VERSION "2021.24.4"

NS_ :

BS_:

BU_: VEH CH Receiver X

BA_DEF_ BO_ "GenMsgSendType" ENUM "Cyclic";
BA_DEF_ BO_ "GenMsgCycleTime" INT 0 10000;

BO_ 1083 VCSEC_peripheralOTAStatus: 8 Vector__XXX
 SG_ VCSEC_TPMSUpdateRetryLimitReached0 m0 : 59|1@1+ (1,0) [0|0] "" Vector__XXX
 SG_ VCSEC_TPMSUpdateRetryLimitReached1 m1 : 59|1@1+ (1,0) [0|0] "" Vector__XXX
 SG_ VCSEC_TPMSUpdateRetryLimitReached2 m2 : 59|1@1+ (1,0) [0|0] "" Vector__XXX
 SG_ VCSEC_TPMSUpdateRetryLimitReached3 m3 : 59|1@1+ (1,0) [0|0] "" Vector__XXX
 SG_ VCSEC_TPMSUpdateHasStarted0 m0 : 58|1@1+ (1,0) [0|0] "" Vector__XXX
 SG_ VCSEC_TPMSUpdateHasStarted1 m1 : 58|1@1+ (1,0) [0|0] "" Vector__XXX
 SG_ VCSEC_TPMSUpdateHasStarted2 m2 : 58|1@1+ (1,0) [0|0] "" Vector__XXX
 SG_ VCSEC_TPMSUpdateHasStarted3 m3 : 58|1@1+ (1,0) [0|0] "" Vector__XXX
 SG_ VCSEC_TPMSUpdateHasUpdated0 m0 : 57|1@1+ (1,0) [0|0] "" Vector__XXX
 SG_ VCSEC_TPMSUpdateHasUpdated1 m1 : 57|1@1+ (1,0) [0|0] "" Vector__XXX
 SG_ VCSEC_TPMSUpdateHasUpdated2 m2 : 57|1@1+ (1,0) [0|0] "" Vector__XXX
 SG_ VCSEC_TPMSUpdateHasUpdated3 m3 : 57|1@1+ (1,0) [0|0] "" Vector__XXX
 SG_ VCSEC_keyWhitelistIndexBeingUpdated m4 : 57|5@1+ (1,0) [0|0] "" Vector__XXX
 SG_ VCSEC_KeyfobUpdateExpectReconnect m4 : 56|1@1+ (1,0) [0|0] "" Vector__XXX
 SG_ VCSEC_TPMSUpdateExpectReconnect0 m0 : 56|1@1+ (1,0) [0|0] "" Vector__XXX
 SG_ VCSEC_TPMSUpdateExpectReconnect1 m1 : 56|1@1+ (1,0) [0|0] "" Vector__XXX
 SG_ VCSEC_TPMSUpdateExpectReconnect2 m2 : 56|1@1+ (1,0) [0|0] "" Vector__XXX
 SG_ VCSEC_TPMSUpdateExpectReconnect3 m3 : 56|1@1+ (1,0) [0|0] "" Vector__XXX
 SG_ VCSEC_KeyfobUpdateWaitForFlashCount m4 : 52|4@1+ (1,0) [0|0] "" Vector__XXX
 SG_ VCSEC_TPMSUpdateWaitForFlashCount0 m0 : 52|4@1+ (1,0) [0|0] "" Vector__XXX
 SG_ VCSEC_TPMSUpdateWaitForFlashCount1 m1 : 52|4@1+ (1,0) [0|0] "" Vector__XXX
 SG_ VCSEC_TPMSUpdateWaitForFlashCount2 m2 : 52|4@1+ (1,0) [0|0] "" Vector__XXX
 SG_ VCSEC_TPMSUpdateWaitForFlashCount3 m3 : 52|4@1+ (1,0) [0|0] "" Vector__XXX
 SG_ VCSEC_KeyfobUpdateStalledBlockCount m4 : 48|4@1+ (1,0) [0|0] "" Vector__XXX
 SG_ VCSEC_TPMSUpdateStalledBlockCount0 m0 : 48|4@1+ (1,0) [0|0] "" Vector__XXX
 SG_ VCSEC_TPMSUpdateStalledBlockCount1 m1 : 48|4@1+ (1,0) [0|0] "" Vector__XXX
 SG_ VCSEC_TPMSUpdateStalledBlockCount2 m2 : 48|4@1+ (1,0) [0|0] "" Vector__XXX
 SG_ VCSEC_TPMSUpdateStalledBlockCount3 m3 : 48|4@1+ (1,0) [0|0] "" Vector__XXX
 SG_ VCSEC_KeyfobUpdateLocationSetCount m4 : 44|4@1+ (1,0) [0|0] "" Vector__XXX
 SG_ VCSEC_TPMSUpdateLocationSetCount0 m0 : 44|4@1+ (1,0) [0|0] "" Vector__XXX
 SG_ VCSEC_TPMSUpdateLocationSetCount1 m1 : 44|4@1+ (1,0) [0|0] "" Vector__XXX
 SG_ VCSEC_TPMSUpdateLocationSetCount2 m2 : 44|4@1+ (1,0) [0|0] "" Vector__XXX
 SG_ VCSEC_TPMSUpdateLocationSetCount3 m3 : 44|4@1+ (1,0) [0|0] "" Vector__XXX
 SG_ VCSEC_KeyfobUpdateCRCRequestTimeoutCount m4 : 40|4@1+ (1,0) [0|0] "" Vector__XXX
 SG_ VCSEC_TPMSUpdateCRCRequestTimeoutCount0 m0 : 40|4@1+ (1,0) [0|0] "" Vector__XXX
 SG_ VCSEC_TPMSUpdateCRCRequestTimeoutCount1 m1 : 40|4@1+ (1,0) [0|0] "" Vector__XXX
 SG_ VCSEC_TPMSUpdateCRCRequestTimeoutCount2 m2 : 40|4@1+ (1,0) [0|0] "" Vector__XXX
 SG_ VCSEC_TPMSUpdateCRCRequestTimeoutCount3 m3 : 40|4@1+ (1,0) [0|0] "" Vector__XXX
 SG_ VCSEC_KeyfobUpdateBlockErrorCount m4 : 36|4@1+ (1,0) [0|0] "" Vector__XXX
 SG_ VCSEC_TPMSUpdateBlockErrorCount0 m0 : 36|4@1+ (1,0) [0|0] "" Vector__XXX
 SG_ VCSEC_TPMSUpdateBlockErrorCount1 m1 : 36|4@1+ (1,0) [0|0] "" Vector__XXX
 SG_ VCSEC_TPMSUpdateBlockErrorCount2 m2 : 36|4@1+ (1,0) [0|0] "" Vector__XXX
 SG_ VCSEC_TPMSUpdateBlockErrorCount3 m3 : 36|4@1+ (1,0) [0|0] "" Vector__XXX
 SG_ VCSEC_KeyfobUpdateBlockTimeoutCount m4 : 32|4@1+ (1,0) [0|0] "" Vector__XXX
 SG_ VCSEC_TPMSUpdateBlockTimeoutCount0 m0 : 32|4@1+ (1,0) [0|0] "" Vector__XXX
 SG_ VCSEC_TPMSUpdateBlockTimeoutCount1 m1 : 32|4@1+ (1,0) [0|0] "" Vector__XXX
 SG_ VCSEC_TPMSUpdateBlockTimeoutCount2 m2 : 32|4@1+ (1,0) [0|0] "" Vector__XXX
 SG_ VCSEC_TPMSUpdateBlockTimeoutCount3 m3 : 32|4@1+ (1,0) [0|0] "" Vector__XXX
 SG_ VCSEC_KeyfobUpdateLastRespStatus m4 : 24|8@1+ (1,0) [0|0] "" Vector__XXX
 SG_ VCSEC_TPMSUpdateLastStatus0 m0 : 24|8@1+ (1,0) [0|0] "" Vector__XXX
 SG_ VCSEC_TPMSUpdateLastStatus1 m1 : 24|8@1+ (1,0) [0|0] "" Vector__XXX
 SG_ VCSEC_TPMSUpdateLastStatus2 m2 : 24|8@1+ (1,0) [0|0] "" Vector__XXX
 SG_ VCSEC_TPMSUpdateLastStatus3 m3 : 24|8@1+ (1,0) [0|0] "" Vector__XXX
 SG_ VCSEC_KeyfobUpdateLastTxStatus m4 : 16|8@1+ (1,0) [0|0] "" Vector__XXX
 SG_ VCSEC_TPMSUpdateState0 m0 : 16|8@1+ (1,0) [0|0] "" Vector__XXX
 SG_ VCSEC_TPMSUpdateState1 m1 : 16|8@1+ (1,0) [0|0] "" Vector__XXX
 SG_ VCSEC_TPMSUpdateState2 m2 : 16|8@1+ (1,0) [0|0] "" Vector__XXX
 SG_ VCSEC_TPMSUpdateState3 m3 : 16|8@1+ (1,0) [0|0] "" Vector__XXX
 SG_ VCSEC_KeyfobStagingProgress m4 : 8|7@1+ (1,0) [0|0] "" Vector__XXX
 SG_ VCSEC_TPMSStagingProgress0 m0 : 8|7@1+ (1,0) [0|0] "" Vector__XXX
 SG_ VCSEC_TPMSStagingProgress1 m1 : 8|7@1+ (1,0) [0|0] "" Vector__XXX
 SG_ VCSEC_TPMSStagingProgress2 m2 : 8|7@1+ (1,0) [0|0] "" Vector__XXX
 SG_ VCSEC_TPMSStagingProgress3 m3 : 8|7@1+ (1,0) [0|0] "" Vector__XXX
 SG_ VCSEC_peripheralOTAStatusIndex M : 0|3@1+ (1,0) [0|0] "" Vector__XXX

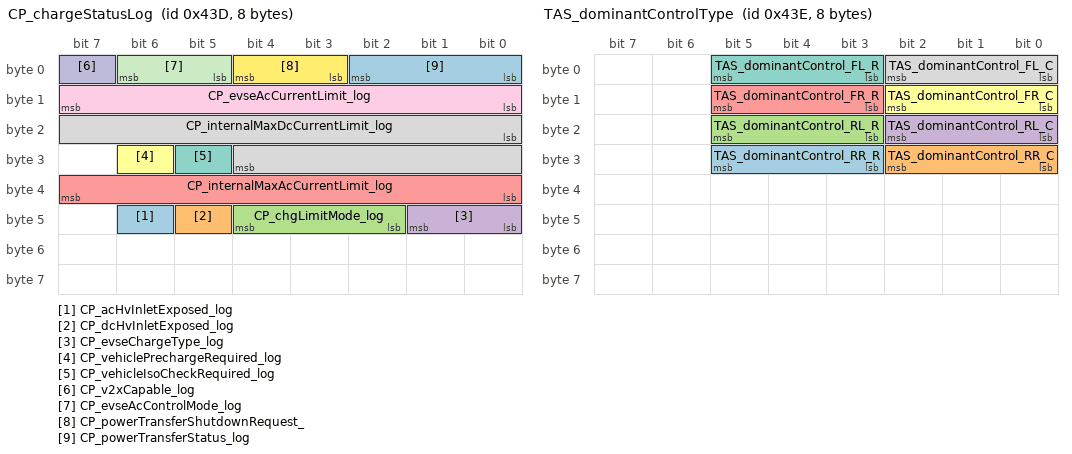
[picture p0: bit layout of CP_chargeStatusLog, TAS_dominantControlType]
BO_ 1085 CP_chargeStatusLog: 8 Vector__XXX
 SG_ CP_acHvInletExposed_log : 46|1@1+ (1,0) [0|0] "" Vector__XXX
 SG_ CP_dcHvInletExposed_log : 45|1@1+ (1,0) [0|0] "" Vector__XXX
 SG_ CP_chgLimitMode_log : 42|3@1+ (1,0) [0|0] "" Vector__XXX
 SG_ CP_evseChargeType_log : 40|2@1+ (1,0) [0|0] "" Vector__XXX
 SG_ CP_internalMaxAcCurrentLimit_log : 32|8@1+ (0.5,0) [0|0] "" Vector__XXX
 SG_ CP_vehiclePrechargeRequired_log : 30|1@1+ (1,0) [0|0] "" Vector__XXX
 SG_ CP_vehicleIsoCheckRequired_log : 29|1@1+ (1,0) [0|0] "" Vector__XXX
 SG_ CP_internalMaxDcCurrentLimit_log : 16|13@1+ (0.25,0) [0|0] "" Vector__XXX
 SG_ CP_evseAcCurrentLimit_log : 8|8@1+ (0.5,0) [0|0] "" Vector__XXX
 SG_ CP_v2xCapable_log : 7|1@1+ (1,0) [0|0] "" Vector__XXX
 SG_ CP_evseAcControlMode_log : 5|2@1+ (1,0) [0|0] "" Vector__XXX
 SG_ CP_powerTransferShutdownRequest_ : 3|2@1+ (1,0) [0|0] "" Vector__XXX
 SG_ CP_powerTransferStatus_log : 0|3@1+ (1,0) [0|0] "" Vector__XXX

BO_ 1086 TAS_dominantControlType: 8 Vector__XXX
 SG_ TAS_dominantControl_RR_R : 27|3@1+ (1,0) [0|0] "" Vector__XXX
 SG_ TAS_dominantControl_RR_C : 24|3@1+ (1,0) [0|0] "" Vector__XXX
 SG_ TAS_dominantControl_RL_R : 19|3@1+ (1,0) [0|0] "" Vector__XXX
 SG_ TAS_dominantControl_RL_C : 16|3@1+ (1,0) [0|0] "" Vector__XXX
 SG_ TAS_dominantControl_FR_R : 11|3@1+ (1,0) [0|0] "" Vector__XXX
 SG_ TAS_dominantControl_FR_C : 8|3@1+ (1,0) [0|0] "" Vector__XXX
 SG_ TAS_dominantControl_FL_R : 3|3@1+ (1,0) [0|0] "" Vector__XXX
 SG_ TAS_dominantControl_FL_C : 0|3@1+ (1,0) [0|0] "" Vector__XXX

BO_ 1089 VC_pcsInterface: 8 Vector__XXX
 SG_ VC_pcsInterfaceChecksum : 56|8@1+ (1,0) [0|0] "" Vector__XXX
 SG_ VC_pcsInterfaceCounter : 50|4@1+ (1,0) [0|0] "" Vector__XXX
 SG_ VC_pcsInterfaceMuxIndex M : 48|1@1+ (1,0) [0|0] "" Vector__XXX
 SG_ VC_LVBatteryCannotSupportVehicle m0 : 47|1@1+ (1,0) [0|0] "" Vector__XXX
 SG_ VC_goodForPCSPowerCycle m0 : 46|1@1+ (1,0) [0|0] "" Vector__XXX
 SG_ VC_lvBatteryDischargeRequest m1 : 42|1@1+ (1,0) [0|0] "" Vector__XXX
 SG_ VC_lvHwProtSelfTestActive m1 : 41|1@1+ (1,0) [0|0] "" Vector__XXX
 SG_ VC_defaultPcsLVVoltageTarget m1 : 28|13@1+ (0.01,0) [0|0] "" Vector__XXX
 SG_ VC_pcsLVMaxVoltageLimit m0 : 27|13@1+ (0.01,0) [0|0] "" Vector__XXX
 SG_ VC_pcsLVMaxDchrgCurrentLimit m1 : 16|12@1+ (0.1,0) [0|0] "" Vector__XXX
 SG_ VC_pcsLVMinVoltageLimit m0 : 13|13@1+ (0.01,0) [0|0] "" Vector__XXX
 SG_ VC_pcsLVVoltageTarget m0 : 0|13@1+ (0.01,0) [0|0] "" Vector__XXX
 SG_ VC_pcsResistanceFiltered m1 : 0|16@1+ (0.01,0) [0|0] "" Vector__XXX

BO_ 1090 VCBATT_pcsInterface: 8 Vector__XXX
 SG_ VCBATT_pcsInterfaceChecksum : 56|8@1+ (1,0) [0|0] "" Vector__XXX
 SG_ VCBATT_pcsInterfaceCounter : 50|4@1+ (1,0) [0|0] "" Vector__XXX
 SG_ VCBATT_pcsInterfaceMuxIndex M : 48|1@1+ (1,0) [0|0] "" Vector__XXX
 SG_ VCBATT_LVBatteryCannotSupportVeh m0 : 47|1@1+ (1,0) [0|0] "" Vector__XXX
 SG_ VCBATT_goodForPCSPowerCycle m0 : 46|1@1+ (1,0) [0|0] "" Vector__XXX
 SG_ VCBATT_lvBatteryDischargeRequest m1 : 42|1@1+ (1,0) [0|0] "" Vector__XXX
 SG_ VCBATT_lvHwProtSelfTestActive m1 : 41|1@1+ (1,0) [0|0] "" Vector__XXX
 SG_ VCBATT_defaultPcsLVVoltageTarget m1 : 28|13@1+ (0.01,0) [0|0] "" Vector__XXX
 SG_ VCBATT_pcsLVMaxVoltageLimit m0 : 27|13@1+ (0.01,0) [0|0] "" Vector__XXX
 SG_ VCBATT_pcsLVMaxDchrgCurrentLimit m1 : 16|12@1+ (0.1,0) [0|0] "" Vector__XXX
 SG_ VCBATT_pcsLVMinVoltageLimit m0 : 13|13@1+ (0.01,0) [0|0] "" Vector__XXX
 SG_ VCBATT_pcsLVVoltageTarget m0 : 0|13@1+ (0.01,0) [0|0] "" Vector__XXX
 SG_ VCBATT_pcsResistanceFiltered m1 : 0|16@1+ (0.01,0) [0|0] "" Vector__XXX

BO_ 1091 VC_pcsManagement: 6 Vector__XXX
 SG_ VC_dcdcLVInputPowerLimit m0 : 36|8@1+ (50,0) [0|0] "" Vector__XXX
 SG_ VC_dcdcLVVoltageTargetMin m0 : 26|10@1+ (0.1,0) [0|0] "" Vector__XXX
 SG_ VC_dcdcLVVoltageTargetMax m0 : 16|10@1+ (0.1,0) [0|0] "" Vector__XXX
 SG_ VC_pcsManagementMuxIndex M : 12|1@1+ (1,0) [0|0] "" Vector__XXX
 SG_ VC_pcsManagementCounter : 8|4@1+ (1,0) [0|0] "" Vector__XXX
 SG_ VC_pcsManagementChecksum : 0|8@1+ (1,0) [0|0] "" Vector__XXX

BO_ 1092 PCS2_alertLog: 8 Vector__XXX
 SG_ PCS2_alertSource : 60|4@1+ (1,0) [0|0] "" Vector__XXX
 SG_ PCS2_a107_packEOLGridFormEnableR m107 : 59|1@1+ (1,0) [0|0] "" Vector__XXX
 SG_ PCS2_a114_useLogarithmResult m114 : 59|1@1+ (1,0) [0|0] "" Vector__XXX
 SG_ PCS2_a153_L3_negative_flag m153 : 59|1@1+ (1,0) [0|0] "" Vector__XXX
 SG_ PCS2_a066_capacitanceOutOfSpec m66 : 58|1@1+ (1,0) [0|0] "" Vector__XXX
 SG_ PCS2_a067_capacitanceOutOfSpec m67 : 58|1@1+ (1,0) [0|0] "" Vector__XXX
 SG_ PCS2_a107_cpGridFormEnableReques m107 : 58|1@1+ (1,0) [0|0] "" Vector__XXX
 SG_ PCS2_a114_useLinearResult m114 : 58|1@1+ (1,0) [0|0] "" Vector__XXX
 SG_ PCS2_a153_charging_flag m153 : 58|1@1+ (1,0) [0|0] "" Vector__XXX
 SG_ PCS2_a168_reason m168 : 58|1@1+ (1,0) [0|0] "" Vector__XXX
 SG_ PCS2_a064_capacitanceOutOfSpec m64 : 57|1@1+ (1,0) [0|0] "" Vector__XXX
 SG_ PCS2_a065_capacitanceOutOfSpec m65 : 57|1@1+ (1,0) [0|0] "" Vector__XXX
 SG_ PCS2_a101_iticCurveSection m101 : 57|3@1+ (1,0) [0|0] "" Vector__XXX
 SG_ PCS2_a107_outletGridFormEnableRe m107 : 57|1@1+ (1,0) [0|0] "" Vector__XXX
 SG_ PCS2_a121_lvSensorReadingTooHigh m121 : 57|1@1+ (1,0) [0|0] "" Vector__XXX
 SG_ PCS2_a146_ac_harness_l2_l3_short m146 : 57|1@1+ (1,0) [0|0] "" Vector__XXX
 SG_ PCS2_a088_gridConfig m88 : 56|2@1+ (1,0) [0|0] "" Vector__XXX
 SG_ PCS2_a107_bmsEnableRequest m107 : 56|1@1+ (1,0) [0|0] "" Vector__XXX
 SG_ PCS2_a121_lvSensorToModeledTempD m121 : 56|1@1+ (1,0) [0|0] "" Vector__XXX
 SG_ PCS2_a136_resultExempted m136 : 56|1@1+ (1,0) [0|0] "" Vector__XXX
 SG_ PCS2_a137_resultExempted m137 : 56|1@1+ (1,0) [0|0] "" Vector__XXX
 SG_ PCS2_a146_legs_paralleled_by_rel m146 : 56|1@1+ (1,0) [0|0] "" Vector__XXX
 SG_ PCS2_a148_acRelayState m148 : 56|3@1+ (1,0) [0|0] "" Vector__XXX
 SG_ PCS2_a121_lvSensorToLocalCoolant m121 : 55|1@1+ (1,0) [0|0] "" Vector__XXX
 SG_ PCS2_a124_tankMargin m124 : 55|4@1+ (0.1,1) [0|0] "" Vector__XXX
 SG_ PCS2_a136_lvBusVoltageTripHasOcc m136 : 55|1@1+ (1,0) [0|0] "" Vector__XXX
 SG_ PCS2_a137_lvBusVoltageTripHasOcc m137 : 55|1@1+ (1,0) [0|0] "" Vector__XXX
 SG_ PCS2_a121_localRemoteCoolantDelt m121 : 54|1@1+ (1,0) [0|0] "" Vector__XXX
 SG_ PCS2_a136_hvBusVoltageTripHasOcc m136 : 54|1@1+ (1,0) [0|0] "" Vector__XXX
 SG_ PCS2_a137_hvBusVoltageTripHasOcc m137 : 54|1@1+ (1,0) [0|0] "" Vector__XXX
 SG_ PCS2_a033_alertThreshold m33 : 53|7@1+ (1,0) [0|0] "" Vector__XXX
 SG_ PCS2_a062_acL2L3Vrms m62 : 53|7@1+ (3,0) [0|0] "" Vector__XXX
 SG_ PCS2_a063_L2L3AvailableForChargi m63 : 53|1@1+ (1,0) [0|0] "" Vector__XXX
 SG_ PCS2_a110_junctionTempDeratingFa m110 : 53|7@1+ (0.01,0) [0|0] "" Vector__XXX
 SG_ PCS2_a118_failedToReachFixedTarg m118 : 53|1@1+ (1,0) [0|0] "" Vector__XXX
 SG_ PCS2_a121_cycloBActive m121 : 53|1@1+ (1,0) [0|0] "" Vector__XXX
 SG_ PCS2_a132_currentLimit m132 : 53|7@1+ (1,0) [0|0] "" Vector__XXX
 SG_ PCS2_a136_powerRailTripHasOccurr m136 : 53|1@1+ (1,0) [0|0] "" Vector__XXX
 SG_ PCS2_a137_powerRailTripHasOccurr m137 : 53|1@1+ (1,0) [0|0] "" Vector__XXX
 SG_ PCS2_a175_DcdcModelHvMosfetTemp m175 : 53|7@1+ (1,50) [0|0] "" Vector__XXX
 SG_ PCS2_a063_L1L3AvailableForChargi m63 : 52|1@1+ (1,0) [0|0] "" Vector__XXX
 SG_ PCS2_a109_acL2L3PeakVoltage m109 : 52|8@1+ (5,0) [0|0] "" Vector__XXX
 SG_ PCS2_a121_cycloAActive m121 : 52|1@1+ (1,0) [0|0] "" Vector__XXX
 SG_ PCS2_a136_lineOverVoltageTripHas m136 : 52|1@1+ (1,0) [0|0] "" Vector__XXX
 SG_ PCS2_a137_lineOverVoltageTripHas m137 : 52|1@1+ (1,0) [0|0] "" Vector__XXX
 SG_ PCS2_a163_hvBusVoltage m163 : 52|7@1+ (10,100) [0|0] "" Vector__XXX
 SG_ PCS2_a063_L1L2AvailableForChargi m63 : 51|1@1+ (1,0) [0|0] "" Vector__XXX
 SG_ PCS2_a092_hvBusVoltage m92 : 51|7@1+ (10,100) [0|0] "" Vector__XXX
 SG_ PCS2_a121_dcdcAHasHigherLvModele m121 : 51|1@1+ (1,0) [0|0] "" Vector__XXX
 SG_ PCS2_a136_lineOverCurrentTripHas m136 : 51|1@1+ (1,0) [0|0] "" Vector__XXX
 SG_ PCS2_a137_lineOverCurrentTripHas m137 : 51|1@1+ (1,0) [0|0] "" Vector__XXX
 SG_ PCS2_a063_L3NAvailableForChargin m63 : 50|1@1+ (1,0) [0|0] "" Vector__XXX
 SG_ PCS2_a102_iticCurveSection m102 : 50|3@1+ (1,0) [0|0] "" Vector__XXX
 SG_ PCS2_a107_line_3_error m107 : 50|6@1+ (10,0) [0|0] "" Vector__XXX
 SG_ PCS2_a121_dcdcAHasHigherLvTemp m121 : 50|1@1+ (1,0) [0|0] "" Vector__XXX
 SG_ PCS2_a124_L3InstantaneousCurrent m124 : 50|5@1- (10,0) [0|0] "" Vector__XXX
 SG_ PCS2_a129_commandedSwitchFreq m129 : 50|10@1+ (1,150) [0|0] "" Vector__XXX
 SG_ PCS2_a136_hvdcOverCurrentTripHas m136 : 50|1@1+ (1,0) [0|0] "" Vector__XXX
 SG_ PCS2_a137_hvdcOverCurrentTripHas m137 : 50|1@1+ (1,0) [0|0] "" Vector__XXX
 SG_ PCS2_a036_voltageFaultThreshold m36 : 49|11@1+ (1,0) [0|0] "" Vector__XXX
 SG_ PCS2_a037_voltageFaultThreshold m37 : 49|11@1+ (1,0) [0|0] "" Vector__XXX
 SG_ PCS2_a038_voltageFaultThreshold m38 : 49|11@1+ (1,0) [0|0] "" Vector__XXX
 SG_ PCS2_a039_voltageFaultThreshold m39 : 49|11@1+ (1,0) [0|0] "" Vector__XXX
 SG_ PCS2_a040_voltageFaultThreshold m40 : 49|11@1+ (1,0) [0|0] "" Vector__XXX
 SG_ PCS2_a041_voltageFaultThreshold m41 : 49|11@1+ (1,0) [0|0] "" Vector__XXX
 SG_ PCS2_a042_voltageFaultThreshold m42 : 49|11@1+ (1,0) [0|0] "" Vector__XXX
 SG_ PCS2_a043_voltageFaultThreshold m43 : 49|11@1+ (1,0) [0|0] "" Vector__XXX
 SG_ PCS2_a044_voltageFaultThreshold m44 : 49|11@1+ (1,0) [0|0] "" Vector__XXX
 SG_ PCS2_a045_voltageFaultThreshold m45 : 49|11@1+ (1,0) [0|0] "" Vector__XXX
 SG_ PCS2_a046_voltageFaultThreshold m46 : 49|11@1+ (1,0) [0|0] "" Vector__XXX
 SG_ PCS2_a047_voltageFaultThreshold m47 : 49|11@1+ (1,0) [0|0] "" Vector__XXX
 SG_ PCS2_a048_voltageFaultThreshold m48 : 49|11@1+ (1,0) [0|0] "" Vector__XXX
 SG_ PCS2_a049_voltageFaultThreshold m49 : 49|11@1+ (1,0) [0|0] "" Vector__XXX
 SG_ PCS2_a063_L2NAvailableForChargin m63 : 49|1@1+ (1,0) [0|0] "" Vector__XXX
 SG_ PCS2_a121_dcdcBActive m121 : 49|1@1+ (1,0) [0|0] "" Vector__XXX
 SG_ PCS2_a136_dcacEnableLineDeassert m136 : 49|1@1+ (1,0) [0|0] "" Vector__XXX
 SG_ PCS2_a137_dcacEnableLineDeassert m137 : 49|1@1+ (1,0) [0|0] "" Vector__XXX
 SG_ PCS2_a162_storedTankCapacitance m162 : 49|10@1+ (0.1,50) [0|0] "" Vector__XXX
 SG_ PCS2_a063_L1NAvailableForChargin m63 : 48|1@1+ (1,0) [0|0] "" Vector__XXX
 SG_ PCS2_a064_capacitance m64 : 48|9@1+ (0.05,15) [0|0] "" Vector__XXX
 SG_ PCS2_a065_capacitance m65 : 48|9@1+ (0.05,15) [0|0] "" Vector__XXX
 SG_ PCS2_a066_capacitance m66 : 48|10@1+ (0.1,50) [0|0] "" Vector__XXX
 SG_ PCS2_a067_capacitance m67 : 48|10@1+ (0.1,50) [0|0] "" Vector__XXX
 SG_ PCS2_a090_DcDcModelLVMosfetCurre m90 : 48|7@1+ (1,0) [0|0] "" Vector__XXX
 SG_ PCS2_a091_DcDcModelTxWindingCurr m91 : 48|7@1+ (1,0) [0|0] "" Vector__XXX
 SG_ PCS2_a099_iticCurveSection m99 : 48|3@1+ (1,0) [0|0] "" Vector__XXX
 SG_ PCS2_a103_ClosedLoopTime m103 : 48|11@1+ (50,0) [0|0] "" Vector__XXX
 SG_ PCS2_a113_remoteNoFlowDetectionS m113 : 48|1@1+ (1,0) [0|0] "" Vector__XXX
 SG_ PCS2_a121_dcdcAActive m121 : 48|1@1+ (1,0) [0|0] "" Vector__XXX
 SG_ PCS2_a136_pwmTrippedDuringHealth m136 : 48|1@1+ (1,0) [0|0] "" Vector__XXX
 SG_ PCS2_a137_pwmTrippedDuringHealth m137 : 48|1@1+ (1,0) [0|0] "" Vector__XXX
 SG_ PCS2_a147_BuckBoostLVInputOVThre m147 : 48|5@1+ (1,0) [0|0] "" Vector__XXX
 SG_ PCS2_a148_l3nPreRelayVoltage m148 : 48|7@1- (10,0) [0|0] "" Vector__XXX
 SG_ PCS2_a153_switching_freq_kHz m153 : 48|10@1+ (1,150) [0|0] "" Vector__XXX
 SG_ PCS2_a158_DcDcModelHvMosfetCurre m158 : 48|7@1+ (1,0) [0|0] "" Vector__XXX
 SG_ PCS2_a164_commandedSwitchFreq m164 : 48|10@1+ (1,150) [0|0] "" Vector__XXX
 SG_ PCS2_a165_tankCurrentCommand m165 : 48|11@1+ (0.1,0) [0|0] "" Vector__XXX
 SG_ PCS2_a064_magnetizingInductanceO m64 : 47|1@1+ (1,0) [0|0] "" Vector__XXX
 SG_ PCS2_a065_magnetizingInductanceO m65 : 47|1@1+ (1,0) [0|0] "" Vector__XXX
 SG_ PCS2_a066_magnetizingInductanceO m66 : 47|1@1+ (1,0) [0|0] "" Vector__XXX
 SG_ PCS2_a067_magnetizingInductanceO m67 : 47|1@1+ (1,0) [0|0] "" Vector__XXX
 SG_ PCS2_a088_presentCurrentRms m88 : 47|9@1+ (2,0) [0|0] "" Vector__XXX
 SG_ PCS2_a101_overVoltageThreshold m101 : 47|10@1- (1,0) [0|0] "" Vector__XXX
 SG_ PCS2_a113_localNoFlowDetectionSt m113 : 47|1@1+ (1,0) [0|0] "" Vector__XXX
 SG_ PCS2_a136_acVoltagePresent m136 : 47|1@1+ (1,0) [0|0] "" Vector__XXX
 SG_ PCS2_a137_acVoltagePresent m137 : 47|1@1+ (1,0) [0|0] "" Vector__XXX
 SG_ PCS2_a062_acL1L3Vrms m62 : 46|7@1+ (3,0) [0|0] "" Vector__XXX
 SG_ PCS2_a110_inductorLossDeratingFa m110 : 46|7@1+ (0.01,0) [0|0] "" Vector__XXX
 SG_ PCS2_a146_legN_Irms m146 : 46|10@1+ (0.1,0) [0|0] "" Vector__XXX
 SG_ PCS2_a175_DcdcModelLvMosfetTemp m175 : 46|7@1+ (1,50) [0|0] "" Vector__XXX
 SG_ PCS2_a005_acL1MinThreshold m5 : 45|13@1- (0.1,0) [0|0] "" Vector__XXX
 SG_ PCS2_a007_acL2MinThreshold m7 : 45|13@1- (0.1,0) [0|0] "" Vector__XXX
 SG_ PCS2_a009_acL3MinThreshold m9 : 45|13@1- (0.1,0) [0|0] "" Vector__XXX
 SG_ PCS2_a033_cycleSkewPercentage m33 : 45|8@1+ (1,0) [0|0] "" Vector__XXX
 SG_ PCS2_a092_lvBusVoltage m92 : 45|6@1+ (1,1) [0|0] "" Vector__XXX
 SG_ PCS2_a124_L2InstantaneousCurrent m124 : 45|5@1- (10,0) [0|0] "" Vector__XXX
 SG_ PCS2_a132_L3NGridVoltage m132 : 45|8@1+ (2,0) [0|0] "" Vector__XXX
 SG_ PCS2_a107_line_2_error m107 : 44|6@1+ (10,0) [0|0] "" Vector__XXX
 SG_ PCS2_a109_acL1L3PeakVoltage m109 : 44|8@1+ (5,0) [0|0] "" Vector__XXX
 SG_ PCS2_a168_timeBelow30pct m168 : 44|14@1+ (0.002,0) [0|0] "" Vector__XXX
 SG_ PCS2_a129_instantMeasuredZCDHalf m129 : 43|7@1+ (0.01,0) [0|0] "" Vector__XXX
 SG_ PCS2_a136_retryCount m136 : 43|4@1+ (1,0) [0|0] "" Vector__XXX
 SG_ PCS2_a137_retryCount m137 : 43|4@1+ (1,0) [0|0] "" Vector__XXX
 SG_ PCS2_a033_taskID m33 : 42|3@1+ (1,0) [0|0] "" Vector__XXX
 SG_ PCS2_a114_estimatedResistanceLog m114 : 42|16@1+ (10,0) [0|0] "" Vector__XXX
 SG_ PCS2_a162_hvBusVoltage m162 : 42|7@1+ (10,100) [0|0] "" Vector__XXX
 SG_ PCS2_a163_storedTankCapacitance m163 : 42|10@1+ (0.1,50) [0|0] "" Vector__XXX
 SG_ PCS2_a063_phase_diff_L1L3_L2L3 m63 : 40|8@1+ (1,0) [0|0] "" Vector__XXX
 SG_ PCS2_a075_hvBattTopBottomVoltage m75 : 40|11@1+ (1,0) [0|0] "" Vector__XXX
 SG_ PCS2_a076_hvBusTopBottomVoltageD m76 : 40|11@1+ (1,0) [0|0] "" Vector__XXX
 SG_ PCS2_a088_presentVoltageRms m88 : 40|7@1+ (3,0) [0|0] "" Vector__XXX
 SG_ PCS2_a090_DcDcModelLvMosfetCoola m90 : 40|8@1+ (0.2,0) [0|0] "" Vector__XXX
 SG_ PCS2_a091_DcDcModelTxWindingCool m91 : 40|8@1+ (0.2,0) [0|0] "" Vector__XXX
 SG_ PCS2_a099_overVoltageRmsThreshol m99 : 40|7@1+ (3,0) [0|0] "" Vector__XXX
 SG_ PCS2_a100_iticCurveSection m100 : 40|3@1+ (1,0) [0|0] "" Vector__XXX
 SG_ PCS2_a101_lineToChassisVoltageRm m101 : 40|7@1+ (3,0) [0|0] "" Vector__XXX
 SG_ PCS2_a102_overVoltageThreshold m102 : 40|10@1- (1,0) [0|0] "" Vector__XXX
 SG_ PCS2_a104_iticCurveSection m104 : 40|2@1+ (1,0) [0|0] "" Vector__XXX
 SG_ PCS2_a105_iticCurveSection m105 : 40|2@1+ (1,0) [0|0] "" Vector__XXX
 SG_ PCS2_a112_presentVoltageRms m112 : 40|7@1+ (3,0) [0|0] "" Vector__XXX
 SG_ PCS2_a118_presentLvBusVoltage m118 : 40|13@1+ (0.01,0) [0|0] "" Vector__XXX
 SG_ PCS2_a119_presentLvBusVoltage m119 : 40|13@1+ (0.01,0) [0|0] "" Vector__XXX
 SG_ PCS2_a121_localCoolantTemp m121 : 40|8@1- (1,46) [0|0] "" Vector__XXX
 SG_ PCS2_a124_L1InstantaneousCurrent m124 : 40|5@1- (10,0) [0|0] "" Vector__XXX
 SG_ PCS2_a127_dcac1_HealthCheckMaxRe m127 : 40|5@1+ (1,0) [0|0] "" Vector__XXX
 SG_ PCS2_a128_dcac2_HealthCheckMaxRe m128 : 40|5@1+ (1,0) [0|0] "" Vector__XXX
 SG_ PCS2_a147_18V0RailOverVoltageThr m147 : 40|5@1+ (1,0) [0|0] "" Vector__XXX
 SG_ PCS2_a148_l2nPreRelayVoltage m148 : 40|7@1- (10,0) [0|0] "" Vector__XXX
 SG_ PCS2_a153_zcd_half_period_pu m153 : 40|7@1+ (0.01,0) [0|0] "" Vector__XXX
 SG_ PCS2_a158_DcDcModelHvMosfetCoola m158 : 40|8@1+ (0.2,0) [0|0] "" Vector__XXX
 SG_ PCS2_a164_thetaS m164 : 40|7@1- (0.05,0) [0|0] "" Vector__XXX
 SG_ PCS2_a165_risingEdgeWindowPu m165 : 40|7@1+ (0.01,0) [0|0] "" Vector__XXX
 SG_ PCS2_a169_measuredResonantFreque m169 : 40|15@1+ (0.1,0) [0|0] "" Vector__XXX
 SG_ PCS2_a062_acL1L2Vrms m62 : 39|7@1+ (3,0) [0|0] "" Vector__XXX
 SG_ PCS2_a110_dcTempDeratingFactor m110 : 39|7@1+ (0.01,0) [0|0] "" Vector__XXX
 SG_ PCS2_a175_DcdcModelTxWindingTemp m175 : 39|7@1+ (1,50) [0|0] "" Vector__XXX
 SG_ PCS2_a028_CoolantSensorSource m28 : 38|1@1+ (1,0) [0|0] "" Vector__XXX
 SG_ PCS2_a036_hvBusBotVoltage m36 : 38|11@1+ (1,0) [0|0] "" Vector__XXX
 SG_ PCS2_a037_hvBusBotVoltage m37 : 38|11@1+ (1,0) [0|0] "" Vector__XXX
 SG_ PCS2_a038_hvBusBotVoltage m38 : 38|11@1+ (1,0) [0|0] "" Vector__XXX
 SG_ PCS2_a039_hvBusBotVoltage m39 : 38|11@1+ (1,0) [0|0] "" Vector__XXX
 SG_ PCS2_a040_hvBusBotVoltage m40 : 38|11@1+ (1,0) [0|0] "" Vector__XXX
 SG_ PCS2_a041_hvBusBotVoltage m41 : 38|11@1+ (1,0) [0|0] "" Vector__XXX
 SG_ PCS2_a042_hvBattBotVoltage m42 : 38|11@1+ (1,0) [0|0] "" Vector__XXX
 SG_ PCS2_a043_hvBattBotVoltage m43 : 38|11@1+ (1,0) [0|0] "" Vector__XXX
 SG_ PCS2_a044_hvBattBotVoltage m44 : 38|11@1+ (1,0) [0|0] "" Vector__XXX
 SG_ PCS2_a045_hvBattBotVoltage m45 : 38|11@1+ (1,0) [0|0] "" Vector__XXX
 SG_ PCS2_a046_hvBattBotVoltage m46 : 38|11@1+ (1,0) [0|0] "" Vector__XXX
 SG_ PCS2_a047_hvBattBotVoltage m47 : 38|11@1+ (1,0) [0|0] "" Vector__XXX
 SG_ PCS2_a048_hvBusBotVoltage m48 : 38|11@1+ (1,0) [0|0] "" Vector__XXX
 SG_ PCS2_a049_hvBusBotVoltage m49 : 38|11@1+ (1,0) [0|0] "" Vector__XXX
 SG_ PCS2_a107_line_1_error m107 : 38|6@1+ (10,0) [0|0] "" Vector__XXX
 SG_ PCS2_a092_hvBusCurrent m92 : 37|8@1- (0.2,0) [0|0] "" Vector__XXX
 SG_ PCS2_a103_FallTimeOpenLoop m103 : 37|11@1+ (50,0) [0|0] "" Vector__XXX
 SG_ PCS2_a132_L2NGridVoltage m132 : 37|8@1+ (2,0) [0|0] "" Vector__XXX
 SG_ PCS2_a109_acL1L2PeakVoltage m109 : 36|8@1+ (5,0) [0|0] "" Vector__XXX
 SG_ PCS2_a113_sensedCoolantTemp m113 : 36|11@1- (0.15,70.05) [0|0] "" Vector__XXX
 SG_ PCS2_a146_leg3_Irms m146 : 36|10@1+ (0.1,0) [0|0] "" Vector__XXX
 SG_ PCS2_a149_buckBoostRampTarget m149 : 36|12@1+ (0.01,0) [0|0] "" Vector__XXX
 SG_ PCS2_a140_halfBusHvBotVoltage m140 : 35|11@1+ (1,0) [0|0] "" Vector__XXX
 SG_ PCS2_a149_buckBoostRetryPrevente m149 : 35|1@1+ (1,0) [0|0] "" Vector__XXX
 SG_ PCS2_a169_mosfetIndexUnderTest m169 : 35|4@1+ (1,0) [0|0] "" Vector__XXX
 SG_ PCS2_a033_longestModuleUtilizati m33 : 34|8@1+ (1,0) [0|0] "" Vector__XXX
 SG_ PCS2_a129_instantMeasuredZCDEven m129 : 34|9@1+ (5,-1000) [0|0] "" Vector__XXX
 SG_ PCS2_a149_buckBoostLVUVCmpssFaul m149 : 34|1@1+ (1,0) [0|0] "" Vector__XXX
 SG_ PCS2_a170_detectedPhaseConfig m170 : 34|3@1+ (1,0) [0|0] "" Vector__XXX
 SG_ PCS2_a109_acRelayState m109 : 33|3@1+ (1,0) [0|0] "" Vector__XXX
 SG_ PCS2_a124_L3NInstantaneousVoltag m124 : 33|7@1- (10,0) [0|0] "" Vector__XXX
 SG_ PCS2_a149_buckBoostLVOVCmpssFaul m149 : 33|1@1+ (1,0) [0|0] "" Vector__XXX
 SG_ PCS2_a005_acL1MaxThreshold m5 : 32|13@1- (0.1,0) [0|0] "" Vector__XXX
 SG_ PCS2_a007_acL2MaxThreshold m7 : 32|13@1- (0.1,0) [0|0] "" Vector__XXX
 SG_ PCS2_a009_acL3MaxThreshold m9 : 32|13@1- (0.1,0) [0|0] "" Vector__XXX
 SG_ PCS2_a011_hvdcMinThreshold m11 : 32|13@1- (0.1,0) [0|0] "" Vector__XXX
 SG_ PCS2_a021_18V0RailUnderVoltageTh m21 : 32|5@1+ (1,0) [0|0] "" Vector__XXX
 SG_ PCS2_a034_voltageFaultThreshold m34 : 32|13@1+ (0.01,0) [0|0] "" Vector__XXX
 SG_ PCS2_a035_voltageFaultThreshold m35 : 32|13@1+ (0.01,0) [0|0] "" Vector__XXX
 SG_ PCS2_a062_acL3NVrms m62 : 32|7@1+ (3,0) [0|0] "" Vector__XXX
 SG_ PCS2_a063_phase_diff_L2N_L3N m63 : 32|8@1+ (1,0) [0|0] "" Vector__XXX
 SG_ PCS2_a064_magnetizingInductance m64 : 32|15@1+ (0.1,0) [0|0] "" Vector__XXX
 SG_ PCS2_a065_magnetizingInductance m65 : 32|15@1+ (0.1,0) [0|0] "" Vector__XXX
 SG_ PCS2_a066_magnetizingInductance m66 : 32|15@1+ (0.1,0) [0|0] "" Vector__XXX
 SG_ PCS2_a067_magnetizingInductance m67 : 32|15@1+ (0.1,0) [0|0] "" Vector__XXX
 SG_ PCS2_a077_lvBusExternalRefValue m77 : 32|13@1+ (0.01,0) [0|0] "" Vector__XXX
 SG_ PCS2_a078_acL1NVoltageRMS m78 : 32|7@1+ (3,0) [0|0] "" Vector__XXX
 SG_ PCS2_a079_acL2NVoltageRMS m79 : 32|7@1+ (3,0) [0|0] "" Vector__XXX
 SG_ PCS2_a080_acL3NVoltageRMS m80 : 32|7@1+ (3,0) [0|0] "" Vector__XXX
 SG_ PCS2_a086_voltageFaultThreshold m86 : 32|13@1+ (0.01,0) [0|0] "" Vector__XXX
 SG_ PCS2_a087_voltageFaultThreshold m87 : 32|13@1+ (0.01,0) [0|0] "" Vector__XXX
 SG_ PCS2_a088_underVoltageRmsThresho m88 : 32|7@1+ (3,0) [0|0] "" Vector__XXX
 SG_ PCS2_a092_zcd_fault_counter_limi m92 : 32|5@1+ (1,0) [0|0] "" Vector__XXX
 SG_ PCS2_a099_neutralToChassisVoltag m99 : 32|7@1+ (3,0) [0|0] "" Vector__XXX
 SG_ PCS2_a100_overVoltageRmsThreshol m100 : 32|7@1+ (3,0) [0|0] "" Vector__XXX
 SG_ PCS2_a101_neutralToChassisVoltag m101 : 32|8@1- (5,0) [0|0] "" Vector__XXX
 SG_ PCS2_a102_lineToLineVoltageRms m102 : 32|7@1+ (3,0) [0|0] "" Vector__XXX
 SG_ PCS2_a104_underVoltageRmsThresho m104 : 32|7@1+ (3,0) [0|0] "" Vector__XXX
 SG_ PCS2_a105_underVoltageRmsThresho m105 : 32|7@1+ (3,0) [0|0] "" Vector__XXX
 SG_ PCS2_a106_overVoltageThreshold m106 : 32|7@1+ (3,0) [0|0] "" Vector__XXX
 SG_ PCS2_a107_line_3_damper_current m107 : 32|6@1- (1,0) [0|0] "" Vector__XXX
 SG_ PCS2_a110_txTempDeratingFactor m110 : 32|7@1+ (0.01,0) [0|0] "" Vector__XXX
 SG_ PCS2_a112_underVoltageRmsThresho m112 : 32|7@1+ (3,0) [0|0] "" Vector__XXX
 SG_ PCS2_a121_remoteCoolantTemp m121 : 32|8@1- (1,46) [0|0] "" Vector__XXX
 SG_ PCS2_a127_dcac1_HealthCheckRetry m127 : 32|5@1+ (1,0) [0|0] "" Vector__XXX
 SG_ PCS2_a128_dcac2_HealthCheckRetry m128 : 32|5@1+ (1,0) [0|0] "" Vector__XXX
 SG_ PCS2_a147_10V0RailOverVoltageThr m147 : 32|5@1+ (1,0) [0|0] "" Vector__XXX
 SG_ PCS2_a148_l3nPostRelayVoltage m148 : 32|7@1- (10,0) [0|0] "" Vector__XXX
 SG_ PCS2_a149_buckBoost18VUVCmpssFau m149 : 32|1@1+ (1,0) [0|0] "" Vector__XXX
 SG_ PCS2_a150_burstOnCycles m150 : 32|3@1+ (1,0) [0|0] "" Vector__XXX
 SG_ PCS2_a153_zcd_falling_pu m153 : 32|7@1+ (0.01,0) [0|0] "" Vector__XXX
 SG_ PCS2_a164_thetaP m164 : 32|7@1- (0.05,0) [0|0] "" Vector__XXX
 SG_ PCS2_a165_fallingEdgeWindowPu m165 : 32|7@1+ (0.01,0) [0|0] "" Vector__XXX
 SG_ PCS2_a169_mosfetLegUnderTest m169 : 32|3@1+ (1,0) [0|0] "" Vector__XXX
 SG_ PCS2_a170_numberOfCycloStagesAva m170 : 32|2@1+ (1,0) [0|0] "" Vector__XXX
 SG_ PCS2_a149_buckBoost18VLeakyBucke m149 : 31|1@1+ (1,0) [0|0] "" Vector__XXX
 SG_ PCS2_a033_qualifyCounts m33 : 30|4@1+ (1,0) [0|0] "" Vector__XXX
 SG_ PCS2_a127_dcac1_hvEnableHealthSt m127 : 30|2@1+ (1,0) [0|0] "" Vector__XXX
 SG_ PCS2_a128_dcac2_hvEnableHealthSt m128 : 30|2@1+ (1,0) [0|0] "" Vector__XXX
 SG_ PCS2_a149_buckBoostInputOVFault m149 : 30|1@1+ (1,0) [0|0] "" Vector__XXX
 SG_ PCS2_a168_timeBelow50pct m168 : 30|14@1+ (0.002,0) [0|0] "" Vector__XXX
 SG_ PCS2_a109_acManagerOperatingMode m109 : 29|4@1+ (1,0) [0|0] "" Vector__XXX
 SG_ PCS2_a132_L1NGridVoltage m132 : 29|8@1+ (2,0) [0|0] "" Vector__XXX
 SG_ PCS2_a149_buckBoost18VOVFault m149 : 29|1@1+ (1,0) [0|0] "" Vector__XXX
 SG_ PCS2_a071_hvBattExternalRefValue m71 : 28|11@1+ (1,0) [0|0] "" Vector__XXX
 SG_ PCS2_a072_hvBattExternalRefValue m72 : 28|11@1+ (1,0) [0|0] "" Vector__XXX
 SG_ PCS2_a073_hvBusExternalRefValue m73 : 28|11@1+ (1,0) [0|0] "" Vector__XXX
 SG_ PCS2_a074_hvBusExternalRefValue m74 : 28|11@1+ (1,0) [0|0] "" Vector__XXX
 SG_ PCS2_a075_hvBattExternalRefValue m75 : 28|11@1+ (1,0) [0|0] "" Vector__XXX
 SG_ PCS2_a076_hvBusExternalRefValue m76 : 28|11@1+ (1,0) [0|0] "" Vector__XXX
 SG_ PCS2_a081_acL1CurrentRMS m81 : 28|11@1- (0.1,0) [0|0] "" Vector__XXX
 SG_ PCS2_a082_acL2CurrentRMS m82 : 28|11@1- (0.1,0) [0|0] "" Vector__XXX
 SG_ PCS2_a083_acL3CurrentRMS m83 : 28|11@1- (0.1,0) [0|0] "" Vector__XXX
 SG_ PCS2_a084_acNCurrentRMS m84 : 28|11@1- (0.1,0) [0|0] "" Vector__XXX
 SG_ PCS2_a092_zcd_threshold_at_fault m92 : 28|4@1+ (0.01,0) [0|0] "" Vector__XXX
 SG_ PCS2_a127_dcac1_dcTankClkHealthS m127 : 28|2@1+ (1,0) [0|0] "" Vector__XXX
 SG_ PCS2_a128_dcac2_dcTankClkHealthS m128 : 28|2@1+ (1,0) [0|0] "" Vector__XXX
 SG_ PCS2_a136_measuredResonantFreque m136 : 28|15@1+ (0.1,0) [0|0] "" Vector__XXX
 SG_ PCS2_a137_measuredResonantFreque m137 : 28|15@1+ (0.1,0) [0|0] "" Vector__XXX
 SG_ PCS2_a175_hvBusVoltage m175 : 28|11@1+ (1,0) [0|0] "" Vector__XXX
 SG_ PCS2_a013_DcdcALv2TempUpperThres m13 : 27|11@1- (0.15,70.05) [0|0] "" Vector__XXX
 SG_ PCS2_a015_DcdcAHvTempUpperThresh m15 : 27|11@1- (0.15,70.05) [0|0] "" Vector__XXX
 SG_ PCS2_a017_DcdcBLv2TempUpperThres m17 : 27|11@1- (0.15,70.05) [0|0] "" Vector__XXX
 SG_ PCS2_a019_DcacADcTempUpperThresh m19 : 27|11@1- (0.15,70.05) [0|0] "" Vector__XXX
 SG_ PCS2_a020_DcacBDcTempUpperThresh m20 : 27|11@1- (0.15,70.05) [0|0] "" Vector__XXX
 SG_ PCS2_a024_DcacATxTempUpperThresh m24 : 27|11@1- (0.15,70.05) [0|0] "" Vector__XXX
 SG_ PCS2_a025_DcacBTxTempUpperThresh m25 : 27|11@1- (0.15,70.05) [0|0] "" Vector__XXX
 SG_ PCS2_a026_AcConnectorTempUpperTh m26 : 27|11@1- (0.15,70.05) [0|0] "" Vector__XXX
 SG_ PCS2_a027_AmbientTempUpperThresh m27 : 27|11@1- (0.15,70.05) [0|0] "" Vector__XXX
 SG_ PCS2_a028_CoolantTempUpperThresh m28 : 27|11@1- (0.15,70.05) [0|0] "" Vector__XXX
 SG_ PCS2_a029_DcacAAc1TempUpperThres m29 : 27|11@1- (0.15,70.05) [0|0] "" Vector__XXX
 SG_ PCS2_a030_DcacAAc2TempUpperThres m30 : 27|11@1- (0.15,70.05) [0|0] "" Vector__XXX
 SG_ PCS2_a031_DcacBAc1TempUpperThres m31 : 27|11@1- (0.15,70.05) [0|0] "" Vector__XXX
 SG_ PCS2_a032_DcacBAc2TempUpperThres m32 : 27|11@1- (0.15,70.05) [0|0] "" Vector__XXX
 SG_ PCS2_a036_hvBusTopVoltage m36 : 27|11@1+ (1,0) [0|0] "" Vector__XXX
 SG_ PCS2_a037_hvBusTopVoltage m37 : 27|11@1+ (1,0) [0|0] "" Vector__XXX
 SG_ PCS2_a038_hvBusTopVoltage m38 : 27|11@1+ (1,0) [0|0] "" Vector__XXX
 SG_ PCS2_a039_hvBusTopVoltage m39 : 27|11@1+ (1,0) [0|0] "" Vector__XXX
 SG_ PCS2_a040_hvBusTopVoltage m40 : 27|11@1+ (1,0) [0|0] "" Vector__XXX
 SG_ PCS2_a041_hvBusTopVoltage m41 : 27|11@1+ (1,0) [0|0] "" Vector__XXX
 SG_ PCS2_a042_hvBattTopVoltage m42 : 27|11@1+ (1,0) [0|0] "" Vector__XXX
 SG_ PCS2_a043_hvBattTopVoltage m43 : 27|11@1+ (1,0) [0|0] "" Vector__XXX
 SG_ PCS2_a044_hvBattTopVoltage m44 : 27|11@1+ (1,0) [0|0] "" Vector__XXX
 SG_ PCS2_a045_hvBattTopVoltage m45 : 27|11@1+ (1,0) [0|0] "" Vector__XXX
 SG_ PCS2_a046_hvBattTopVoltage m46 : 27|11@1+ (1,0) [0|0] "" Vector__XXX
 SG_ PCS2_a047_hvBattTopVoltage m47 : 27|11@1+ (1,0) [0|0] "" Vector__XXX
 SG_ PCS2_a048_hvBusTopVoltage m48 : 27|11@1+ (1,0) [0|0] "" Vector__XXX
 SG_ PCS2_a049_hvBusTopVoltage m49 : 27|11@1+ (1,0) [0|0] "" Vector__XXX
 SG_ PCS2_a064_leakageInductanceOutOf m64 : 27|1@1+ (1,0) [0|0] "" Vector__XXX
 SG_ PCS2_a065_leakageInductanceOutOf m65 : 27|1@1+ (1,0) [0|0] "" Vector__XXX
 SG_ PCS2_a066_leakageInductanceOutOf m66 : 27|1@1+ (1,0) [0|0] "" Vector__XXX
 SG_ PCS2_a067_leakageInductanceOutOf m67 : 27|1@1+ (1,0) [0|0] "" Vector__XXX
 SG_ PCS2_a118_hvVoltageTarget m118 : 27|11@1+ (1,0) [0|0] "" Vector__XXX
 SG_ PCS2_a119_startUpHvVoltage m119 : 27|11@1+ (1,0) [0|0] "" Vector__XXX
 SG_ PCS2_a123_DcdcBHvTempUpperThresh m123 : 27|11@1- (0.15,70.05) [0|0] "" Vector__XXX
 SG_ PCS2_a126_ipcCpu3LockSuccessiveG m126 : 27|3@1+ (1,0) [0|0] "" Vector__XXX
 SG_ PCS2_a151_DcdcBLv1TempUpperThres m151 : 27|11@1- (0.15,70.05) [0|0] "" Vector__XXX
 SG_ PCS2_a152_DcdcBLv3TempUpperThres m152 : 27|11@1- (0.15,70.05) [0|0] "" Vector__XXX
 SG_ PCS2_a162_cycloTankMagInductance m162 : 27|15@1+ (0.1,0) [0|0] "" Vector__XXX
 SG_ PCS2_a163_cycloTankMagInductance m163 : 27|15@1+ (0.1,0) [0|0] "" Vector__XXX
 SG_ PCS2_a173_DcdcALv1TempUpperThres m173 : 27|11@1- (0.15,70.05) [0|0] "" Vector__XXX
 SG_ PCS2_a059_dcdcRequest m59 : 26|2@1+ (1,0) [0|0] "" Vector__XXX
 SG_ PCS2_a103_RiseTimeOpenLoop m103 : 26|11@1+ (50,0) [0|0] "" Vector__XXX
 SG_ PCS2_a114_estimatedResistanceLin m114 : 26|16@1+ (10,0) [0|0] "" Vector__XXX
 SG_ PCS2_a124_L2NInstantaneousVoltag m124 : 26|7@1- (10,0) [0|0] "" Vector__XXX
 SG_ PCS2_a127_dcac1_acTankClkHealthS m127 : 26|2@1+ (1,0) [0|0] "" Vector__XXX
 SG_ PCS2_a128_dcac2_acTankClkHealthS m128 : 26|2@1+ (1,0) [0|0] "" Vector__XXX
 SG_ PCS2_a146_leg2_Irms m146 : 26|10@1+ (0.1,0) [0|0] "" Vector__XXX
 SG_ PCS2_a169_sequence m169 : 26|4@1+ (1,0) [0|0] "" Vector__XXX
 SG_ PCS2_a001_cpuID m1 : 25|3@1+ (1,0) [0|0] "" Vector__XXX
 SG_ PCS2_a090_DcdcModelLvMosfetCoola m90 : 25|9@1- (1,106) [0|0] "" Vector__XXX
 SG_ PCS2_a091_DcdcModelTxWindingCool m91 : 25|9@1- (1,106) [0|0] "" Vector__XXX
 SG_ PCS2_a103_IsoTempSensorRiseFallM m103 : 25|1@1+ (1,0) [0|0] "" Vector__XXX
 SG_ PCS2_a109_chgMainStateMachineSta m109 : 25|4@1+ (1,0) [0|0] "" Vector__XXX
 SG_ PCS2_a113_receivedCoolantTemp m113 : 25|11@1- (0.15,70.05) [0|0] "" Vector__XXX
 SG_ PCS2_a116_maxChgRetriesAllowed m116 : 25|9@1+ (0.1,0) [0|0] "" Vector__XXX
 SG_ PCS2_a158_DcdcModelHvMosfetCoola m158 : 25|9@1- (1,106) [0|0] "" Vector__XXX
 SG_ PCS2_a001_debugger_warm_reset m1 : 24|1@1+ (1,0) [0|0] "" Vector__XXX
 SG_ PCS2_a002_canID m2 : 24|32@1+ (1,0) [0|0] "" Vector__XXX
 SG_ PCS2_a004_acManagerOperatingMode m4 : 24|4@1+ (1,0) [0|0] "" Vector__XXX
 SG_ PCS2_a005_acManagerOperatingMode m5 : 24|4@1+ (1,0) [0|0] "" Vector__XXX
 SG_ PCS2_a006_acManagerOperatingMode m6 : 24|4@1+ (1,0) [0|0] "" Vector__XXX
 SG_ PCS2_a007_acManagerOperatingMode m7 : 24|4@1+ (1,0) [0|0] "" Vector__XXX
 SG_ PCS2_a008_acManagerOperatingMode m8 : 24|4@1+ (1,0) [0|0] "" Vector__XXX
 SG_ PCS2_a009_acManagerOperatingMode m9 : 24|4@1+ (1,0) [0|0] "" Vector__XXX
 SG_ PCS2_a010_acManagerOperatingMode m10 : 24|4@1+ (1,0) [0|0] "" Vector__XXX
 SG_ PCS2_a021_10V0RailUnderVoltageTh m21 : 24|5@1+ (1,0) [0|0] "" Vector__XXX
 SG_ PCS2_a033_longestModuleIndex m33 : 24|6@1+ (1,0) [0|0] "" Vector__XXX
 SG_ PCS2_a059_dcdcStageRequestProces m59 : 24|2@1+ (1,0) [0|0] "" Vector__XXX
 SG_ PCS2_a060_pauseRequestedByDcdc m60 : 24|1@1+ (1,0) [0|0] "" Vector__XXX
 SG_ PCS2_a061_pauseRequestedByDcdc m61 : 24|1@1+ (1,0) [0|0] "" Vector__XXX
 SG_ PCS2_a062_acL2NVrms m62 : 24|7@1+ (3,0) [0|0] "" Vector__XXX
 SG_ PCS2_a063_phase_diff_L1N_L3N m63 : 24|8@1+ (1,0) [0|0] "" Vector__XXX
 SG_ PCS2_a068_diagnosticWord m68 : 24|32@1+ (1,0) [0|0] "" Vector__XXX
 SG_ PCS2_a088_startVoltageRms m88 : 24|7@1+ (3,0) [0|0] "" Vector__XXX
 SG_ PCS2_a099_lineToChassisVoltageRm m99 : 24|7@1+ (3,0) [0|0] "" Vector__XXX
 SG_ PCS2_a100_lineToLineVoltageRms m100 : 24|7@1+ (3,0) [0|0] "" Vector__XXX
 SG_ PCS2_a103_IsoTempSensorMIA m103 : 24|1@1+ (1,0) [0|0] "" Vector__XXX
 SG_ PCS2_a104_lineToChassisVoltageRm m104 : 24|7@1+ (3,0) [0|0] "" Vector__XXX
 SG_ PCS2_a105_lineToLineVoltageRms m105 : 24|7@1+ (3,0) [0|0] "" Vector__XXX
 SG_ PCS2_a106_systemNeutralToChassis m106 : 24|7@1+ (3,0) [0|0] "" Vector__XXX
 SG_ PCS2_a107_line_2_damper_current m107 : 24|6@1- (1,0) [0|0] "" Vector__XXX
 SG_ PCS2_a110_combinedDeratingFactor m110 : 24|7@1+ (0.01,0) [0|0] "" Vector__XXX
 SG_ PCS2_a112_startVoltageRms m112 : 24|7@1+ (3,0) [0|0] "" Vector__XXX
 SG_ PCS2_a121_maxDcdcLvModelTemp m121 : 24|8@1- (1,46) [0|0] "" Vector__XXX
 SG_ PCS2_a126_ipcCpu2LockSuccessiveG m126 : 24|3@1+ (1,0) [0|0] "" Vector__XXX
 SG_ PCS2_a127_dcac1_LNEnableHealthSt m127 : 24|2@1+ (1,0) [0|0] "" Vector__XXX
 SG_ PCS2_a128_dcac2_LNEnableHealthSt m128 : 24|2@1+ (1,0) [0|0] "" Vector__XXX
 SG_ PCS2_a129_lvBusVoltage m129 : 24|10@1+ (0.1,0) [0|0] "" Vector__XXX
 SG_ PCS2_a130_retriesAttempted m130 : 24|8@1+ (1,0) [0|0] "" Vector__XXX
 SG_ PCS2_a131_microgridHeartbeat2hzR m131 : 24|8@1+ (0.001,0) [0|0] "" Vector__XXX
 SG_ PCS2_a136_mosfetIndexUnderTest m136 : 24|4@1+ (1,0) [0|0] "" Vector__XXX
 SG_ PCS2_a137_mosfetIndexUnderTest m137 : 24|4@1+ (1,0) [0|0] "" Vector__XXX
 SG_ PCS2_a140_halfBusHvTopVoltage m140 : 24|11@1+ (1,0) [0|0] "" Vector__XXX
 SG_ PCS2_a147_4V5RailOverVoltageThre m147 : 24|5@1+ (1,0) [0|0] "" Vector__XXX
 SG_ PCS2_a148_l2nPostRelayVoltage m148 : 24|7@1- (10,0) [0|0] "" Vector__XXX
 SG_ PCS2_a149_buckBoostCmpssFaultCou m149 : 24|5@1+ (1,0) [0|0] "" Vector__XXX
 SG_ PCS2_a150_levelNotFinishedCounts m150 : 24|6@1+ (1,0) [0|0] "" Vector__XXX
 SG_ PCS2_a153_zcd_rising_pu m153 : 24|7@1+ (0.01,0) [0|0] "" Vector__XXX
 SG_ PCS2_a164_zcdRisingPu m164 : 24|7@1+ (0.01,0) [0|0] "" Vector__XXX
 SG_ PCS2_a165_dutyS m165 : 24|7@1+ (0.01,0) [0|0] "" Vector__XXX
 SG_ PCS2_a170_pcsMaxAcPowerCapabilit m170 : 24|8@1+ (0.1,0) [0|0] "" Vector__XXX
 SG_ PCS2_a172_vcrEfuseCommandedState m172 : 24|1@1+ (1,0) [0|0] "" Vector__XXX
 SG_ PCS2_a001_hardware_security_watc m1 : 23|1@1+ (1,0) [0|0] "" Vector__XXX
 SG_ PCS2_a103_IsoTempSensorRiseTimeO m103 : 23|1@1+ (1,0) [0|0] "" Vector__XXX
 SG_ PCS2_a172_vcrEfuseState m172 : 23|1@1+ (1,0) [0|0] "" Vector__XXX
 SG_ PCS2_a001_reset_pin_asserted m1 : 22|1@1+ (1,0) [0|0] "" Vector__XXX
 SG_ PCS2_a051_BMS_coolantStatus m51 : 22|1@1+ (1,0) [0|0] "" Vector__XXX
 SG_ PCS2_a103_IsoTempSensorFallTimeO m103 : 22|1@1+ (1,0) [0|0] "" Vector__XXX
 SG_ PCS2_a127_dcac1_L3EnableHealthSt m127 : 22|2@1+ (1,0) [0|0] "" Vector__XXX
 SG_ PCS2_a128_dcac2_L3EnableHealthSt m128 : 22|2@1+ (1,0) [0|0] "" Vector__XXX
 SG_ PCS2_a175_lvBusVoltageTarget m175 : 22|6@1+ (1,1) [0|0] "" Vector__XXX
 SG_ PCS2_a001_software_reset_request m1 : 21|1@1+ (1,0) [0|0] "" Vector__XXX
 SG_ PCS2_a004_gridFormStateMachineSt m4 : 21|3@1+ (1,0) [0|0] "" Vector__XXX
 SG_ PCS2_a005_gridFormStateMachineSt m5 : 21|3@1+ (1,0) [0|0] "" Vector__XXX
 SG_ PCS2_a006_gridFormStateMachineSt m6 : 21|3@1+ (1,0) [0|0] "" Vector__XXX
 SG_ PCS2_a007_gridFormStateMachineSt m7 : 21|3@1+ (1,0) [0|0] "" Vector__XXX
 SG_ PCS2_a008_gridFormStateMachineSt m8 : 21|3@1+ (1,0) [0|0] "" Vector__XXX
 SG_ PCS2_a009_gridFormStateMachineSt m9 : 21|3@1+ (1,0) [0|0] "" Vector__XXX
 SG_ PCS2_a010_gridFormStateMachineSt m10 : 21|3@1+ (1,0) [0|0] "" Vector__XXX
 SG_ PCS2_a051_HVBATT_pcsAuxRequest m51 : 21|1@1+ (1,0) [0|0] "" Vector__XXX
 SG_ PCS2_a085_packEOLGridFormEnableR m85 : 21|1@1+ (1,0) [0|0] "" Vector__XXX
 SG_ PCS2_a092_zcd_error_pu m92 : 21|7@1+ (0.01,0) [0|0] "" Vector__XXX
 SG_ PCS2_a103_IsoTempSenseOutOfBound m103 : 21|1@1+ (1,0) [0|0] "" Vector__XXX
 SG_ PCS2_a001_power_on_reset_trigger m1 : 20|1@1+ (1,0) [0|0] "" Vector__XXX
 SG_ PCS2_a051_BMS_packConfig m51 : 20|1@1+ (1,0) [0|0] "" Vector__XXX
 SG_ PCS2_a059_dcdcStageState m59 : 20|3@1+ (1,0) [0|0] "" Vector__XXX
 SG_ PCS2_a060_retryCount m60 : 20|4@1+ (1,0) [0|0] "" Vector__XXX
 SG_ PCS2_a061_retryCount m61 : 20|4@1+ (1,0) [0|0] "" Vector__XXX
 SG_ PCS2_a069_recordCRCMismatch m69 : 20|1@1+ (1,0) [0|0] "" Vector__XXX
 SG_ PCS2_a070_recordCRCMismatch m70 : 20|1@1+ (1,0) [0|0] "" Vector__XXX
 SG_ PCS2_a085_cpGridFormEnableReques m85 : 20|1@1+ (1,0) [0|0] "" Vector__XXX
 SG_ PCS2_a103_IsoTempSenseIrrational m103 : 20|1@1+ (1,0) [0|0] "" Vector__XXX
 SG_ PCS2_a122_recordCRCMismatch m122 : 20|1@1+ (1,0) [0|0] "" Vector__XXX
 SG_ PCS2_a127_dcac1_L2EnableHealthSt m127 : 20|2@1+ (1,0) [0|0] "" Vector__XXX
 SG_ PCS2_a128_dcac2_L2EnableHealthSt m128 : 20|2@1+ (1,0) [0|0] "" Vector__XXX
 SG_ PCS2_a136_mosfetLegUnderTest m136 : 20|3@1+ (1,0) [0|0] "" Vector__XXX
 SG_ PCS2_a137_mosfetLegUnderTest m137 : 20|3@1+ (1,0) [0|0] "" Vector__XXX
 SG_ PCS2_a172_dcdcStageState m172 : 20|3@1+ (1,0) [0|0] "" Vector__XXX
 SG_ PCS2_a001_CPU3_watchdog_alarmed m1 : 19|1@1+ (1,0) [0|0] "" Vector__XXX
 SG_ PCS2_a021_4V5RailUnderVoltageThr m21 : 19|5@1+ (1,0) [0|0] "" Vector__XXX
 SG_ PCS2_a051_BMS_pcsLimits m51 : 19|1@1+ (1,0) [0|0] "" Vector__XXX
 SG_ PCS2_a059_dcdcVcrEnableLineStatu m59 : 19|1@1+ (1,0) [0|0] "" Vector__XXX
 SG_ PCS2_a069_recordVersionMismatch m69 : 19|1@1+ (1,0) [0|0] "" Vector__XXX
 SG_ PCS2_a070_recordVersionMismatch m70 : 19|1@1+ (1,0) [0|0] "" Vector__XXX
 SG_ PCS2_a085_outletGridFormEnableRe m85 : 19|1@1+ (1,0) [0|0] "" Vector__XXX
 SG_ PCS2_a094_cycloBBlockedReason m94 : 19|3@1+ (1,0) [0|0] "" Vector__XXX
 SG_ PCS2_a095_cycloBBlockedReason m95 : 19|3@1+ (1,0) [0|0] "" Vector__XXX
 SG_ PCS2_a102_lineToLineVoltage m102 : 19|10@1- (1,0) [0|0] "" Vector__XXX
 SG_ PCS2_a122_recordVersionMismatch m122 : 19|1@1+ (1,0) [0|0] "" Vector__XXX
 SG_ PCS2_a124_L1NInstantaneousVoltag m124 : 19|7@1- (10,0) [0|0] "" Vector__XXX
 SG_ PCS2_a125_lnbn_state m125 : 19|1@1+ (1,0) [0|0] "" Vector__XXX
 SG_ PCS2_a126_ipcCpu1LockSuccessiveG m126 : 19|3@1+ (1,0) [0|0] "" Vector__XXX
 SG_ PCS2_a147_BuckBoostLVInputOVTrip m147 : 19|1@1+ (1,0) [0|0] "" Vector__XXX
 SG_ PCS2_a166_hvcEnableLineStatus m166 : 19|1@1+ (1,0) [0|0] "" Vector__XXX
 SG_ PCS2_a001_CPU2_watchdog_alarmed m1 : 18|1@1+ (1,0) [0|0] "" Vector__XXX
 SG_ PCS2_a021_18V0RailUnderVoltageTr m21 : 18|1@1+ (1,0) [0|0] "" Vector__XXX
 SG_ PCS2_a051_BMS_gridFormControl m51 : 18|1@1+ (1,0) [0|0] "" Vector__XXX
 SG_ PCS2_a052_CP_gridFormControl m52 : 18|1@1+ (1,0) [0|0] "" Vector__XXX
 SG_ PCS2_a055_magnetizingInductanceD m55 : 18|1@1+ (1,0) [0|0] "" Vector__XXX
 SG_ PCS2_a056_magnetizingInductanceD m56 : 18|1@1+ (1,0) [0|0] "" Vector__XXX
 SG_ PCS2_a057_magnetizingInductanceD m57 : 18|1@1+ (1,0) [0|0] "" Vector__XXX
 SG_ PCS2_a058_magnetizingInductanceD m58 : 18|1@1+ (1,0) [0|0] "" Vector__XXX
 SG_ PCS2_a059_dcdcVcrEnableLineTZLat m59 : 18|1@1+ (1,0) [0|0] "" Vector__XXX
 SG_ PCS2_a069_recordUndersized m69 : 18|1@1+ (1,0) [0|0] "" Vector__XXX
 SG_ PCS2_a070_recordUndersized m70 : 18|1@1+ (1,0) [0|0] "" Vector__XXX
 SG_ PCS2_a085_bmsEnableRequest m85 : 18|1@1+ (1,0) [0|0] "" Vector__XXX
 SG_ PCS2_a101_lineToChassisVoltage m101 : 18|10@1- (1,0) [0|0] "" Vector__XXX
 SG_ PCS2_a122_recordUndersized m122 : 18|1@1+ (1,0) [0|0] "" Vector__XXX
 SG_ PCS2_a125_lntn_state m125 : 18|1@1+ (1,0) [0|0] "" Vector__XXX
 SG_ PCS2_a127_dcac1_L1EnableHealthSt m127 : 18|2@1+ (1,0) [0|0] "" Vector__XXX
 SG_ PCS2_a128_dcac2_L1EnableHealthSt m128 : 18|2@1+ (1,0) [0|0] "" Vector__XXX
 SG_ PCS2_a142_AcLineGdpsDataStale m142 : 18|1@1+ (1,0) [0|0] "" Vector__XXX
 SG_ PCS2_a143_AcTankGdpsDataStale m143 : 18|1@1+ (1,0) [0|0] "" Vector__XXX
 SG_ PCS2_a144_DcTankGdpsDataStale m144 : 18|1@1+ (1,0) [0|0] "" Vector__XXX
 SG_ PCS2_a145_DcdcHvdcGdpsDataStale m145 : 18|1@1+ (1,0) [0|0] "" Vector__XXX
 SG_ PCS2_a147_18V0RailOverVoltageTri m147 : 18|1@1+ (1,0) [0|0] "" Vector__XXX
 SG_ PCS2_a150_previousBurstMode m150 : 18|2@1+ (1,0) [0|0] "" Vector__XXX
 SG_ PCS2_a166_vcrEnableLineStatus m166 : 18|1@1+ (1,0) [0|0] "" Vector__XXX
 SG_ PCS2_a172_dcdcInternalRequest m172 : 18|2@1+ (1,0) [0|0] "" Vector__XXX
 SG_ PCS2_a001_CPU1_watchdog_alarmed m1 : 17|1@1+ (1,0) [0|0] "" Vector__XXX
 SG_ PCS2_a004_chgMainStateMachineSta m4 : 17|4@1+ (1,0) [0|0] "" Vector__XXX
 SG_ PCS2_a005_chgMainStateMachineSta m5 : 17|4@1+ (1,0) [0|0] "" Vector__XXX
 SG_ PCS2_a006_chgMainStateMachineSta m6 : 17|4@1+ (1,0) [0|0] "" Vector__XXX
 SG_ PCS2_a007_chgMainStateMachineSta m7 : 17|4@1+ (1,0) [0|0] "" Vector__XXX
 SG_ PCS2_a008_chgMainStateMachineSta m8 : 17|4@1+ (1,0) [0|0] "" Vector__XXX
 SG_ PCS2_a009_chgMainStateMachineSta m9 : 17|4@1+ (1,0) [0|0] "" Vector__XXX
 SG_ PCS2_a010_chgMainStateMachineSta m10 : 17|4@1+ (1,0) [0|0] "" Vector__XXX
 SG_ PCS2_a011_hvdcMaxThreshold m11 : 17|13@1- (0.1,0) [0|0] "" Vector__XXX
 SG_ PCS2_a021_10V0RailUnderVoltageTr m21 : 17|1@1+ (1,0) [0|0] "" Vector__XXX
 SG_ PCS2_a051_BMS_chargeStatus m51 : 17|1@1+ (1,0) [0|0] "" Vector__XXX
 SG_ PCS2_a052_CP_status m52 : 17|1@1+ (1,0) [0|0] "" Vector__XXX
 SG_ PCS2_a053_HVP_hvsControl m53 : 17|1@1+ (1,0) [0|0] "" Vector__XXX
 SG_ PCS2_a055_leakageInductanceDefin m55 : 17|1@1+ (1,0) [0|0] "" Vector__XXX
 SG_ PCS2_a056_leakageInductanceDefin m56 : 17|1@1+ (1,0) [0|0] "" Vector__XXX
 SG_ PCS2_a057_leakageInductanceDefin m57 : 17|1@1+ (1,0) [0|0] "" Vector__XXX
 SG_ PCS2_a058_leakageInductanceDefin m58 : 17|1@1+ (1,0) [0|0] "" Vector__XXX
 SG_ PCS2_a059_dcdcHvcEnableLineStatu m59 : 17|1@1+ (1,0) [0|0] "" Vector__XXX
 SG_ PCS2_a069_recordOversized m69 : 17|1@1+ (1,0) [0|0] "" Vector__XXX
 SG_ PCS2_a070_recordOversized m70 : 17|1@1+ (1,0) [0|0] "" Vector__XXX
 SG_ PCS2_a085_dcacTZFlagStatus m85 : 17|1@1+ (1,0) [0|0] "" Vector__XXX
 SG_ PCS2_a122_recordOversized m122 : 17|1@1+ (1,0) [0|0] "" Vector__XXX
 SG_ PCS2_a125_lnbp_state m125 : 17|1@1+ (1,0) [0|0] "" Vector__XXX
 SG_ PCS2_a142_AcLineGdpsDataOutOfSpe m142 : 17|1@1+ (1,0) [0|0] "" Vector__XXX
 SG_ PCS2_a143_AcTankGdpsDataOutOfSpe m143 : 17|1@1+ (1,0) [0|0] "" Vector__XXX
 SG_ PCS2_a144_DcTankGdpsDataOutOfSpe m144 : 17|1@1+ (1,0) [0|0] "" Vector__XXX
 SG_ PCS2_a145_DcdcHvdcGdpsDataOutOfS m145 : 17|1@1+ (1,0) [0|0] "" Vector__XXX
 SG_ PCS2_a147_10V0RailOverVoltageTri m147 : 17|1@1+ (1,0) [0|0] "" Vector__XXX
 SG_ PCS2_a149_buckBoostRampFaultCoun m149 : 17|5@1+ (1,0) [0|0] "" Vector__XXX
 SG_ PCS2_a154_adcReferenceOutOfSpec m154 : 17|1@1+ (1,0) [0|0] "" Vector__XXX
 SG_ PCS2_a156_VCFRONT_sensors m156 : 17|1@1+ (1,0) [0|0] "" Vector__XXX
 SG_ PCS2_a166_hvcTZLatchStatus m166 : 17|1@1+ (1,0) [0|0] "" Vector__XXX
 SG_ PCS2_a001_CPU0_watchdog_alarmed m1 : 16|1@1+ (1,0) [0|0] "" Vector__XXX
 SG_ PCS2_a002_canRxErrorType m2 : 16|3@1+ (1,0) [0|0] "" Vector__XXX
 SG_ PCS2_a003_assertionCode m3 : 16|2@1+ (1,0) [0|0] "" Vector__XXX
 SG_ PCS2_a004_acL1NOverVoltageTrip m4 : 16|1@1+ (1,0) [0|0] "" Vector__XXX
 SG_ PCS2_a005_acL1OverCurrentTrip m5 : 16|1@1+ (1,0) [0|0] "" Vector__XXX
 SG_ PCS2_a006_acL2NOverVoltageTrip m6 : 16|1@1+ (1,0) [0|0] "" Vector__XXX
 SG_ PCS2_a007_acL2OverCurrentTrip m7 : 16|1@1+ (1,0) [0|0] "" Vector__XXX
 SG_ PCS2_a008_acL3NOverVoltageTrip m8 : 16|1@1+ (1,0) [0|0] "" Vector__XXX
 SG_ PCS2_a009_acL3OverCurrentTrip m9 : 16|1@1+ (1,0) [0|0] "" Vector__XXX
 SG_ PCS2_a010_acLNOverCurrentTrip m10 : 16|1@1+ (1,0) [0|0] "" Vector__XXX
 SG_ PCS2_a011_hvdcOverCurrentTrip m11 : 16|1@1+ (1,0) [0|0] "" Vector__XXX
 SG_ PCS2_a012_cycloATankOverCurrentT m12 : 16|1@1+ (1,0) [0|0] "" Vector__XXX
 SG_ PCS2_a013_DcdcALv2Temp m13 : 16|11@1- (0.15,70.05) [0|0] "" Vector__XXX
 SG_ PCS2_a014_cycloBTankOverCurrentT m14 : 16|1@1+ (1,0) [0|0] "" Vector__XXX
 SG_ PCS2_a015_DcdcAHvTemp m15 : 16|11@1- (0.15,70.05) [0|0] "" Vector__XXX
 SG_ PCS2_a016_dcdcATankOverCurrentTr m16 : 16|1@1+ (1,0) [0|0] "" Vector__XXX
 SG_ PCS2_a017_DcdcBLv2Temp m17 : 16|11@1- (0.15,70.05) [0|0] "" Vector__XXX
 SG_ PCS2_a018_dcdcBTankOverCurrentTr m18 : 16|1@1+ (1,0) [0|0] "" Vector__XXX
 SG_ PCS2_a019_DcacADcTemp m19 : 16|11@1- (0.15,70.05) [0|0] "" Vector__XXX
 SG_ PCS2_a020_DcacBDcTemp m20 : 16|11@1- (0.15,70.05) [0|0] "" Vector__XXX
 SG_ PCS2_a021_4V5RailUnderVoltageTri m21 : 16|1@1+ (1,0) [0|0] "" Vector__XXX
 SG_ PCS2_a024_DcacATxTemp m24 : 16|11@1- (0.15,70.05) [0|0] "" Vector__XXX
 SG_ PCS2_a025_DcacBTxTemp m25 : 16|11@1- (0.15,70.05) [0|0] "" Vector__XXX
 SG_ PCS2_a026_AcConnectorTemp m26 : 16|11@1- (0.15,70.05) [0|0] "" Vector__XXX
 SG_ PCS2_a027_AmbientTemp m27 : 16|11@1- (0.15,70.05) [0|0] "" Vector__XXX
 SG_ PCS2_a028_CoolantTemp m28 : 16|11@1- (0.15,70.05) [0|0] "" Vector__XXX
 SG_ PCS2_a029_DcacAAc1Temp m29 : 16|11@1- (0.15,70.05) [0|0] "" Vector__XXX
 SG_ PCS2_a030_DcacAAc2Temp m30 : 16|11@1- (0.15,70.05) [0|0] "" Vector__XXX
 SG_ PCS2_a031_DcacBAc1Temp m31 : 16|11@1- (0.15,70.05) [0|0] "" Vector__XXX
 SG_ PCS2_a032_DcacBAc2Temp m32 : 16|11@1- (0.15,70.05) [0|0] "" Vector__XXX
 SG_ PCS2_a033_taskUtilizationPercent m33 : 16|8@1+ (1,0) [0|0] "" Vector__XXX
 SG_ PCS2_a034_lvBusVoltage m34 : 16|13@1+ (0.01,0) [0|0] "" Vector__XXX
 SG_ PCS2_a035_lvBusVoltage m35 : 16|13@1+ (0.01,0) [0|0] "" Vector__XXX
 SG_ PCS2_a036_hvBusVoltage m36 : 16|11@1+ (1,0) [0|0] "" Vector__XXX
 SG_ PCS2_a037_hvBusVoltage m37 : 16|11@1+ (1,0) [0|0] "" Vector__XXX
 SG_ PCS2_a038_hvBusVoltage m38 : 16|11@1+ (1,0) [0|0] "" Vector__XXX
 SG_ PCS2_a039_hvBusVoltage m39 : 16|11@1+ (1,0) [0|0] "" Vector__XXX
 SG_ PCS2_a040_hvBusVoltage m40 : 16|11@1+ (1,0) [0|0] "" Vector__XXX
 SG_ PCS2_a041_hvBusVoltage m41 : 16|11@1+ (1,0) [0|0] "" Vector__XXX
 SG_ PCS2_a042_hvBattVoltage m42 : 16|11@1+ (1,0) [0|0] "" Vector__XXX
 SG_ PCS2_a043_hvBattVoltage m43 : 16|11@1+ (1,0) [0|0] "" Vector__XXX
 SG_ PCS2_a044_hvBattVoltage m44 : 16|11@1+ (1,0) [0|0] "" Vector__XXX
 SG_ PCS2_a045_hvBattVoltage m45 : 16|11@1+ (1,0) [0|0] "" Vector__XXX
 SG_ PCS2_a046_hvBattVoltage m46 : 16|11@1+ (1,0) [0|0] "" Vector__XXX
 SG_ PCS2_a047_hvBattVoltage m47 : 16|11@1+ (1,0) [0|0] "" Vector__XXX
 SG_ PCS2_a048_hvBusVoltage m48 : 16|11@1+ (1,0) [0|0] "" Vector__XXX
 SG_ PCS2_a049_hvBusVoltage m49 : 16|11@1+ (1,0) [0|0] "" Vector__XXX
 SG_ PCS2_a050_VC_pcsInterface m50 : 16|1@1+ (1,0) [0|0] "" Vector__XXX
 SG_ PCS2_a051_BMS_pcsRequest m51 : 16|1@1+ (1,0) [0|0] "" Vector__XXX
 SG_ PCS2_a052_CP_chargeStatus m52 : 16|1@1+ (1,0) [0|0] "" Vector__XXX
 SG_ PCS2_a053_HV_dcdcControl m53 : 16|1@1+ (1,0) [0|0] "" Vector__XXX
 SG_ PCS2_a054_UI_chargeRequest m54 : 16|1@1+ (1,0) [0|0] "" Vector__XXX
 SG_ PCS2_a055_tankCapacitanceDefined m55 : 16|1@1+ (1,0) [0|0] "" Vector__XXX
 SG_ PCS2_a056_tankCapacitanceDefined m56 : 16|1@1+ (1,0) [0|0] "" Vector__XXX
 SG_ PCS2_a057_tankCapacitanceDefined m57 : 16|1@1+ (1,0) [0|0] "" Vector__XXX
 SG_ PCS2_a058_tankCapacitanceDefined m58 : 16|1@1+ (1,0) [0|0] "" Vector__XXX
 SG_ PCS2_a059_dcdcHvcEnableLineTZLat m59 : 16|1@1+ (1,0) [0|0] "" Vector__XXX
 SG_ PCS2_a060_maxRetriesAllowed m60 : 16|4@1+ (1,0) [0|0] "" Vector__XXX
 SG_ PCS2_a061_maxRetriesAllowed m61 : 16|4@1+ (1,0) [0|0] "" Vector__XXX
 SG_ PCS2_a062_acL1NVrms m62 : 16|7@1+ (3,0) [0|0] "" Vector__XXX
 SG_ PCS2_a063_phase_diff_L1N_L2N m63 : 16|8@1+ (1,0) [0|0] "" Vector__XXX
 SG_ PCS2_a064_leakageInductance m64 : 16|11@1+ (0.1,0) [0|0] "" Vector__XXX
 SG_ PCS2_a065_leakageInductance m65 : 16|11@1+ (0.1,0) [0|0] "" Vector__XXX
 SG_ PCS2_a066_leakageInductance m66 : 16|11@1+ (0.1,0) [0|0] "" Vector__XXX
 SG_ PCS2_a067_leakageInductance m67 : 16|11@1+ (0.1,0) [0|0] "" Vector__XXX
 SG_ PCS2_a068_recordProblemBitfield m68 : 16|8@1+ (1,0) [0|0] "" Vector__XXX
 SG_ PCS2_a069_recordNotFound m69 : 16|1@1+ (1,0) [0|0] "" Vector__XXX
 SG_ PCS2_a070_recordNotFound m70 : 16|1@1+ (1,0) [0|0] "" Vector__XXX
 SG_ PCS2_a071_hvBattBotSensorMeasure m71 : 16|12@1- (1,0) [0|0] "" Vector__XXX
 SG_ PCS2_a072_hvBattTopSensorMeasure m72 : 16|12@1- (1,0) [0|0] "" Vector__XXX
 SG_ PCS2_a073_hvBusBotSensorMeasurem m73 : 16|12@1- (1,0) [0|0] "" Vector__XXX
 SG_ PCS2_a074_hvBusTopSensorMeasurem m74 : 16|12@1- (1,0) [0|0] "" Vector__XXX
 SG_ PCS2_a075_hvBattFullSensorMeasur m75 : 16|12@1- (1,0) [0|0] "" Vector__XXX
 SG_ PCS2_a076_hvBusFullSensorMeasure m76 : 16|12@1- (1,0) [0|0] "" Vector__XXX
 SG_ PCS2_a077_lvBusVoltageMeasuremen m77 : 16|13@1+ (0.01,0) [0|0] "" Vector__XXX
 SG_ PCS2_a078_acL1NVoltageOffset m78 : 16|13@1- (0.5,0) [0|0] "" Vector__XXX
 SG_ PCS2_a079_acL2NVoltageOffset m79 : 16|13@1- (0.5,0) [0|0] "" Vector__XXX
 SG_ PCS2_a080_acL3NVoltageOffset m80 : 16|13@1- (0.5,0) [0|0] "" Vector__XXX
 SG_ PCS2_a081_acL1CurrentOffset m81 : 16|12@1- (0.5,0) [0|0] "" Vector__XXX
 SG_ PCS2_a082_acL2CurrentOffset m82 : 16|12@1- (0.5,0) [0|0] "" Vector__XXX
 SG_ PCS2_a083_acL3CurrentOffset m83 : 16|12@1- (0.5,0) [0|0] "" Vector__XXX
 SG_ PCS2_a084_acNCurrentOffset m84 : 16|12@1- (0.5,0) [0|0] "" Vector__XXX
 SG_ PCS2_a085_dcacEnableLineStatus m85 : 16|1@1+ (1,0) [0|0] "" Vector__XXX
 SG_ PCS2_a086_lvBusVoltage m86 : 16|13@1+ (0.01,0) [0|0] "" Vector__XXX
 SG_ PCS2_a087_lvBusVoltage m87 : 16|13@1+ (0.01,0) [0|0] "" Vector__XXX
 SG_ PCS2_a088_linesFaulted m88 : 16|3@1+ (1,0) [0|0] "" Vector__XXX
 SG_ PCS2_a090_DcdcModelLvMosfetTemp m90 : 16|9@1- (1,106) [0|0] "" Vector__XXX
 SG_ PCS2_a091_DcdcModelTxWindingTemp m91 : 16|9@1- (1,106) [0|0] "" Vector__XXX
 SG_ PCS2_a092_zcd_alert_counts m92 : 16|5@1+ (1,0) [0|0] "" Vector__XXX
 SG_ PCS2_a094_cycloABlockedReason m94 : 16|3@1+ (1,0) [0|0] "" Vector__XXX
 SG_ PCS2_a095_cycloABlockedReason m95 : 16|3@1+ (1,0) [0|0] "" Vector__XXX
 SG_ PCS2_a096_VCSUPER_thermalStatus1 m96 : 16|1@1+ (1,0) [0|0] "" Vector__XXX
 SG_ PCS2_a097_GTW_carState m97 : 16|1@1+ (1,0) [0|0] "" Vector__XXX
 SG_ PCS2_a098_EGGRIGHT3_thermalComma m98 : 16|1@1+ (1,0) [0|0] "" Vector__XXX
 SG_ PCS2_a099_lineFaulted m99 : 16|2@1+ (1,0) [0|0] "" Vector__XXX
 SG_ PCS2_a100_linesFaulted m100 : 16|3@1+ (1,0) [0|0] "" Vector__XXX
 SG_ PCS2_a101_lineFaulted m101 : 16|2@1+ (1,0) [0|0] "" Vector__XXX
 SG_ PCS2_a102_linesFaulted m102 : 16|3@1+ (1,0) [0|0] "" Vector__XXX
 SG_ PCS2_a103_IsoTempSensor m103 : 16|4@1+ (1,0) [0|0] "" Vector__XXX
 SG_ PCS2_a104_lineFaulted m104 : 16|2@1+ (1,0) [0|0] "" Vector__XXX
 SG_ PCS2_a105_linesFaulted m105 : 16|3@1+ (1,0) [0|0] "" Vector__XXX
 SG_ PCS2_a106_systemNeutral m106 : 16|2@1+ (1,0) [0|0] "" Vector__XXX
 SG_ PCS2_a107_line_1_damper_current m107 : 16|6@1- (1,0) [0|0] "" Vector__XXX
 SG_ PCS2_a109_consecutiveTriggerEven m109 : 16|9@1+ (1,0) [0|0] "" Vector__XXX
 SG_ PCS2_a110_deratingFactorThreshol m110 : 16|7@1+ (0.01,0) [0|0] "" Vector__XXX
 SG_ PCS2_a112_linesFaulted m112 : 16|3@1+ (1,0) [0|0] "" Vector__XXX
 SG_ PCS2_a113_receivedCoolantFlow m113 : 16|9@1+ (0.1,0) [0|0] "" Vector__XXX
 SG_ PCS2_a114_estimatedHvbusCapacita m114 : 16|10@1+ (10,0) [0|0] "" Vector__XXX
 SG_ PCS2_a115_lineVoltage m115 : 16|7@1+ (3,0) [0|0] "" Vector__XXX
 SG_ PCS2_a116_chgRetryCount m116 : 16|9@1+ (0.1,0) [0|0] "" Vector__XXX
 SG_ PCS2_a117_VCRIGHT_LVHealth m117 : 16|1@1+ (1,0) [0|0] "" Vector__XXX
 SG_ PCS2_a118_presentHvBusVoltage m118 : 16|11@1+ (1,0) [0|0] "" Vector__XXX
 SG_ PCS2_a119_presentHvBusVoltage m119 : 16|11@1+ (1,0) [0|0] "" Vector__XXX
 SG_ PCS2_a120_logId m120 : 16|8@1+ (1,0) [0|0] "" Vector__XXX
 SG_ PCS2_a121_maxDcdcLvTemp m121 : 16|8@1- (1,46) [0|0] "" Vector__XXX
 SG_ PCS2_a122_recordNotFound m122 : 16|1@1+ (1,0) [0|0] "" Vector__XXX
 SG_ PCS2_a123_DcdcBHvTemp m123 : 16|11@1- (0.15,70.05) [0|0] "" Vector__XXX
 SG_ PCS2_a124_tankCurrentRef m124 : 16|3@1+ (10,100) [0|0] "" Vector__XXX
 SG_ PCS2_a125_lntp_state m125 : 16|1@1+ (1,0) [0|0] "" Vector__XXX
 SG_ PCS2_a126_ipcCpu0LockSuccessiveG m126 : 16|3@1+ (1,0) [0|0] "" Vector__XXX
 SG_ PCS2_a127_acLineClkHealthStatus m127 : 16|2@1+ (1,0) [0|0] "" Vector__XXX
 SG_ PCS2_a128_acLineClkHealthStatus m128 : 16|2@1+ (1,0) [0|0] "" Vector__XXX
 SG_ PCS2_a129_hvBusVoltage m129 : 16|7@1+ (10,100) [0|0] "" Vector__XXX
 SG_ PCS2_a130_serverStateAtRetry m130 : 16|3@1+ (1,0) [0|0] "" Vector__XXX
 SG_ PCS2_a131_microgridHeartbeat1hzR m131 : 16|8@1+ (0.001,0) [0|0] "" Vector__XXX
 SG_ PCS2_a132_gridFrequency m132 : 16|13@1+ (0.01,0) [0|0] "" Vector__XXX
 SG_ PCS2_a136_failedSequence m136 : 16|4@1+ (1,0) [0|0] "" Vector__XXX
 SG_ PCS2_a137_failedSequence m137 : 16|4@1+ (1,0) [0|0] "" Vector__XXX
 SG_ PCS2_a140_halfBusCompensation m140 : 16|7@1- (1,0) [0|0] "" Vector__XXX
 SG_ PCS2_a141_boostOverCurrentThresh m141 : 16|13@1- (0.1,0) [0|0] "" Vector__XXX
 SG_ PCS2_a142_AcLineGdpsDataMissing m142 : 16|1@1+ (1,0) [0|0] "" Vector__XXX
 SG_ PCS2_a143_AcTankGdpsDataMissing m143 : 16|1@1+ (1,0) [0|0] "" Vector__XXX
 SG_ PCS2_a144_DcTankGdpsDataMissing m144 : 16|1@1+ (1,0) [0|0] "" Vector__XXX
 SG_ PCS2_a145_DcdcHvdcGdpsDataMissin m145 : 16|1@1+ (1,0) [0|0] "" Vector__XXX
 SG_ PCS2_a146_leg1_Irms m146 : 16|10@1+ (0.1,0) [0|0] "" Vector__XXX
 SG_ PCS2_a147_4V5RailOverVoltageTrip m147 : 16|1@1+ (1,0) [0|0] "" Vector__XXX
 SG_ PCS2_a148_l1nPostRelayVoltage m148 : 16|7@1- (10,0) [0|0] "" Vector__XXX
 SG_ PCS2_a149_buckBoostPermanentFaul m149 : 16|1@1+ (1,0) [0|0] "" Vector__XXX
 SG_ PCS2_a150_presentBurstMode m150 : 16|2@1+ (1,0) [0|0] "" Vector__XXX
 SG_ PCS2_a151_DcdcBLv1Temp m151 : 16|11@1- (0.15,70.05) [0|0] "" Vector__XXX
 SG_ PCS2_a152_DcdcBLv3Temp m152 : 16|11@1- (0.15,70.05) [0|0] "" Vector__XXX
 SG_ PCS2_a153_zcd_alert_counts m153 : 16|5@1+ (1,0) [0|0] "" Vector__XXX
 SG_ PCS2_a154_adcReferenceDataMissin m154 : 16|1@1+ (1,0) [0|0] "" Vector__XXX
 SG_ PCS2_a155_VC_LVHealth m155 : 16|1@1+ (1,0) [0|0] "" Vector__XXX
 SG_ PCS2_a156_VCFRONT_coolant m156 : 16|1@1+ (1,0) [0|0] "" Vector__XXX
 SG_ PCS2_a157_VC_pcsManagement m157 : 16|1@1+ (1,0) [0|0] "" Vector__XXX
 SG_ PCS2_a158_DcdcModelHvMosfetTemp m158 : 16|9@1- (1,106) [0|0] "" Vector__XXX
 SG_ PCS2_a159_HVDCGdpsHealthStatus m159 : 16|2@1+ (1,0) [0|0] "" Vector__XXX
 SG_ PCS2_a160_VCLEFT_networkManageme m160 : 16|1@1+ (1,0) [0|0] "" Vector__XXX
 SG_ PCS2_a161_VCREAR_networkManageme m161 : 16|1@1+ (1,0) [0|0] "" Vector__XXX
 SG_ PCS2_a162_cycloTankLeakageInduct m162 : 16|11@1+ (0.1,0) [0|0] "" Vector__XXX
 SG_ PCS2_a163_cycloTankLeakageInduct m163 : 16|11@1+ (0.1,0) [0|0] "" Vector__XXX
 SG_ PCS2_a164_zcdFallingPu m164 : 16|7@1+ (0.01,0) [0|0] "" Vector__XXX
 SG_ PCS2_a165_dutyP m165 : 16|7@1+ (0.01,0) [0|0] "" Vector__XXX
 SG_ PCS2_a166_vcrTZLatchStatus m166 : 16|1@1+ (1,0) [0|0] "" Vector__XXX
 SG_ PCS2_a168_timeBelow70pct m168 : 16|14@1+ (0.002,0) [0|0] "" Vector__XXX
 SG_ PCS2_a169_measuredHalfPeriodDiff m169 : 16|10@1+ (1,0) [0|0] "" Vector__XXX
 SG_ PCS2_a170_pcsMaxAcPowerAvailable m170 : 16|8@1+ (0.1,0) [0|0] "" Vector__XXX
 SG_ PCS2_a172_dcdcExternalRequest m172 : 16|2@1+ (1,0) [0|0] "" Vector__XXX
 SG_ PCS2_a173_DcdcALv1Temp m173 : 16|11@1- (0.15,70.05) [0|0] "" Vector__XXX
 SG_ PCS2_a175_lvBusVoltage m175 : 16|6@1+ (1,1) [0|0] "" Vector__XXX
 SG_ PCS2_a178_logId m178 : 16|8@1+ (1,0) [0|0] "" Vector__XXX
 SG_ PCS2_alertSet : 15|1@1+ (1,0) [0|0] "" Vector__XXX
 SG_ PCS2_alertID M : 0|8@1+ (1,0) [0|0] "" Vector__XXX

BO_ 1106 BMS_voltageRegGain: 3 Vector__XXX
 SG_ BMS_driveGainKi : 10|11@1+ (1,0) [0|0] "" Vector__XXX
 SG_ BMS_driveGainKp : 0|10@1+ (8,0) [0|0] "" Vector__XXX

BO_ 1107 VEH_billing: 4 Vector__XXX
 SG_ VEH_pricebookId : 0|32@1+ (1,0) [0|0] "" Vector__XXX

BO_ 1114 VCRIGHT_AP_hvacState10Hz: 8 Vector__XXX
 SG_ VCRIGHT_AP_solarFluxOnLeftWindow m1 : 56|8@1+ (5,0) [0|0] "" Vector__XXX
 SG_ VCRIGHT_AP_tempDuctDefrost m0 : 56|8@1+ (0.5,-22) [0|0] "" Vector__XXX
 SG_ VCRIGHT_AP_hvacMassflowTarget m0 : 48|8@1+ (1,0) [0|0] "" Vector__XXX
 SG_ VCRIGHT_AP_solarFluxOnRightWindow m1 : 48|8@1+ (5,0) [0|0] "" Vector__XXX
 SG_ VCRIGHT_AP_hvacEstimateWindshieldRH m0 : 40|8@1+ (1,0) [0|0] "" Vector__XXX
 SG_ VCRIGHT_AP_turnCameraFanOffReason m1 : 38|3@1+ (1,0) [0|0] "" Vector__XXX
 SG_ VCRIGHT_AP_hvacAirDistributionMode m0 : 37|3@1+ (1,0) [0|0] "" Vector__XXX
 SG_ VCRIGHT_AP_turnForwardCameraHeaterOnReason m1 : 34|4@1+ (1,0) [0|0] "" Vector__XXX
 SG_ VCRIGHT_AP_hvacRecircDoorPercent m0 : 31|6@1+ (1.6,0) [0|0] "" Vector__XXX
 SG_ VCRIGHT_ah_defogSystemState m1 : 31|3@1+ (1,0) [0|0] "" Vector__XXX
 SG_ VCRIGHT_AP_cameraFanDutyRequest m1 : 24|7@1+ (1,0) [0|0] "" Vector__XXX
 SG_ VCRIGHT_AP_cabinTempSideGlassLeft m0 : 23|8@1+ (0.5,-40) [0|0] "" Vector__XXX
 SG_ VCRIGHT_ah_defoggingTimeNeeded m1 : 19|5@1+ (1,0) [0|0] "" Vector__XXX
 SG_ VCRIGHT_AP_cabinTempSideGlassRight m0 : 15|8@1+ (0.5,-40) [0|0] "" Vector__XXX
 SG_ VCRIGHT_ah_hvacFaultSurvivabilityTime m1 : 14|5@1+ (10,0) [0|0] "" Vector__XXX
 SG_ VCRIGHT_AP_cameraDefogType m1 : 11|3@1+ (1,0) [0|0] "" Vector__XXX
 SG_ VCRIGHT_AP_cabinTempWindshield m0 : 7|8@1+ (0.5,-40) [0|0] "" Vector__XXX
 SG_ VCRIGHT_AP_hvacModelInitStatus m0 : 4|3@1+ (1,0) [0|0] "" Vector__XXX
 SG_ VCRIGHT_AP_hvacFlashFoggingDetected m0 : 3|1@1+ (1,0) [0|0] "" Vector__XXX
 SG_ VCRIGHT_AP_autoDefogAvailable m0 : 2|1@1+ (1,0) [0|0] "" Vector__XXX
 SG_ VCRIGHT_AP_cameraTurnOnTime m1 : 2|9@1+ (5,0) [0|0] "" Vector__XXX
 SG_ VCRIGHT_AP_hvacState10HzIndex M : 0|2@1+ (1,0) [0|0] "" Vector__XXX

BO_ 1115 VCRIGHT_AP_hvacState0Point1Hz: 2 Vector__XXX
 SG_ VCRIGHT_AP_VOCPurgeRunCount m0 : 2|10@1+ (1,0) [0|0] "" Vector__XXX
 SG_ VCRIGHT_AP_hvacState0Point1HzIndex M : 0|1@1+ (1,0) [0|0] "" Vector__XXX

BO_ 1116 CC_alertLog: 8 Vector__XXX
 SG_ CC_a014_meterRetryCount m14 : 57|4@1+ (1,0) [0|0] "" Vector__XXX
 SG_ CC_a003_gfciFaultBucket m3 : 56|4@1+ (1,0) [0|0] "" Vector__XXX
 SG_ CC_a010_line3StuckClosed m10 : 54|1@1+ (1,0) [0|0] "" Vector__XXX
 SG_ CC_a036_line3StuckOpen m36 : 54|1@1+ (1,0) [0|0] "" Vector__XXX
 SG_ CC_a010_line2StuckClosed m10 : 53|1@1+ (1,0) [0|0] "" Vector__XXX
 SG_ CC_a036_line2StuckOpen m36 : 53|1@1+ (1,0) [0|0] "" Vector__XXX
 SG_ CC_a010_line1StuckClosed m10 : 52|1@1+ (1,0) [0|0] "" Vector__XXX
 SG_ CC_a036_line1StuckOpen m36 : 52|1@1+ (1,0) [0|0] "" Vector__XXX
 SG_ CC_a003_gfciFaultReason m3 : 50|4@1+ (1,0) [0|0] "" Vector__XXX
 SG_ CC_a004_gfciSelfTestCurrent m4 : 48|16@1- (0.0001,0) [0|0] "" Vector__XXX
 SG_ CC_a006_line3Current m6 : 48|16@1+ (0.01,0) [0|0] "" Vector__XXX
 SG_ CC_a007_inputNeutralVoltage m7 : 48|16@1+ (0.01,0) [0|0] "" Vector__XXX
 SG_ CC_a008_inputNeutralVoltage m8 : 48|16@1+ (0.01,0) [0|0] "" Vector__XXX
 SG_ CC_a035_gfciFactoryScaling m35 : 48|16@1+ (1,0) [0|0] "" Vector__XXX
 SG_ CC_a014_meterFaultData m14 : 41|16@1+ (1,0) [0|0] "" Vector__XXX
 SG_ CC_a003_dcGfciCurrent m3 : 40|10@1- (0.001,0) [0|0] "" Vector__XXX
 SG_ CC_a010_line3Voltage m10 : 40|12@1+ (0.1,0) [0|0] "" Vector__XXX
 SG_ CC_a036_line3Voltage m36 : 40|12@1+ (0.1,0) [0|0] "" Vector__XXX
 SG_ CC_a004_gfciSelfTestDuty m4 : 32|16@1- (0.0001,50) [0|0] "" Vector__XXX
 SG_ CC_a006_line2Current m6 : 32|16@1+ (0.01,0) [0|0] "" Vector__XXX
 SG_ CC_a007_inputLineVoltage m7 : 32|16@1+ (0.01,0) [0|0] "" Vector__XXX
 SG_ CC_a008_inputLineVoltage m8 : 32|16@1+ (0.01,0) [0|0] "" Vector__XXX
 SG_ CC_a015_smState m15 : 32|8@1+ (1,0) [0|0] "" Vector__XXX
 SG_ CC_a035_gfciFactoryOffset m35 : 32|16@1- (1,0) [0|0] "" Vector__XXX
 SG_ CC_a037_expiredWatchdogAppCRC m37 : 32|32@1+ (1,0) [0|0] "" Vector__XXX
 SG_ CC_a038_moduleMiaAppCRC m38 : 32|32@1+ (1,0) [0|0] "" Vector__XXX
 SG_ CC_a041_inputThermopileDvdt m41 : 32|16@1- (1e-06,0) [0|0] "" Vector__XXX
 SG_ CC_a047_motorFaultReason m47 : 30|2@1+ (1,0) [0|0] "" Vector__XXX
 SG_ CC_a003_gfciRmsCurrentAvg m3 : 28|12@1+ (0.001,0) [0|0] "" Vector__XXX
 SG_ CC_a010_line2Voltage m10 : 28|12@1+ (0.1,0) [0|0] "" Vector__XXX
 SG_ CC_a012_inputThermopileDvdt m12 : 28|12@1+ (1e-06,0) [0|0] "" Vector__XXX
 SG_ CC_a027_handleTempFaultReason m27 : 28|4@1+ (1,0) [0|0] "" Vector__XXX
 SG_ CC_a036_line2Voltage m36 : 28|12@1+ (0.1,0) [0|0] "" Vector__XXX
 SG_ CC_a047_actuatorTargetPos m47 : 28|2@1+ (1,0) [0|0] "" Vector__XXX
 SG_ CC_a014_meterFaultAddress m14 : 25|16@1+ (1,0) [0|0] "" Vector__XXX
 SG_ CC_a033_measuredVoltage m33 : 25|9@1+ (0.01,0) [0|0] "" Vector__XXX
 SG_ CC_a052_measuredVoltage m52 : 25|9@1+ (0.01,0) [0|0] "" Vector__XXX
 SG_ CC_a004_gfciAsicErrorBitfield m4 : 24|8@1+ (1,0) [0|0] "" Vector__XXX
 SG_ CC_a037_expiredWatchdogTaskId m37 : 24|8@1+ (1,0) [0|0] "" Vector__XXX
 SG_ CC_a038_moduleMiaTaskId m38 : 24|8@1+ (1,0) [0|0] "" Vector__XXX
 SG_ CC_a044_pcbaTemperature m44 : 24|9@1- (1,88) [0|0] "" Vector__XXX
 SG_ CC_a049_rs485DriverFault m49 : 24|32@1- (1,0) [0|0] "" Vector__XXX
 SG_ CC_a051_chcCriticalFaultUpdateAt m51 : 24|32@1+ (1,0) [0|0] "" Vector__XXX
 SG_ CC_a057_chcVitalsRequestExpected m57 : 24|32@1+ (1,0) [0|0] "" Vector__XXX
 SG_ CC_a032_meteringConfigMismatch m32 : 17|1@1+ (1,0) [0|0] "" Vector__XXX
 SG_ CC_a001_groundResistance m1 : 16|12@1+ (1000,0) [0|0] "" Vector__XXX
 SG_ CC_a003_gfciRmsCurrent m3 : 16|12@1+ (0.001,0) [0|0] "" Vector__XXX
 SG_ CC_a004_gfciErrorReason m4 : 16|8@1+ (1,0) [0|0] "" Vector__XXX
 SG_ CC_a006_line1Current m6 : 16|16@1+ (0.01,0) [0|0] "" Vector__XXX
 SG_ CC_a007_inputVoltage m7 : 16|16@1+ (0.01,0) [0|0] "" Vector__XXX
 SG_ CC_a008_inputVoltage m8 : 16|16@1+ (0.01,0) [0|0] "" Vector__XXX
 SG_ CC_a010_line1Voltage m10 : 16|12@1+ (0.1,0) [0|0] "" Vector__XXX
 SG_ CC_a011_pcbaTemp m11 : 16|9@1- (1,88) [0|0] "" Vector__XXX
 SG_ CC_a012_inputThermopile m12 : 16|12@1+ (1e-06,0) [0|0] "" Vector__XXX
 SG_ CC_a013_handleTemp m13 : 16|9@1- (1,88) [0|0] "" Vector__XXX
 SG_ CC_a014_failureCause m14 : 16|9@1+ (1,0) [0|0] "" Vector__XXX
 SG_ CC_a015_pilotHighVolage m15 : 16|16@1+ (0.001,0) [0|0] "" Vector__XXX
 SG_ CC_a027_handleTemperature m27 : 16|12@1- (0.1,0) [0|0] "" Vector__XXX
 SG_ CC_a032_meteringSpiCommsFailure m32 : 16|1@1+ (1,0) [0|0] "" Vector__XXX
 SG_ CC_a033_nominalVoltage m33 : 16|9@1+ (0.01,0) [0|0] "" Vector__XXX
 SG_ CC_a034_resetCause m34 : 16|4@1+ (1,0) [0|0] "" Vector__XXX
 SG_ CC_a035_gfciCalibrationOffset m35 : 16|16@1- (1,0) [0|0] "" Vector__XXX
 SG_ CC_a036_line1Voltage m36 : 16|12@1+ (0.1,0) [0|0] "" Vector__XXX
 SG_ CC_a037_expiredWatchdogModuleId m37 : 16|8@1+ (1,0) [0|0] "" Vector__XXX
 SG_ CC_a038_moduleMiaModuleId m38 : 16|8@1+ (1,0) [0|0] "" Vector__XXX
 SG_ CC_a039_intModuleTemperature m39 : 16|9@1- (1,88) [0|0] "" Vector__XXX
 SG_ CC_a040_handleTemperature m40 : 16|9@1- (1,88) [0|0] "" Vector__XXX
 SG_ CC_a041_inputThermopile m41 : 16|16@1- (1e-06,0) [0|0] "" Vector__XXX
 SG_ CC_a042_pcbaTemperature m42 : 16|9@1- (1,88) [0|0] "" Vector__XXX
 SG_ CC_a044_relayCoilVoltage m44 : 16|8@1+ (0.14,0) [0|0] "" Vector__XXX
 SG_ CC_a047_actuatorCurrPosDeg m47 : 16|12@1+ (0.1,0) [0|0] "" Vector__XXX
 SG_ CC_a048_adapterFaultReason m48 : 16|4@1+ (1,0) [0|0] "" Vector__XXX
 SG_ CC_a049_rs485FailReason m49 : 16|4@1+ (1,0) [0|0] "" Vector__XXX
 SG_ CC_a050_eFuseFaultReason m50 : 16|4@1+ (1,0) [0|0] "" Vector__XXX
 SG_ CC_a051_chcCriticalFaultReason m51 : 16|6@1+ (1,0) [0|0] "" Vector__XXX
 SG_ CC_a052_nominalVoltage m52 : 16|9@1+ (0.01,0) [0|0] "" Vector__XXX
 SG_ CC_a057_chcVitalsRequestFailureR m57 : 16|4@1+ (1,0) [0|0] "" Vector__XXX
 SG_ CC_a060_persistenceFaultReason m60 : 16|4@1+ (1,0) [0|0] "" Vector__XXX
 SG_ CC_alertType : 15|1@1+ (1,0) [0|0] "" Vector__XXX
 SG_ CC_alertID M : 0|15@1+ (1,0) [0|0] "" Vector__XXX

BO_ 1117 FC_evseBilling: 8 Vector__XXX
 SG_ FC_evseMeterVoltage m0 : 54|10@1+ (1,0) [0|0] "" Vector__XXX
 SG_ FC_evseMeterCurrent m0 : 44|10@1+ (1,0) [0|0] "" Vector__XXX
 SG_ FC_evseMeterPower m0 : 24|20@1+ (0.001,0) [0|0] "" Vector__XXX
 SG_ FC_evseBillingEnergy m0 : 4|20@1+ (0.001,0) [0|0] "" Vector__XXX
 SG_ FC_evseMeterFwGitHash m1 : 4|56@1+ (1,0) [0|0] "" Vector__XXX
 SG_ FC_evseBillingDataSelect M : 0|1@1+ (1,0) [0|0] "" Vector__XXX

BO_ 1118 VCFRONT1_LVSelfTests: 8 Vector__XXX
 SG_ VCFRONT1_uvProtectionState m0 : 36|4@1+ (1,0) [0|0] "" Vector__XXX
 SG_ VCFRONT1_pcsOvShutdownOkToContin m0 : 35|1@1+ (1,0) [0|0] "" Vector__XXX
 SG_ VCFRONT1_pcsOvShutdownSelfTestSt m0 : 32|3@1+ (1,0) [0|0] "" Vector__XXX
 SG_ VCFRONT1_pcsOvShutdownSelfTestRe m0 : 29|2@1+ (1,0) [0|0] "" Vector__XXX
 SG_ VCFRONT1_vcfrontBridgeEFuseASICS m0 : 26|3@1+ (1,0) [0|0] "" Vector__XXX
 SG_ VCFRONT1_vcfrontBridgeEFuse_0000 m0 : 24|2@1+ (1,0) [0|0] "" Vector__XXX
 SG_ VCFRONT1_pcsDomainUndervoltageSe m0 : 21|3@1+ (1,0) [0|0] "" Vector__XXX
 SG_ VCFRONT1_pcsDomainUndervolt_0000 m0 : 19|2@1+ (1,0) [0|0] "" Vector__XXX
 SG_ VCFRONT1_pcsDomainOvervoltageSel m0 : 16|3@1+ (1,0) [0|0] "" Vector__XXX
 SG_ VCFRONT1_pcsDomainOvervolta_0000 m0 : 13|2@1+ (1,0) [0|0] "" Vector__XXX
 SG_ VCFRONT1_LVSelfTestsIndex M : 12|1@1+ (1,0) [0|0] "" Vector__XXX
 SG_ VCFRONT1_LVSelfTestsCounter : 8|4@1+ (1,0) [0|0] "" Vector__XXX
 SG_ VCFRONT1_LVSelfTestsChecksum : 0|8@1+ (1,0) [0|0] "" Vector__XXX

BO_ 1119 VCBATT1_LVSelfTests: 8 Vector__XXX
 SG_ VCBATT1_uvProtectionState m1 : 51|4@1+ (1,0) [0|0] "" Vector__XXX
 SG_ VCBATT1_selfTestsExpectVnfFaults m0 : 49|1@1+ (1,0) [0|0] "" Vector__XXX
 SG_ VCBATT1_selfTestsKeepAwakeReques m0 : 48|1@1+ (1,0) [0|0] "" Vector__XXX
 SG_ VCBATT1_vcbattBridgeEFuseASICSel m1 : 48|3@1+ (1,0) [0|0] "" Vector__XXX
 SG_ VCBATT1_vcbattBridgeEFuseAS_0000 m1 : 45|2@1+ (1,0) [0|0] "" Vector__XXX
 SG_ VCBATT1_dualPowerLoadsSelfTestSt m1 : 42|3@1+ (1,0) [0|0] "" Vector__XXX
 SG_ VCBATT1_dualPowerLoadsSelfTestRe m1 : 40|2@1+ (1,0) [0|0] "" Vector__XXX
 SG_ VCBATT1_selfTestsHoursUntilExpir m0 : 40|8@1+ (1,0) [0|0] "" Vector__XXX
 SG_ VCBATT1_selfTestsBlockDriveOnWak m0 : 39|1@1+ (1,0) [0|0] "" Vector__XXX
 SG_ VCBATT1_selfTestsRequireHwProtAr m0 : 38|1@1+ (1,0) [0|0] "" Vector__XXX
 SG_ VCBATT1_battDomainUndervoltageSe m1 : 37|3@1+ (1,0) [0|0] "" Vector__XXX
 SG_ VCBATT1_selfTestsRunningOrRetryP m0 : 37|1@1+ (1,0) [0|0] "" Vector__XXX
 SG_ VCBATT1_selfTestsInProgress m0 : 36|1@1+ (1,0) [0|0] "" Vector__XXX
 SG_ VCBATT1_battDomainUndervolt_0000 m1 : 35|2@1+ (1,0) [0|0] "" Vector__XXX
 SG_ VCBATT1_battDomainOvervoltageSel m1 : 32|3@1+ (1,0) [0|0] "" Vector__XXX
 SG_ VCBATT1_selfTestRetriesRemaining m0 : 32|4@1+ (1,0) [0|0] "" Vector__XXX
 SG_ VCBATT1_battDomainOvervolta_0000 m1 : 30|2@1+ (1,0) [0|0] "" Vector__XXX
 SG_ VCBATT1_battDomainOvercurrentSel m1 : 27|3@1+ (1,0) [0|0] "" Vector__XXX
 SG_ VCBATT1_battDomainOvercurre_0000 m1 : 25|2@1+ (1,0) [0|0] "" Vector__XXX
 SG_ VCBATT1_selfTestRetriesUsed m0 : 25|4@1+ (1,0) [0|0] "" Vector__XXX
 SG_ VCBATT1_selfTestsTimedOut m0 : 24|1@1+ (1,0) [0|0] "" Vector__XXX
 SG_ VCBATT1_startVCFrontBridgeEFuseA m1 : 24|1@1+ (1,0) [0|0] "" Vector__XXX
 SG_ VCBATT1_startPCSDomainUndervolta m1 : 23|1@1+ (1,0) [0|0] "" Vector__XXX
 SG_ VCBATT1_startBattDomainUnde_0000 m1 : 22|1@1+ (1,0) [0|0] "" Vector__XXX
 SG_ VCBATT1_startPCSDomainOvervoltag m1 : 21|1@1+ (1,0) [0|0] "" Vector__XXX
 SG_ VCBATT1_selfTestsLastCompletedSt m0 : 20|4@1+ (1,0) [0|0] "" Vector__XXX
 SG_ VCBATT1_startPCSOVShutdownSelfTe m1 : 20|1@1+ (1,0) [0|0] "" Vector__XXX
 SG_ VCBATT1_startBattDomainOver_0000 m1 : 19|1@1+ (1,0) [0|0] "" Vector__XXX
 SG_ VCBATT1_startVCBattBridgeEFuseAS m1 : 18|1@1+ (1,0) [0|0] "" Vector__XXX
 SG_ VCBATT1_startDualPowerLoadsSelfT m1 : 17|1@1+ (1,0) [0|0] "" Vector__XXX
 SG_ VCBATT1_selfTestOrchestratorStat m0 : 16|4@1+ (1,0) [0|0] "" Vector__XXX
 SG_ VCBATT1_startBattDomainUndervolt m1 : 16|1@1+ (1,0) [0|0] "" Vector__XXX
 SG_ VCBATT1_startBattDomainOvervolta m1 : 15|1@1+ (1,0) [0|0] "" Vector__XXX
 SG_ VCBATT1_startBattDomainOvercurre m1 : 14|1@1+ (1,0) [0|0] "" Vector__XXX
 SG_ VCBATT1_lvProtectionSelfTestsEna m1 : 13|1@1+ (1,0) [0|0] "" Vector__XXX
 SG_ VCBATT1_LVSelfTestsIndex M : 12|1@1+ (1,0) [0|0] "" Vector__XXX
 SG_ VCBATT1_LVSelfTestsCounter : 8|4@1+ (1,0) [0|0] "" Vector__XXX
 SG_ VCBATT1_LVSelfTestsChecksum : 0|8@1+ (1,0) [0|0] "" Vector__XXX

BO_ 1121 VC_TLVBMS_debug: 8 Vector__XXX
 SG_ VC_TLVBMS_socByTopOfChargeEnable m0 : 63|1@1+ (1,0) [0|0] "" Vector__XXX
 SG_ VC_TLVBMS_hwOverCurrentSet m0 : 62|1@1+ (1,0) [0|0] "" Vector__XXX
 SG_ VC_TLVBMS_hwCellProtectionsTripp m0 : 61|1@1+ (1,0) [0|0] "" Vector__XXX
 SG_ VC_TLVBMS_socByDeltaVEnabled m0 : 60|1@1+ (1,0) [0|0] "" Vector__XXX
 SG_ VC_TLVBMS_brickImpedanceMaxId m5 : 59|5@1+ (1,1) [0|0] "" Vector__XXX
 SG_ VC_TLVBMS_brickImpedanceMaxId_sh m11 : 59|5@1+ (1,1) [0|0] "" Vector__XXX
 SG_ VC_TLVBMS_chargingIsActiveCoarse m0 : 59|1@1+ (1,0) [0|0] "" Vector__XXX
 SG_ VC_TLVBMS_chargingIsActiveFine m0 : 58|1@1+ (1,0) [0|0] "" Vector__XXX
 SG_ VC_TLVBMS_impTestRGrowthFiltMaxI m9 : 58|5@1+ (1,1) [0|0] "" Vector__XXX
 SG_ VC_TLVBMS_allBricksRestingForCac m0 : 57|1@1+ (1,0) [0|0] "" Vector__XXX
 SG_ VC_TLVBMS_allBricksRestingForSoc m0 : 56|1@1+ (1,0) [0|0] "" Vector__XXX
 SG_ VC_TLVBMS_capacityImbalanceSourc m8 : 56|3@1+ (1,0) [0|0] "" Vector__XXX
 SG_ VC_TLVBMS_sohTestLabel m7 : 56|4@1+ (1,0) [0|0] "" Vector__XXX
 SG_ VC_TLVBMS_heaterOn m0 : 55|1@1+ (1,0) [0|0] "" Vector__XXX
 SG_ VC_TLVBMS_brickImpedanceMinId m5 : 54|5@1+ (1,1) [0|0] "" Vector__XXX
 SG_ VC_TLVBMS_brickImpedanceMinId_sh m11 : 54|5@1+ (1,1) [0|0] "" Vector__XXX
 SG_ VC_TLVBMS_sohTestDuration m3 : 54|10@1+ (0.1,-0.1) [0|0] "" Vector__XXX
 SG_ VC_TLVBMS_impTestRGrowthMaxId m9 : 53|5@1+ (1,1) [0|0] "" Vector__XXX
 SG_ VC_TLVBMS_bmb6VSense m2 : 52|12@1+ (0.002,0) [0|0] "" Vector__XXX
 SG_ VC_TLVBMS_usableEnergyAvailable m6 : 52|12@1+ (1,0) [0|0] "" Vector__XXX
 SG_ VC_TLVBMS_brickImpedanceDeltaI m4 : 50|12@1- (0.25,0) [0|0] "" Vector__XXX
 SG_ VC_TLVBMS_brickImpedanceNor_0000 m7 : 48|5@1+ (1,1) [0|0] "" Vector__XXX
 SG_ VC_TLVBMS_efuseFeedbackVSense m1 : 48|12@1+ (0.02,0) [0|0] "" Vector__XXX
 SG_ VC_TLVBMS_heaterCurrent m0 : 48|7@1+ (0.04,0) [0|0] "" Vector__XXX
 SG_ VC_TLVBMS_impTestRGrowthMinId m9 : 48|5@1+ (1,1) [0|0] "" Vector__XXX
 SG_ VC_TLVBMS_capacityImbalancePct m8 : 46|10@1+ (0.1,0) [0|0] "" Vector__XXX
 SG_ VC_TLVBMS_sohTestUsableEnergy m3 : 44|10@1+ (0.2,-0.2) [0|0] "" Vector__XXX
 SG_ VC_TLVBMS_minDischargeLoadedBric m6 : 42|10@1+ (0.005,0) [0|0] "" Vector__XXX
 SG_ VC_TLVBMS_tempSenseBusbar m2 : 41|11@1+ (0.1,-50) [0|0] "" Vector__XXX
 SG_ VC_TLVBMS_boundedNegativeSocErro m4 : 40|10@1+ (0.1,0) [0|0] "" Vector__XXX
 SG_ VC_TLVBMS_brickImpedanceDeltaI_s m10 : 40|12@1- (0.25,0) [0|0] "" Vector__XXX
 SG_ VC_TLVBMS_brickImpedanceMax m5 : 40|14@1+ (2.5e-05,0) [0|0] "" Vector__XXX
 SG_ VC_TLVBMS_brickImpedanceMax_shad m11 : 40|14@1+ (2.5e-05,0) [0|0] "" Vector__XXX
 SG_ VC_TLVBMS_brickImpedanceNormFilt m7 : 40|8@1+ (0.01,0.5) [0|0] "" Vector__XXX
 SG_ VC_TLVBMS_cacMaxBrickId m1 : 40|5@1+ (1,1) [0|0] "" Vector__XXX
 SG_ VC_TLVBMS_socRestingCurrentThres m0 : 38|10@1+ (0.002,0) [0|0] "" Vector__XXX
 SG_ VC_TLVBMS_sohTestUsableCapacity m3 : 37|7@1+ (0.2,-0.2) [0|0] "" Vector__XXX
 SG_ VC_TLVBMS_brickImpedanceNor_0002 m10 : 32|5@1+ (1,1) [0|0] "" Vector__XXX
 SG_ VC_TLVBMS_cacMinBrickId m1 : 32|5@1+ (1,1) [0|0] "" Vector__XXX
 SG_ VC_TLVBMS_calendarAgingDcrGrowth m8 : 32|14@1- (0.1,200) [0|0] "" Vector__XXX
 SG_ VC_TLVBMS_impTestDeltaI m9 : 32|12@1- (0.25,0) [0|0] "" Vector__XXX
 SG_ VC_TLVBMS_maxDischargeLoadedBric m6 : 32|10@1+ (0.005,0) [0|0] "" Vector__XXX
 SG_ VC_TLVBMS_socByOcvEstMin m4 : 30|10@1+ (0.1,0) [0|0] "" Vector__XXX
 SG_ VC_TLVBMS_tempSenseEfuse m2 : 30|11@1+ (0.1,-50) [0|0] "" Vector__XXX
 SG_ VC_TLVBMS_socByOcvMaxError m0 : 28|10@1+ (0.1,0) [0|0] "" Vector__XXX
 SG_ VC_TLVBMS_sohTestEndingSoc m3 : 27|10@1+ (0.1,0) [0|0] "" Vector__XXX
 SG_ VC_TLVBMS_brickImpedanceMin m5 : 24|14@1+ (2.5e-05,0) [0|0] "" Vector__XXX
 SG_ VC_TLVBMS_brickImpedanceMin_shad m11 : 24|14@1+ (2.5e-05,0) [0|0] "" Vector__XXX
 SG_ VC_TLVBMS_brickImpedanceNor_0001 m10 : 24|8@1+ (0.01,0.5) [0|0] "" Vector__XXX
 SG_ VC_TLVBMS_impTestRGrowthFiltMax m9 : 24|8@1+ (0.01,0.5) [0|0] "" Vector__XXX
 SG_ VC_TLVBMS_bleedFetTestAllowed m10 : 23|1@1+ (1,0) [0|0] "" Vector__XXX
 SG_ VC_TLVBMS_bleedFetTestNeeded m10 : 22|1@1+ (1,0) [0|0] "" Vector__XXX
 SG_ VC_TLVBMS_calendarAgingCapacityL m8 : 21|9@1+ (0.1,0) [0|0] "" Vector__XXX
 SG_ VC_TLVBMS_cacMax m1 : 20|12@1+ (0.005,0) [0|0] "" Vector__XXX
 SG_ VC_TLVBMS_lowCurrentInterruption m10 : 20|2@1+ (1,0) [0|0] "" Vector__XXX
 SG_ VC_TLVBMS_maxRegenPower m6 : 20|12@1+ (2,0) [0|0] "" Vector__XXX
 SG_ VC_TLVBMS_socByOcvEstMax m4 : 20|10@1+ (0.1,0) [0|0] "" Vector__XXX
 SG_ VC_TLVBMS_sohTestInitialSoc m3 : 20|7@1+ (0.1,90) [0|0] "" Vector__XXX
 SG_ VC_TLVBMS_tempSense2 m2 : 19|11@1+ (0.1,-50) [0|0] "" Vector__XXX
 SG_ VC_TLVBMS_socByOcvMaxBrick1 m0 : 18|10@1+ (0.1,0) [0|0] "" Vector__XXX
 SG_ VC_TLVBMS_impTestRGrowthMax m9 : 16|8@1+ (0.01,0.5) [0|0] "" Vector__XXX
 SG_ VC_TLVBMS_sohTestEndMode m3 : 16|4@1+ (1,0) [0|0] "" Vector__XXX
 SG_ VC_TLVBMS_brickImpedanceAvg m5 : 8|14@1+ (2.5e-05,0) [0|0] "" Vector__XXX
 SG_ VC_TLVBMS_brickImpedanceAvg_shad m11 : 8|14@1+ (2.5e-05,0) [0|0] "" Vector__XXX
 SG_ VC_TLVBMS_cacMin m1 : 8|12@1+ (0.005,0) [0|0] "" Vector__XXX
 SG_ VC_TLVBMS_dischargeVoltageLimit m4 : 8|12@1+ (0.015,0) [0|0] "" Vector__XXX
 SG_ VC_TLVBMS_impTestRGrowthMin m9 : 8|8@1+ (0.01,0.5) [0|0] "" Vector__XXX
 SG_ VC_TLVBMS_lowCurrentInterru_0000 m10 : 8|12@1- (0.001,0) [0|0] "" Vector__XXX
 SG_ VC_TLVBMS_maxDischargePower m6 : 8|12@1+ (2,-8000) [0|0] "" Vector__XXX
 SG_ VC_TLVBMS_packBirthEpochBinned m8 : 8|13@1+ (864000,0) [0|0] "" Vector__XXX
 SG_ VC_TLVBMS_socByOcvMinBrick1 m0 : 8|10@1+ (0.1,0) [0|0] "" Vector__XXX
 SG_ VC_TLVBMS_sohTestCompletionEpoch m7 : 8|32@1+ (1,0) [0|0] "" Vector__XXX
 SG_ VC_TLVBMS_sohTestStateInternal m3 : 8|5@1+ (1,0) [0|0] "" Vector__XXX
 SG_ VC_TLVBMS_tempSense1 m2 : 8|11@1+ (0.1,-50) [0|0] "" Vector__XXX
 SG_ VC_TLVBMS_debugMultiplexer M : 0|8@1+ (1,0) [0|0] "" Vector__XXX

BO_ 1122 VCBATT1_TLVBMS_debug: 8 Vector__XXX
 SG_ VCBATT1_TLVBMS_socByTopOfChargeE m0 : 63|1@1+ (1,0) [0|0] "" Vector__XXX
 SG_ VCBATT1_TLVBMS_hwOverCurrentSet m0 : 62|1@1+ (1,0) [0|0] "" Vector__XXX
 SG_ VCBATT1_TLVBMS_hwCellProtections m0 : 61|1@1+ (1,0) [0|0] "" Vector__XXX
 SG_ VCBATT1_TLVBMS_socByDeltaVEnable m0 : 60|1@1+ (1,0) [0|0] "" Vector__XXX
 SG_ VCBATT1_TLVBMS_brickImpedan_0000 m5 : 59|5@1+ (1,1) [0|0] "" Vector__XXX
 SG_ VCBATT1_TLVBMS_brickImpedan_0005 m11 : 59|5@1+ (1,1) [0|0] "" Vector__XXX
 SG_ VCBATT1_TLVBMS_chargingIsActiveC m0 : 59|1@1+ (1,0) [0|0] "" Vector__XXX
 SG_ VCBATT1_TLVBMS_chargingIsActiveF m0 : 58|1@1+ (1,0) [0|0] "" Vector__XXX
 SG_ VCBATT1_TLVBMS_impTestRGrow_0002 m9 : 58|5@1+ (1,1) [0|0] "" Vector__XXX
 SG_ VCBATT1_TLVBMS_allBricksRestingF m0 : 57|1@1+ (1,0) [0|0] "" Vector__XXX
 SG_ VCBATT1_TLVBMS_allBricksRes_0000 m0 : 56|1@1+ (1,0) [0|0] "" Vector__XXX
 SG_ VCBATT1_TLVBMS_capacityImba_0000 m8 : 56|3@1+ (1,0) [0|0] "" Vector__XXX
 SG_ VCBATT1_TLVBMS_sohTestLabel m7 : 56|4@1+ (1,0) [0|0] "" Vector__XXX
 SG_ VCBATT1_TLVBMS_heaterOn m0 : 55|1@1+ (1,0) [0|0] "" Vector__XXX
 SG_ VCBATT1_TLVBMS_brickImpedan_0001 m5 : 54|5@1+ (1,1) [0|0] "" Vector__XXX
 SG_ VCBATT1_TLVBMS_brickImpedan_0006 m11 : 54|5@1+ (1,1) [0|0] "" Vector__XXX
 SG_ VCBATT1_TLVBMS_sohTestDuration m3 : 54|10@1+ (0.1,-0.1) [0|0] "" Vector__XXX
 SG_ VCBATT1_TLVBMS_impTestRGrow_0000 m9 : 53|5@1+ (1,1) [0|0] "" Vector__XXX
 SG_ VCBATT1_TLVBMS_bmb6VSense m2 : 52|12@1+ (0.002,0) [0|0] "" Vector__XXX
 SG_ VCBATT1_TLVBMS_usableEnergyAvail m6 : 52|12@1+ (1,0) [0|0] "" Vector__XXX
 SG_ VCBATT1_TLVBMS_brickImpedanceDel m4 : 50|12@1- (0.25,0) [0|0] "" Vector__XXX
 SG_ VCBATT1_TLVBMS_brickImpedan_0008 m7 : 48|5@1+ (1,1) [0|0] "" Vector__XXX
 SG_ VCBATT1_TLVBMS_efuseFeedbackVSen m1 : 48|12@1+ (0.02,0) [0|0] "" Vector__XXX
 SG_ VCBATT1_TLVBMS_heaterCurrent m0 : 48|7@1+ (0.04,0) [0|0] "" Vector__XXX
 SG_ VCBATT1_TLVBMS_impTestRGrow_0001 m9 : 48|5@1+ (1,1) [0|0] "" Vector__XXX
 SG_ VCBATT1_TLVBMS_capacityImbalance m8 : 46|10@1+ (0.1,0) [0|0] "" Vector__XXX
 SG_ VCBATT1_TLVBMS_sohTestUsableEner m3 : 44|10@1+ (0.2,-0.2) [0|0] "" Vector__XXX
 SG_ VCBATT1_TLVBMS_minDischargeLoade m6 : 42|10@1+ (0.005,0) [0|0] "" Vector__XXX
 SG_ VCBATT1_TLVBMS_tempSenseBusbar m2 : 41|11@1+ (0.1,-50) [0|0] "" Vector__XXX
 SG_ VCBATT1_TLVBMS_boundedNegativeSo m4 : 40|10@1+ (0.1,0) [0|0] "" Vector__XXX
 SG_ VCBATT1_TLVBMS_brickImpedan_0007 m10 : 40|12@1- (0.25,0) [0|0] "" Vector__XXX
 SG_ VCBATT1_TLVBMS_brickImpedanceMax m5 : 40|14@1+ (2.5e-05,0) [0|0] "" Vector__XXX
 SG_ VCBATT1_TLVBMS_brickImpedan_0003 m11 : 40|14@1+ (2.5e-05,0) [0|0] "" Vector__XXX
 SG_ VCBATT1_TLVBMS_brickImpedanceNor m7 : 40|8@1+ (0.01,0.5) [0|0] "" Vector__XXX
 SG_ VCBATT1_TLVBMS_cacMaxBrickId m1 : 40|5@1+ (1,1) [0|0] "" Vector__XXX
 SG_ VCBATT1_TLVBMS_socRestingCurrent m0 : 38|10@1+ (0.002,0) [0|0] "" Vector__XXX
 SG_ VCBATT1_TLVBMS_sohTestUsableCapa m3 : 37|7@1+ (0.2,-0.2) [0|0] "" Vector__XXX
 SG_ VCBATT1_TLVBMS_brickImpedan_0010 m10 : 32|5@1+ (1,1) [0|0] "" Vector__XXX
 SG_ VCBATT1_TLVBMS_cacMinBrickId m1 : 32|5@1+ (1,1) [0|0] "" Vector__XXX
 SG_ VCBATT1_TLVBMS_calendarAgingDcrG m8 : 32|14@1- (0.1,200) [0|0] "" Vector__XXX
 SG_ VCBATT1_TLVBMS_impTestDeltaI m9 : 32|12@1- (0.25,0) [0|0] "" Vector__XXX
 SG_ VCBATT1_TLVBMS_maxDischargeLoade m6 : 32|10@1+ (0.005,0) [0|0] "" Vector__XXX
 SG_ VCBATT1_TLVBMS_socByOcvEstMin m4 : 30|10@1+ (0.1,0) [0|0] "" Vector__XXX
 SG_ VCBATT1_TLVBMS_tempSenseEfuse m2 : 30|11@1+ (0.1,-50) [0|0] "" Vector__XXX
 SG_ VCBATT1_TLVBMS_socByOcvMaxError m0 : 28|10@1+ (0.1,0) [0|0] "" Vector__XXX
 SG_ VCBATT1_TLVBMS_sohTestEndingSoc m3 : 27|10@1+ (0.1,0) [0|0] "" Vector__XXX
 SG_ VCBATT1_TLVBMS_brickImpedanceMin m5 : 24|14@1+ (2.5e-05,0) [0|0] "" Vector__XXX
 SG_ VCBATT1_TLVBMS_brickImpedan_0004 m11 : 24|14@1+ (2.5e-05,0) [0|0] "" Vector__XXX
 SG_ VCBATT1_TLVBMS_brickImpedan_0009 m10 : 24|8@1+ (0.01,0.5) [0|0] "" Vector__XXX
 SG_ VCBATT1_TLVBMS_impTestRGrowthFil m9 : 24|8@1+ (0.01,0.5) [0|0] "" Vector__XXX
 SG_ VCBATT1_TLVBMS_bleedFetTestAllow m10 : 23|1@1+ (1,0) [0|0] "" Vector__XXX
 SG_ VCBATT1_TLVBMS_bleedFetTestNeede m10 : 22|1@1+ (1,0) [0|0] "" Vector__XXX
 SG_ VCBATT1_TLVBMS_calendarAgingCapa m8 : 21|9@1+ (0.1,0) [0|0] "" Vector__XXX
 SG_ VCBATT1_TLVBMS_cacMax m1 : 20|12@1+ (0.005,0) [0|0] "" Vector__XXX
 SG_ VCBATT1_TLVBMS_lowCurrentInterru m10 : 20|2@1+ (1,0) [0|0] "" Vector__XXX
 SG_ VCBATT1_TLVBMS_maxRegenPower m6 : 20|12@1+ (2,0) [0|0] "" Vector__XXX
 SG_ VCBATT1_TLVBMS_socByOcvEstMax m4 : 20|10@1+ (0.1,0) [0|0] "" Vector__XXX
 SG_ VCBATT1_TLVBMS_sohTestInitialSoc m3 : 20|7@1+ (0.1,90) [0|0] "" Vector__XXX
 SG_ VCBATT1_TLVBMS_tempSense2 m2 : 19|11@1+ (0.1,-50) [0|0] "" Vector__XXX
 SG_ VCBATT1_TLVBMS_socByOcvMaxBrick1 m0 : 18|10@1+ (0.1,0) [0|0] "" Vector__XXX
 SG_ VCBATT1_TLVBMS_impTestRGrowthMax m9 : 16|8@1+ (0.01,0.5) [0|0] "" Vector__XXX
 SG_ VCBATT1_TLVBMS_sohTestEndMode m3 : 16|4@1+ (1,0) [0|0] "" Vector__XXX
 SG_ VCBATT1_TLVBMS_brickImpedanceAvg m5 : 8|14@1+ (2.5e-05,0) [0|0] "" Vector__XXX
 SG_ VCBATT1_TLVBMS_brickImpedan_0002 m11 : 8|14@1+ (2.5e-05,0) [0|0] "" Vector__XXX
 SG_ VCBATT1_TLVBMS_cacMin m1 : 8|12@1+ (0.005,0) [0|0] "" Vector__XXX
 SG_ VCBATT1_TLVBMS_dischargeVoltageL m4 : 8|12@1+ (0.015,0) [0|0] "" Vector__XXX
 SG_ VCBATT1_TLVBMS_impTestRGrowthMin m9 : 8|8@1+ (0.01,0.5) [0|0] "" Vector__XXX
 SG_ VCBATT1_TLVBMS_lowCurrentIn_0000 m10 : 8|12@1- (0.001,0) [0|0] "" Vector__XXX
 SG_ VCBATT1_TLVBMS_maxDischargePower m6 : 8|12@1+ (2,-8000) [0|0] "" Vector__XXX
 SG_ VCBATT1_TLVBMS_packBirthEpochBin m8 : 8|13@1+ (864000,0) [0|0] "" Vector__XXX
 SG_ VCBATT1_TLVBMS_socByOcvMinBrick1 m0 : 8|10@1+ (0.1,0) [0|0] "" Vector__XXX
 SG_ VCBATT1_TLVBMS_sohTestCompletion m7 : 8|32@1+ (1,0) [0|0] "" Vector__XXX
 SG_ VCBATT1_TLVBMS_sohTestStateInter m3 : 8|5@1+ (1,0) [0|0] "" Vector__XXX
 SG_ VCBATT1_TLVBMS_tempSense1 m2 : 8|11@1+ (0.1,-50) [0|0] "" Vector__XXX
 SG_ VCBATT1_TLVBMS_debugMultiplexer M : 0|8@1+ (1,0) [0|0] "" Vector__XXX

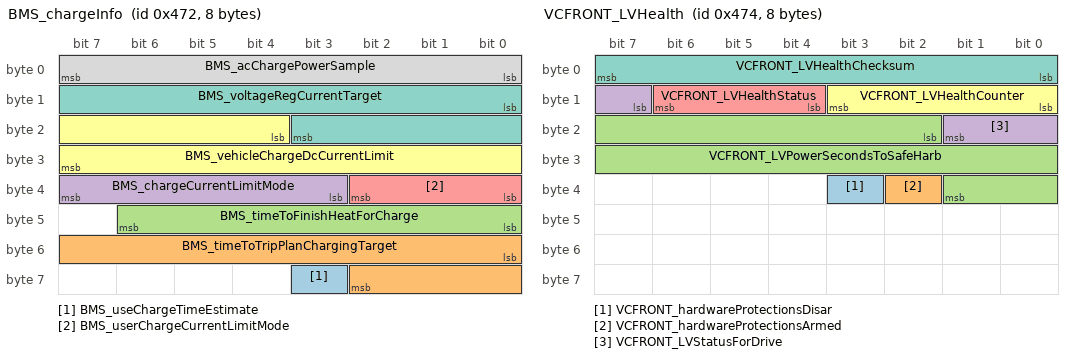
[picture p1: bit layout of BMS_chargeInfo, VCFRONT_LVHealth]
BO_ 1138 BMS_chargeInfo: 8 Vector__XXX
 SG_ BMS_useChargeTimeEstimate : 59|1@1+ (1,0) [0|0] "" Vector__XXX
 SG_ BMS_timeToTripPlanChargingTarget : 48|11@1+ (1,0) [0|0] "" Vector__XXX
 SG_ BMS_timeToFinishHeatForCharge : 40|7@1+ (5,0) [0|0] "" Vector__XXX
 SG_ BMS_chargeCurrentLimitMode : 35|5@1+ (1,0) [0|0] "" Vector__XXX
 SG_ BMS_userChargeCurrentLimitMode : 32|3@1+ (1,0) [0|0] "" Vector__XXX
 SG_ BMS_vehicleChargeDcCurrentLimit : 20|12@1+ (0.5,0) [0|0] "" Vector__XXX
 SG_ BMS_voltageRegCurrentTarget : 8|12@1+ (0.5,0) [0|0] "" Vector__XXX
 SG_ BMS_acChargePowerSample : 0|8@1+ (0.1,0) [0|0] "" Vector__XXX

BO_ 1140 VCFRONT_LVHealth: 8 Vector__XXX
 SG_ VCFRONT_hardwareProtectionsDisar : 35|1@1+ (1,0) [0|0] "" Vector__XXX
 SG_ VCFRONT_hardwareProtectionsArmed : 34|1@1+ (1,0) [0|0] "" Vector__XXX
 SG_ VCFRONT_LVPowerSecondsToSafeHarb : 18|16@1+ (1,0) [0|0] "" Vector__XXX
 SG_ VCFRONT_LVStatusForDrive : 15|3@1+ (1,0) [0|0] "" Vector__XXX
 SG_ VCFRONT_LVHealthStatus : 12|3@1+ (1,0) [0|0] "" Vector__XXX
 SG_ VCFRONT_LVHealthCounter : 8|4@1+ (1,0) [0|0] "" Vector__XXX
 SG_ VCFRONT_LVHealthChecksum : 0|8@1+ (1,0) [0|0] "" Vector__XXX

BO_ 1145 GTW_bootp: 8 Vector__XXX
 SG_ GTW_bootpByte : 0|8@1+ (1,0) [0|0] "" Vector__XXX

BO_ 1149 APP_warningMatrix6: 8 Vector__XXX
 SG_ APP_w448_leftRepeaterImagerConfigMismatch : 63|1@1+ (1,0) [0|0] "" Vector__XXX
 SG_ APP_w447_rightPillarImagerConfigMismatch : 62|1@1+ (1,0) [0|0] "" Vector__XXX
 SG_ APP_w446_leftPillarImagerConfigMismatch : 61|1@1+ (1,0) [0|0] "" Vector__XXX
 SG_ APP_w445_fisheyeImagerConfigMismatch : 60|1@1+ (1,0) [0|0] "" Vector__XXX
 SG_ APP_w444_narrowImagerConfigMismatch : 59|1@1+ (1,0) [0|0] "" Vector__XXX
 SG_ APP_w443_mainImagerConfigMismatch : 58|1@1+ (1,0) [0|0] "" Vector__XXX
 SG_ APP_w442_autonomyCancelMethod : 57|1@1+ (1,0) [0|0] "" Vector__XXX
 SG_ APP_w441_cabinCamLEDRailOff : 56|1@1+ (1,0) [0|0] "" Vector__XXX
 SG_ APP_w440_lensHoodOcclusion : 55|1@1+ (1,0) [0|0] "" Vector__XXX
 SG_ APP_w439_ethernetCommFailure : 54|1@1+ (1,0) [0|0] "" Vector__XXX
 SG_ APP_w438_rcuMia : 53|1@1+ (1,0) [0|0] "" Vector__XXX
 SG_ APP_w437_missingCloudEepromData : 52|1@1+ (1,0) [0|0] "" Vector__XXX
 SG_ APP_w436_camCsiError : 51|1@1+ (1,0) [0|0] "" Vector__XXX
 SG_ APP_w435_repeaterAeroRibInfoMismatched : 50|1@1+ (1,0) [0|0] "" Vector__XXX
 SG_ APP_w434_rightRepeaterDowngradeDetected : 49|1@1+ (1,0) [0|0] "" Vector__XXX
 SG_ APP_w433_leftRepeaterDowngradeDetected : 48|1@1+ (1,0) [0|0] "" Vector__XXX
 SG_ APP_w432_frontVisibilityDegraded_HIGH : 47|1@1+ (1,0) [0|0] "" Vector__XXX
 SG_ APP_w431_frontVisibilityDegraded_MEDIUM : 46|1@1+ (1,0) [0|0] "" Vector__XXX
 SG_ APP_w430_frontVisibilityDegraded_LOW : 45|1@1+ (1,0) [0|0] "" Vector__XXX
 SG_ APP_w429_cameraVisPopUpFascia : 44|1@1+ (1,0) [0|0] "" Vector__XXX
 SG_ APP_w428_cameraVisPopUpBackup : 43|1@1+ (1,0) [0|0] "" Vector__XXX
 SG_ APP_w427_cameraVisPopUpRRepeater : 42|1@1+ (1,0) [0|0] "" Vector__XXX
 SG_ APP_w426_cameraVisPopUpLRepeater : 41|1@1+ (1,0) [0|0] "" Vector__XXX
 SG_ APP_w425_cameraVisPopUpRPillar : 40|1@1+ (1,0) [0|0] "" Vector__XXX
 SG_ APP_w424_cameraVisPopUpLPillar : 39|1@1+ (1,0) [0|0] "" Vector__XXX
 SG_ APP_w423_cameraVisPopUpForward : 38|1@1+ (1,0) [0|0] "" Vector__XXX
 SG_ APP_w422_autonomyDegradedUser : 37|1@1+ (1,0) [0|0] "" Vector__XXX
 SG_ APP_w421_autonomyUnavailableUser : 36|1@1+ (1,0) [0|0] "" Vector__XXX
 SG_ APP_w420_autonomyDegradedApSystem : 35|1@1+ (1,0) [0|0] "" Vector__XXX
 SG_ APP_w419_autonomyUnavailableApSystem : 34|1@1+ (1,0) [0|0] "" Vector__XXX
 SG_ APP_w418_autonomyDegradedVisibility : 33|1@1+ (1,0) [0|0] "" Vector__XXX
 SG_ APP_w417_autonomyUnavailableVisibility : 32|1@1+ (1,0) [0|0] "" Vector__XXX
 SG_ APP_w416_autonomyDegradedSystem : 31|1@1+ (1,0) [0|0] "" Vector__XXX
 SG_ APP_w415_autonomyUnavailableSystem : 30|1@1+ (1,0) [0|0] "" Vector__XXX
 SG_ APP_w413_autonomyDegraded5 : 28|1@1+ (1,0) [0|0] "" Vector__XXX
 SG_ APP_w412_abortBackupCamOccluded : 27|1@1+ (1,0) [0|0] "" Vector__XXX
 SG_ APP_w411_backupCameraOccluded : 26|1@1+ (1,0) [0|0] "" Vector__XXX
 SG_ APP_w410_autonomyDegraded4 : 25|1@1+ (1,0) [0|0] "" Vector__XXX
 SG_ APP_w409_autonomyDegraded3 : 24|1@1+ (1,0) [0|0] "" Vector__XXX
 SG_ APP_w408_autonomyDegraded2 : 23|1@1+ (1,0) [0|0] "" Vector__XXX
 SG_ APP_w407_autonomyDegraded1 : 22|1@1+ (1,0) [0|0] "" Vector__XXX
 SG_ APP_w406_gnssHWHealthDegraded : 21|1@1+ (1,0) [0|0] "" Vector__XXX
 SG_ APP_w405_apsMia : 20|1@1+ (1,0) [0|0] "" Vector__XXX
 SG_ APP_w404_epbrMiaVehBus : 19|1@1+ (1,0) [0|0] "" Vector__XXX
 SG_ APP_w403_notifyCameraSelfCleanAction : 18|1@1+ (1,0) [0|0] "" Vector__XXX
 SG_ APP_w402_rightPillarCameraHeaterFaulted : 17|1@1+ (1,0) [0|0] "" Vector__XXX
 SG_ APP_w401_leftPillarCameraHeaterFaulted : 16|1@1+ (1,0) [0|0] "" Vector__XXX
 SG_ APP_w400_selfieCameraFanFault : 15|1@1+ (1,0) [0|0] "" Vector__XXX
 SG_ APP_w399_brakeboosterMia : 14|1@1+ (1,0) [0|0] "" Vector__XXX
 SG_ APP_w398_imuOutputUnhealthy : 13|1@1+ (1,0) [0|0] "" Vector__XXX
 SG_ APP_w397_apFeatDisabledPermanent : 12|1@1+ (1,0) [0|0] "" Vector__XXX
 SG_ APP_w396_severeResidueDetected : 11|1@1+ (1,0) [0|0] "" Vector__XXX
 SG_ APP_w395_cabinCameraLEDFaultSvc : 10|1@1+ (1,0) [0|0] "" Vector__XXX
 SG_ APP_w394_apImuGrossErrors : 9|1@1+ (1,0) [0|0] "" Vector__XXX
 SG_ APP_w393_attnMntrUnavailable : 8|1@1+ (1,0) [0|0] "" Vector__XXX
 SG_ APP_w392_fsdSuspended : 7|1@1+ (1,0) [0|0] "" Vector__XXX
 SG_ APP_w391_cabinCameraBlockedonAP : 6|1@1+ (1,0) [0|0] "" Vector__XXX
 SG_ APP_w390_cabinCamVisDegraded : 5|1@1+ (1,0) [0|0] "" Vector__XXX
 SG_ APP_w389_camFovResidueDetected : 4|1@1+ (1,0) [0|0] "" Vector__XXX
 SG_ APP_w388_windshieldCameraHeaterFaulted : 3|1@1+ (1,0) [0|0] "" Vector__XXX
 SG_ APP_w387_radarBlockageDetected : 2|1@1+ (1,0) [0|0] "" Vector__XXX
 SG_ APP_w386_radarOnlyBrakingEvent : 1|1@1+ (1,0) [0|0] "" Vector__XXX
 SG_ APP_w385_posEngineUnhealthy : 0|1@1+ (1,0) [0|0] "" Vector__XXX

BO_ 1151 APP_warningMatrix5: 8 Vector__XXX
 SG_ APP_w384_posEngineInitInMotion : 63|1@1+ (1,0) [0|0] "" Vector__XXX
 SG_ APP_w383_manyApRebootsWhileInP : 62|1@1+ (1,0) [0|0] "" Vector__XXX
 SG_ APP_w382_ubloxImuTimestampIssue : 61|1@1+ (1,0) [0|0] "" Vector__XXX
 SG_ APP_w381_apImuTimestampIssue : 60|1@1+ (1,0) [0|0] "" Vector__XXX
 SG_ APP_w380_gnssPpsTimestampIssue : 59|1@1+ (1,0) [0|0] "" Vector__XXX
 SG_ APP_w379_positioningEngineMia : 58|1@1+ (1,0) [0|0] "" Vector__XXX
 SG_ APP_w378_ubloxImuMia : 57|1@1+ (1,0) [0|0] "" Vector__XXX
 SG_ APP_w377_apImuMia : 56|1@1+ (1,0) [0|0] "" Vector__XXX
 SG_ APP_w376_wheeltickCountMia : 55|1@1+ (1,0) [0|0] "" Vector__XXX
 SG_ APP_w375_gnssPpsMia : 54|1@1+ (1,0) [0|0] "" Vector__XXX
 SG_ APP_w374_gnssDataMia : 53|1@1+ (1,0) [0|0] "" Vector__XXX
 SG_ APP_w373_gnssUartError : 52|1@1+ (1,0) [0|0] "" Vector__XXX
 SG_ APP_w372_cabinCameraBlocked : 51|1@1+ (1,0) [0|0] "" Vector__XXX
 SG_ APP_w371_networkLoadingIssue : 50|1@1+ (1,0) [0|0] "" Vector__XXX
 SG_ APP_w370_accApUnavUserSettings : 49|1@1+ (1,0) [0|0] "" Vector__XXX
 SG_ APP_w369_cruiseWithSingleClick : 48|1@1+ (1,0) [0|0] "" Vector__XXX
 SG_ APP_w361_cabinCameraLEDFault : 40|1@1+ (1,0) [0|0] "" Vector__XXX
 SG_ APP_w360_apImuNoiseDetected : 39|1@1+ (1,0) [0|0] "" Vector__XXX
 SG_ APP_w359_aebDegraded : 38|1@1+ (1,0) [0|0] "" Vector__XXX
 SG_ APP_w358_isaSystemFault : 37|1@1+ (1,0) [0|0] "" Vector__XXX
 SG_ APP_w357_ddawSystemFault : 36|1@1+ (1,0) [0|0] "" Vector__XXX
 SG_ APP_w356_driverOverriding : 35|1@1+ (1,0) [0|0] "" Vector__XXX
 SG_ APP_w355_camQuadPowerFault : 34|1@1+ (1,0) [0|0] "" Vector__XXX
 SG_ APP_w354_tradfcMia : 33|1@1+ (1,0) [0|0] "" Vector__XXX
 SG_ APP_w353_csiDevice2Down : 32|1@1+ (1,0) [0|0] "" Vector__XXX
 SG_ APP_w352_csiDevice1Down : 31|1@1+ (1,0) [0|0] "" Vector__XXX
 SG_ APP_w351_csiDevice0Down : 30|1@1+ (1,0) [0|0] "" Vector__XXX
 SG_ APP_w350_tradfcSensorMisaligned : 29|1@1+ (1,0) [0|0] "" Vector__XXX
 SG_ APP_w349_cameraPersistentlyFaulted : 28|1@1+ (1,0) [0|0] "" Vector__XXX
 SG_ APP_w348_cameraSwUpdateRequired : 27|1@1+ (1,0) [0|0] "" Vector__XXX
 SG_ APP_w347_vcbattMiaVehBus : 26|1@1+ (1,0) [0|0] "" Vector__XXX
 SG_ APP_w346_gpsSwEvent : 25|1@1+ (1,0) [0|0] "" Vector__XXX
 SG_ APP_w345_tradfcPerfDegraded : 24|1@1+ (1,0) [0|0] "" Vector__XXX
 SG_ APP_w344_tradfcDspAlgoTimeout : 23|1@1+ (1,0) [0|0] "" Vector__XXX
 SG_ APP_w343_tradfcDspSwError : 22|1@1+ (1,0) [0|0] "" Vector__XXX
 SG_ APP_w342_tradfcDspHwError : 21|1@1+ (1,0) [0|0] "" Vector__XXX
 SG_ APP_w341_tradfcCalibError : 20|1@1+ (1,0) [0|0] "" Vector__XXX
 SG_ APP_w340_tradfcCsiError : 19|1@1+ (1,0) [0|0] "" Vector__XXX
 SG_ APP_w339_tradfcRfTempError : 18|1@1+ (1,0) [0|0] "" Vector__XXX
 SG_ APP_w338_tradfcLfTempError : 17|1@1+ (1,0) [0|0] "" Vector__XXX
 SG_ APP_w337_tradfcRfPmicError : 16|1@1+ (1,0) [0|0] "" Vector__XXX
 SG_ APP_w336_tradfcLfPmicError : 15|1@1+ (1,0) [0|0] "" Vector__XXX
 SG_ APP_w335_tradfcRfSensorError : 14|1@1+ (1,0) [0|0] "" Vector__XXX
 SG_ APP_w334_frontCameraOccluded : 13|1@1+ (1,0) [0|0] "" Vector__XXX
 SG_ APP_w333_fsdUnavailableLocation : 12|1@1+ (1,0) [0|0] "" Vector__XXX
 SG_ APP_w332_cameraPositionsSwapped : 11|1@1+ (1,0) [0|0] "" Vector__XXX
 SG_ APP_w331_fsdDegradedUnavailable : 10|1@1+ (1,0) [0|0] "" Vector__XXX
 SG_ APP_w330_cabinCameraFault : 9|1@1+ (1,0) [0|0] "" Vector__XXX
 SG_ APP_w329_evasiveManeuver : 8|1@1+ (1,0) [0|0] "" Vector__XXX
 SG_ APP_w328_autoparkDegraded : 7|1@1+ (1,0) [0|0] "" Vector__XXX
 SG_ APP_w327_vehicleConfigMismatch : 6|1@1+ (1,0) [0|0] "" Vector__XXX
 SG_ APP_w326_kernelPanic : 5|1@1+ (1,0) [0|0] "" Vector__XXX
 SG_ APP_w325_watchdogReset : 4|1@1+ (1,0) [0|0] "" Vector__XXX
 SG_ APP_w324_adspMia : 3|1@1+ (1,0) [0|0] "" Vector__XXX
 SG_ APP_w323_drivableSpaceFCW : 2|1@1+ (1,0) [0|0] "" Vector__XXX
 SG_ APP_w322_autoWiperWash : 1|1@1+ (1,0) [0|0] "" Vector__XXX
 SG_ APP_w321_bmsMia : 0|1@1+ (1,0) [0|0] "" Vector__XXX

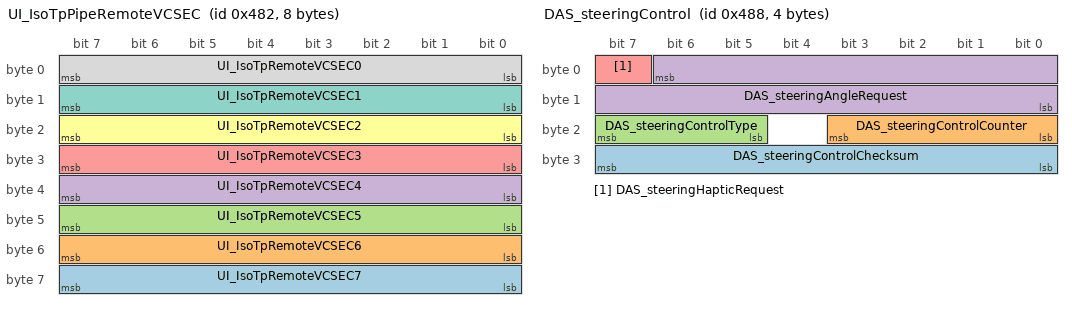
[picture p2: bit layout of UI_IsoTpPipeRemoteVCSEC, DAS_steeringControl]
BO_ 1154 UI_IsoTpPipeRemoteVCSEC: 8 Vector__XXX
 SG_ UI_IsoTpRemoteVCSEC7 : 63|8@0+ (1,0) [0|0] "" Vector__XXX
 SG_ UI_IsoTpRemoteVCSEC6 : 55|8@0+ (1,0) [0|0] "" Vector__XXX
 SG_ UI_IsoTpRemoteVCSEC5 : 47|8@0+ (1,0) [0|0] "" Vector__XXX
 SG_ UI_IsoTpRemoteVCSEC4 : 39|8@0+ (1,0) [0|0] "" Vector__XXX
 SG_ UI_IsoTpRemoteVCSEC3 : 31|8@0+ (1,0) [0|0] "" Vector__XXX
 SG_ UI_IsoTpRemoteVCSEC2 : 23|8@0+ (1,0) [0|0] "" Vector__XXX
 SG_ UI_IsoTpRemoteVCSEC1 : 15|8@0+ (1,0) [0|0] "" Vector__XXX
 SG_ UI_IsoTpRemoteVCSEC0 : 7|8@0+ (1,0) [0|0] "" Vector__XXX

BO_ 1160 DAS_steeringControl: 4 Vector__XXX
 SG_ DAS_steeringControlChecksum : 31|8@0+ (1,0) [0|0] "" Vector__XXX
 SG_ DAS_steeringControlCounter : 19|4@0+ (1,0) [0|0] "" Vector__XXX
 SG_ DAS_steeringControlType : 23|3@0+ (1,0) [0|0] "" Vector__XXX
 SG_ DAS_steeringAngleRequest : 6|15@0+ (0.1,-1638.35) [0|0] "" Vector__XXX
 SG_ DAS_steeringHapticRequest : 7|1@0+ (1,0) [0|0] "" Vector__XXX

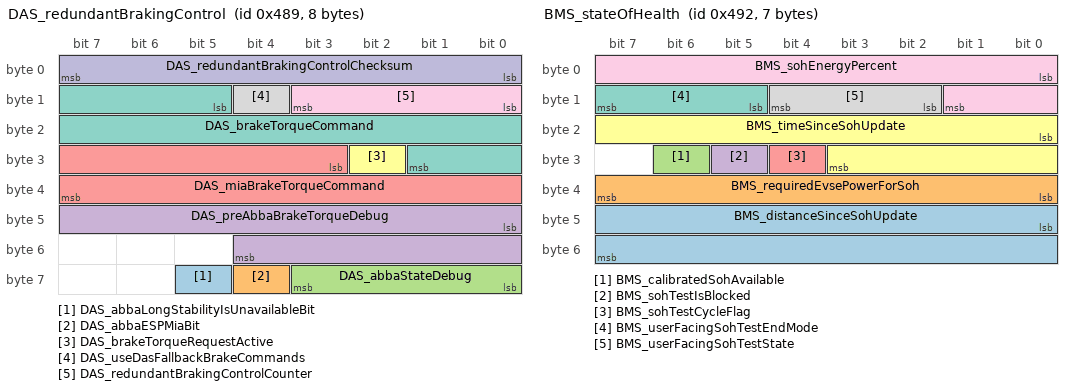
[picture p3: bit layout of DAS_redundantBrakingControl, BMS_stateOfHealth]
BO_ 1161 DAS_redundantBrakingControl: 8 Vector__XXX
 SG_ DAS_abbaLongStabilityIsUnavailableBit : 61|1@1+ (1,0) [0|0] "" Vector__XXX
 SG_ DAS_abbaESPMiaBit : 60|1@1+ (1,0) [0|0] "" Vector__XXX
 SG_ DAS_abbaStateDebug : 56|4@1+ (1,0) [0|0] "" Vector__XXX
 SG_ DAS_preAbbaBrakeTorqueDebug : 40|13@1+ (3,0) [0|0] "" Vector__XXX
 SG_ DAS_miaBrakeTorqueCommand : 27|13@1+ (3,0) [0|0] "" Vector__XXX
 SG_ DAS_brakeTorqueRequestActive : 26|1@1+ (1,0) [0|0] "" Vector__XXX
 SG_ DAS_brakeTorqueCommand : 13|13@1+ (3,0) [0|0] "" Vector__XXX
 SG_ DAS_useDasFallbackBrakeCommands : 12|1@1+ (1,0) [0|0] "" Vector__XXX
 SG_ DAS_redundantBrakingControlCounter : 8|4@1+ (1,0) [0|0] "" Vector__XXX
 SG_ DAS_redundantBrakingControlChecksum : 0|8@1+ (1,0) [0|0] "" Vector__XXX

BO_ 1170 BMS_stateOfHealth: 7 Vector__XXX
 SG_ BMS_distanceSinceSohUpdate : 40|16@1+ (1,0) [0|0] "" Vector__XXX
 SG_ BMS_requiredEvsePowerForSoh : 32|8@1+ (0.125,0) [0|0] "" Vector__XXX
 SG_ BMS_calibratedSohAvailable : 30|1@1+ (1,0) [0|0] "" Vector__XXX
 SG_ BMS_sohTestIsBlocked : 29|1@1+ (1,0) [0|0] "" Vector__XXX
 SG_ BMS_sohTestCycleFlag : 28|1@1+ (1,0) [0|0] "" Vector__XXX
 SG_ BMS_timeSinceSohUpdate : 16|12@1+ (1,0) [0|0] "" Vector__XXX
 SG_ BMS_userFacingSohTestEndMode : 13|3@1+ (1,0) [0|0] "" Vector__XXX
 SG_ BMS_userFacingSohTestState : 10|3@1+ (1,0) [0|0] "" Vector__XXX
 SG_ BMS_sohEnergyPercent : 0|10@1+ (0.1,0) [0|0] "" Vector__XXX

BO_ 1173 VCFRONT_LVHealthDebug: 8 Vector__XXX
 SG_ VCFRONT_lvBatteryExtendedOverVol m1 : 42|2@1+ (1,0) [0|0] "" Vector__XXX
 SG_ VCFRONT_lvBatteryImpedanceCheckR m1 : 40|2@1+ (1,0) [0|0] "" Vector__XXX
 SG_ VCFRONT_lvBatteryConfigurationCh m1 : 38|2@1+ (1,0) [0|0] "" Vector__XXX
 SG_ VCFRONT_lvBatteryCapabilityAccur m1 : 36|2@1+ (1,0) [0|0] "" Vector__XXX
 SG_ VCFRONT_activeDecelPowerCheckRes m1 : 34|2@1+ (1,0) [0|0] "" Vector__XXX
 SG_ VCFRONT_pcsOpenCircuitCheckResul m1 : 32|2@1+ (1,0) [0|0] "" Vector__XXX
 SG_ VCFRONT_LVBattElecDiscUnknownChe m1 : 30|2@1+ (1,0) [0|0] "" Vector__XXX
 SG_ VCFRONT_LVBattElecDiscCheckResul m1 : 28|2@1+ (1,0) [0|0] "" Vector__XXX
 SG_ VCFRONT_IBSMIACheckResult m1 : 26|2@1+ (1,0) [0|0] "" Vector__XXX
 SG_ VCFRONT_LVHEALTH_lvBatteryExtend m0 : 25|1@1+ (1,0) [0|0] "" Vector__XXX
 SG_ VCFRONT_LVHEALTH_lvBatteryImpeda m0 : 24|1@1+ (1,0) [0|0] "" Vector__XXX
 SG_ VCFRONT_pcsMIACheckResult m1 : 24|2@1+ (1,0) [0|0] "" Vector__XXX
 SG_ VCFRONT_LVHEALTH_lvBatteryConfig m0 : 23|1@1+ (1,0) [0|0] "" Vector__XXX
 SG_ VCFRONT_LVHEALTH_lvBatteryCapabi m0 : 22|1@1+ (1,0) [0|0] "" Vector__XXX
 SG_ VCFRONT_pcsNotActiveCheckResult m1 : 22|2@1+ (1,0) [0|0] "" Vector__XXX
 SG_ VCFRONT_LVHEALTH_activeDecelPowe m0 : 21|1@1+ (1,0) [0|0] "" Vector__XXX
 SG_ VCFRONT_LVHEALTH_pcsOpenCircuit m0 : 20|1@1+ (1,0) [0|0] "" Vector__XXX
 SG_ VCFRONT_pcsEFuseOffCheckResult m1 : 20|2@1+ (1,0) [0|0] "" Vector__XXX
 SG_ VCFRONT_LVHEALTH_LVBatteryE_0000 m0 : 19|1@1+ (1,0) [0|0] "" Vector__XXX
 SG_ VCFRONT_LVHEALTH_LVBatteryElecDi m0 : 18|1@1+ (1,0) [0|0] "" Vector__XXX
 SG_ VCFRONT_lvBatteryCommsMiaCheckRe m1 : 18|2@1+ (1,0) [0|0] "" Vector__XXX
 SG_ VCFRONT_LVHEALTH_IBSMIA m0 : 17|1@1+ (1,0) [0|0] "" Vector__XXX
 SG_ VCFRONT_LVBMBEFuseCheckResult m1 : 16|2@1+ (1,0) [0|0] "" Vector__XXX
 SG_ VCFRONT_LVHEALTH_pcsMIA m0 : 16|1@1+ (1,0) [0|0] "" Vector__XXX
 SG_ VCFRONT_LVHEALTH_pcsNotActive m0 : 15|1@1+ (1,0) [0|0] "" Vector__XXX
 SG_ VCFRONT_LVHEALTH_pcsEFuseOff m0 : 14|1@1+ (1,0) [0|0] "" Vector__XXX
 SG_ VCFRONT_revBattEFuseCheckResult m1 : 14|2@1+ (1,0) [0|0] "" Vector__XXX
 SG_ VCFRONT_LVHEALTH_lvBatteryCommsM m0 : 13|1@1+ (1,0) [0|0] "" Vector__XXX
 SG_ VCFRONT_LVHEALTH_LVBMBEFuseOpen m0 : 12|1@1+ (1,0) [0|0] "" Vector__XXX
 SG_ VCFRONT_criticalPulloverEnergyCh m1 : 12|2@1+ (1,0) [0|0] "" Vector__XXX
 SG_ VCFRONT_LVHEALTH_revBattEFuseOff m0 : 11|1@1+ (1,0) [0|0] "" Vector__XXX
 SG_ VCFRONT_LVHEALTH_criticalPullove m0 : 10|1@1+ (1,0) [0|0] "" Vector__XXX
 SG_ VCFRONT_activeDecelEnergyCheckRe m1 : 10|2@1+ (1,0) [0|0] "" Vector__XXX
 SG_ VCFRONT_LVHEALTH_activeDecelEner m0 : 9|1@1+ (1,0) [0|0] "" Vector__XXX
 SG_ VCFRONT_LVHEALTH_placeholder m0 : 8|1@1+ (1,0) [0|0] "" Vector__XXX
 SG_ VCFRONT_placeholderCheckResult m1 : 8|2@1+ (1,0) [0|0] "" Vector__XXX
 SG_ VCFRONT_LVHealthDebugIndex M : 0|4@1+ (1,0) [0|0] "" Vector__XXX

BO_ 1175 VCBATT1_LVHealthDebug: 8 Vector__XXX
 SG_ VCBATT1_bridgeOcReset m2 : 60|1@1+ (1,0) [0|0] "" Vector__XXX
 SG_ VCBATT1_lvBattCriticalResistance m0 : 60|2@1+ (1,0) [0|0] "" Vector__XXX
 SG_ VCBATT1_bridgeOcRevBattFaultInje m2 : 59|1@1+ (1,0) [0|0] "" Vector__XXX
 SG_ VCBATT1_bridgeOcFaultActive m2 : 58|1@1+ (1,0) [0|0] "" Vector__XXX
 SG_ VCBATT1_lvBattImpedanceCheckResu m0 : 58|2@1+ (1,0) [0|0] "" Vector__XXX
 SG_ VCBATT1_lvBattConfigurationCheck m0 : 56|2@1+ (1,0) [0|0] "" Vector__XXX
 SG_ VCBATT1_revBattEFuseState m2 : 56|2@1+ (1,0) [0|0] "" Vector__XXX
 SG_ VCBATT1_bridgeShutdownActive m1 : 55|1@1+ (1,0) [0|0] "" Vector__XXX
 SG_ VCBATT1_lvBattCapabilityAccCheck m0 : 54|2@1+ (1,0) [0|0] "" Vector__XXX
 SG_ VCBATT1_uvLoadshedFaultInject m1 : 54|1@1+ (1,0) [0|0] "" Vector__XXX
 SG_ VCBATT1_uvTimingSelfTestEn m1 : 53|1@1+ (1,0) [0|0] "" Vector__XXX
 SG_ VCBATT1_lvBattEnergyPulloverChec m0 : 52|2@1+ (1,0) [0|0] "" Vector__XXX
 SG_ VCBATT1_lvBattPowerActiveDecelCh m0 : 50|2@1+ (1,0) [0|0] "" Vector__XXX
 SG_ VCBATT1_lvBattEnergyActiveDecelC m0 : 48|2@1+ (1,0) [0|0] "" Vector__XXX
 SG_ VCBATT1_lvBattEnergyUrgentPullov m0 : 46|2@1+ (1,0) [0|0] "" Vector__XXX
 SG_ VCBATT1_lvBattISenseRationalityC m0 : 44|2@1+ (1,0) [0|0] "" Vector__XXX
 SG_ VCBATT1_selfTestsOpportunis_0000 m4 : 44|1@1+ (1,0) [0|0] "" Vector__XXX
 SG_ VCBATT1_selfTestsOpportunisticBl m4 : 43|1@1+ (1,0) [0|0] "" Vector__XXX
 SG_ VCBATT1_lvBattVSenseRationalityC m0 : 42|2@1+ (1,0) [0|0] "" Vector__XXX
 SG_ VCBATT1_revBattGateVoltage m2 : 42|13@1+ (0.005443676098,0) [0|0] "" Vector__XXX
 SG_ VCBATT1_selfTestsBlockedByGTWMIA m4 : 42|1@1+ (1,0) [0|0] "" Vector__XXX
 SG_ VCBATT1_ocFastFaultActive m2 : 41|1@1+ (1,0) [0|0] "" Vector__XXX
 SG_ VCBATT1_selfTestsBlockedByPCSMIA m4 : 41|1@1+ (1,0) [0|0] "" Vector__XXX
 SG_ VCBATT1_uvReferenceMonitor m1 : 41|12@1+ (0.005443676098,0) [0|0] "" Vector__XXX
 SG_ VCBATT1_lvBattSensorCommsCheckRe m0 : 40|2@1+ (1,0) [0|0] "" Vector__XXX
 SG_ VCBATT1_ocMediumFaultActive m2 : 40|1@1+ (1,0) [0|0] "" Vector__XXX
 SG_ VCBATT1_selfTestsBlockedByVCRigh m4 : 40|1@1+ (1,0) [0|0] "" Vector__XXX
 SG_ VCBATT1_uvLoadshedReset m1 : 40|1@1+ (1,0) [0|0] "" Vector__XXX
 SG_ VCBATT1_ocSlowFaultActive m2 : 39|1@1+ (1,0) [0|0] "" Vector__XXX
 SG_ VCBATT1_selfTestsBlockedByVCFron m4 : 39|1@1+ (1,0) [0|0] "" Vector__XXX
 SG_ VCBATT1_uvLoadshedFaultActive m1 : 39|1@1+ (1,0) [0|0] "" Vector__XXX
 SG_ VCBATT1_lvBattEFuseStateCheckRes m0 : 38|2@1+ (1,0) [0|0] "" Vector__XXX
 SG_ VCBATT1_selfTestsBlockedByFactor m4 : 38|1@1+ (1,0) [0|0] "" Vector__XXX
 SG_ VCBATT1_selfTestsBlockedByOutOfR m4 : 37|1@1+ (1,0) [0|0] "" Vector__XXX
 SG_ VCBATT1_upstreamLoadshedEfuseLVS m1 : 37|2@1+ (1,0) [0|0] "" Vector__XXX
 SG_ VCBATT1_lvBattCommsCheckResult m0 : 36|2@1+ (1,0) [0|0] "" Vector__XXX
 SG_ VCBATT1_selfTestsBlockedByDefogT m4 : 36|1@1+ (1,0) [0|0] "" Vector__XXX
 SG_ VCBATT1_selfTestsBlockedByS_0000 m4 : 35|1@1+ (1,0) [0|0] "" Vector__XXX
 SG_ VCBATT1_lvBattElecConnectionConf m0 : 34|2@1+ (1,0) [0|0] "" Vector__XXX
 SG_ VCBATT1_selfTestsBlockedByLoadsh m4 : 34|1@1+ (1,0) [0|0] "" Vector__XXX
 SG_ VCBATT1_selfTestsBlockedByTherma m4 : 33|1@1+ (1,0) [0|0] "" Vector__XXX
 SG_ VCBATT1_hvcDualPowerFeedVoltage m3 : 32|12@1+ (0.005443676098,0) [0|0] "" Vector__XXX
 SG_ VCBATT1_lvBattElecConnectionChec m0 : 32|2@1+ (1,0) [0|0] "" Vector__XXX
 SG_ VCBATT1_ocSelfTestFailureReason m2 : 32|7@1+ (1,0) [0|0] "" Vector__XXX
 SG_ VCBATT1_selfTestsBlockedByLowBus m4 : 32|1@1+ (1,0) [0|0] "" Vector__XXX
 SG_ VCBATT1_selfTestsBlockedByHardwa m4 : 31|1@1+ (1,0) [0|0] "" Vector__XXX
 SG_ VCBATT1_revBattEFuseStateCheckRe m0 : 30|2@1+ (1,0) [0|0] "" Vector__XXX
 SG_ VCBATT1_selfTestsBlockedByB_0000 m4 : 30|1@1+ (1,0) [0|0] "" Vector__XXX
 SG_ VCBATT1_selfTestsBlockedByUnpark m4 : 29|1@1+ (1,0) [0|0] "" Vector__XXX
 SG_ VCBATT1_eFuseConfigurationCheckR m0 : 28|2@1+ (1,0) [0|0] "" Vector__XXX
 SG_ VCBATT1_selfTestsBlockedByECUMis m4 : 28|1@1+ (1,0) [0|0] "" Vector__XXX
 SG_ VCBATT1_selfTestsBlockedByOTAAct m4 : 27|1@1+ (1,0) [0|0] "" Vector__XXX
 SG_ VCBATT1_hardwareProtectionsArmSt m0 : 26|2@1+ (1,0) [0|0] "" Vector__XXX
 SG_ VCBATT1_selfTestsBlockedByTestSt m4 : 26|1@1+ (1,0) [0|0] "" Vector__XXX
 SG_ VCBATT1_selfTestsBlockedBySelfTe m4 : 25|1@1+ (1,0) [0|0] "" Vector__XXX
 SG_ VCBATT1_upstreamLoadshedEfuseVol m1 : 25|12@1+ (0.005443676098,0) [0|0] "" Vector__XXX
 SG_ VCBATT1_ARailLocked m1 : 24|1@1+ (1,0) [0|0] "" Vector__XXX
 SG_ VCBATT1_hvcRightDomainPowerSelfT m0 : 24|2@1+ (1,0) [0|0] "" Vector__XXX
 SG_ VCBATT1_selfTestsBlockedByBridge m4 : 24|1@1+ (1,0) [0|0] "" Vector__XXX
 SG_ VCBATT1_bridgeOutState m1 : 23|1@1+ (1,0) [0|0] "" Vector__XXX
 SG_ VCBATT1_selfTestsBlockedByLVBMBA m4 : 23|1@1+ (1,0) [0|0] "" Vector__XXX
 SG_ VCBATT1_dualPowerLoadsSelfTestCh m0 : 22|2@1+ (1,0) [0|0] "" Vector__XXX
 SG_ VCBATT1_ovTimingSelfTestEn m1 : 22|1@1+ (1,0) [0|0] "" Vector__XXX
 SG_ VCBATT1_selfTestsBlockedByL_0001 m4 : 22|1@1+ (1,0) [0|0] "" Vector__XXX
 SG_ VCBATT1_ovBridgeFaultInject m1 : 21|1@1+ (1,0) [0|0] "" Vector__XXX
 SG_ VCBATT1_selfTestsBlockedByLVBatt m4 : 21|1@1+ (1,0) [0|0] "" Vector__XXX
 SG_ VCBATT1_hvcRightDomainPowerFeedV m3 : 20|12@1+ (0.005443676098,0) [0|0] "" Vector__XXX
 SG_ VCBATT1_ovBridgeReset m1 : 20|1@1+ (1,0) [0|0] "" Vector__XXX
 SG_ VCBATT1_overcurrentSelfTestCheck m0 : 20|2@1+ (1,0) [0|0] "" Vector__XXX
 SG_ VCBATT1_selfTestsBlockedByL_0002 m4 : 20|1@1+ (1,0) [0|0] "" Vector__XXX
 SG_ VCBATT1_selfTestsBlockedByL_0000 m4 : 19|1@1+ (1,0) [0|0] "" Vector__XXX
 SG_ VCBATT1_overcurrentTripStateChec m0 : 18|2@1+ (1,0) [0|0] "" Vector__XXX
 SG_ VCBATT1_selfTestsBlockedByMissin m4 : 18|1@1+ (1,0) [0|0] "" Vector__XXX
 SG_ VCBATT1_ovProtectionState m1 : 17|3@1+ (1,0) [0|0] "" Vector__XXX
 SG_ VCBATT1_selfTestsBlockedByPCSNot m4 : 17|1@1+ (1,0) [0|0] "" Vector__XXX
 SG_ VCBATT1_ocSenseAmpCurrent m2 : 16|12@1+ (0.1,0) [0|0] "" Vector__XXX
 SG_ VCBATT1_ovBridgeShutdownFaultAct m1 : 16|1@1+ (1,0) [0|0] "" Vector__XXX
 SG_ VCBATT1_overvoltageSelfTestCheck m0 : 16|2@1+ (1,0) [0|0] "" Vector__XXX
 SG_ VCBATT1_selfTestsBlockedByLVBusC m4 : 16|1@1+ (1,0) [0|0] "" Vector__XXX
 SG_ VCBATT1_selfTestsBlockedByDrive m4 : 15|1@1+ (1,0) [0|0] "" Vector__XXX
 SG_ VCBATT1_overvoltageTripStateChec m0 : 14|2@1+ (1,0) [0|0] "" Vector__XXX
 SG_ VCBATT1_undervoltageSelfTestChec m0 : 12|2@1+ (1,0) [0|0] "" Vector__XXX
 SG_ VCBATT1_selfTestOrchestratorBloc m4 : 10|5@1+ (1,0) [0|0] "" Vector__XXX
 SG_ VCBATT1_undervoltageTripStateChe m0 : 10|2@1+ (1,0) [0|0] "" Vector__XXX
 SG_ VCBATT1_hvcLeftDomainPowerFeedVo m3 : 8|12@1+ (0.005443676098,0) [0|0] "" Vector__XXX
 SG_ VCBATT1_ocSelfTestPWM m2 : 8|7@1+ (1,0) [0|0] "" Vector__XXX
 SG_ VCBATT1_selfTestsBusControlReque m4 : 8|2@1+ (1,0) [0|0] "" Vector__XXX
 SG_ VCBATT1_vcfrontCommsCheckResult m0 : 8|2@1+ (1,0) [0|0] "" Vector__XXX
 SG_ VCBATT1_ocSelfTestEnablePinActiv m2 : 7|1@1+ (1,0) [0|0] "" Vector__XXX
 SG_ VCBATT1_bridgeEFuseSelfTestCheck m0 : 6|2@1+ (1,0) [0|0] "" Vector__XXX
 SG_ VCBATT1_bridgeStateCheckResult m0 : 4|2@1+ (1,0) [0|0] "" Vector__XXX
 SG_ VCBATT1_dualPowerLoadsSelfTestSM m3 : 4|3@1+ (1,0) [0|0] "" Vector__XXX
 SG_ VCBATT1_ocProtectionState m2 : 4|3@1+ (1,0) [0|0] "" Vector__XXX
 SG_ VCBATT1_ovReferenceMonitor m1 : 4|12@1+ (0.005443676098,0) [0|0] "" Vector__XXX
 SG_ VCBATT1_selfTestsStartReason m4 : 4|3@1+ (1,0) [0|0] "" Vector__XXX
 SG_ VCBATT1_LVHealthDebugIndex M : 0|4@1+ (1,0) [0|0] "" Vector__XXX

BO_ 1176 VCFRONT1_LVHealthDebug: 8 Vector__XXX
 SG_ VCFRONT1_bridgeShutdownActive m1 : 62|1@1+ (1,0) [0|0] "" Vector__XXX
 SG_ VCFRONT1_ovClampActive m2 : 60|1@1+ (1,0) [0|0] "" Vector__XXX
 SG_ VCFRONT1_upstreamLoadshedEfuseLV m1 : 60|2@1+ (1,0) [0|0] "" Vector__XXX
 SG_ VCFRONT1_pcsCriticalResistanceCh m0 : 50|2@1+ (1,0) [0|0] "" Vector__XXX
 SG_ VCFRONT1_hvcEFuseStateCheckResul m0 : 48|2@1+ (1,0) [0|0] "" Vector__XXX
 SG_ VCFRONT1_ovClampMonitorVoltage1 m2 : 48|12@1+ (0.005443676098,0) [0|0] "" Vector__XXX
 SG_ VCFRONT1_upstreamLoadshedVoltage m1 : 48|12@1+ (0.005443676098,0) [0|0] "" Vector__XXX
 SG_ VCFRONT1_pcsOvClampArmStateCheck m0 : 46|2@1+ (1,0) [0|0] "" Vector__XXX
 SG_ VCFRONT1_BRailLocked m1 : 44|1@1+ (1,0) [0|0] "" Vector__XXX
 SG_ VCFRONT1_pcsOvClampTripStateChec m0 : 44|2@1+ (1,0) [0|0] "" Vector__XXX
 SG_ VCFRONT1_bridgeOutState m1 : 43|1@1+ (1,0) [0|0] "" Vector__XXX
 SG_ VCFRONT1_pcsOvClampBusRationalit m0 : 42|2@1+ (1,0) [0|0] "" Vector__XXX
 SG_ VCFRONT1_ovProtectionState m1 : 40|3@1+ (1,0) [0|0] "" Vector__XXX
 SG_ VCFRONT1_pcsOvClampReferenceRati m0 : 40|2@1+ (1,0) [0|0] "" Vector__XXX
 SG_ VCFRONT1_ovTimingSelfTestEn m1 : 39|1@1+ (1,0) [0|0] "" Vector__XXX
 SG_ VCFRONT1_ovBridgeReset m1 : 38|1@1+ (1,0) [0|0] "" Vector__XXX
 SG_ VCFRONT1_pcsSupportStatusCheckRe m0 : 38|2@1+ (1,0) [0|0] "" Vector__XXX
 SG_ VCFRONT1_ovBridgeFaultInject m1 : 37|1@1+ (1,0) [0|0] "" Vector__XXX
 SG_ VCFRONT1_ovBridgeShutdownFaultAc m1 : 36|1@1+ (1,0) [0|0] "" Vector__XXX
 SG_ VCFRONT1_ovClampReferenceVoltage m2 : 36|12@1+ (0.005443676098,0) [0|0] "" Vector__XXX
 SG_ VCFRONT1_pcsPowerCapabilityCheck m0 : 36|2@1+ (1,0) [0|0] "" Vector__XXX
 SG_ VCFRONT1_pcsCommsCheckResult m0 : 34|2@1+ (1,0) [0|0] "" Vector__XXX
 SG_ VCFRONT1_pcsElecConnCheckResult m0 : 32|2@1+ (1,0) [0|0] "" Vector__XXX
 SG_ VCFRONT1_pcsElecConnConfidenceCh m0 : 30|2@1+ (1,0) [0|0] "" Vector__XXX
 SG_ VCFRONT1_pcsEFuseStateCheckResul m0 : 28|2@1+ (1,0) [0|0] "" Vector__XXX
 SG_ VCFRONT1_eFuseConfigurationCheck m0 : 26|2@1+ (1,0) [0|0] "" Vector__XXX
 SG_ VCFRONT1_ovClampBusVoltage m2 : 24|12@1+ (0.005443676098,0) [0|0] "" Vector__XXX
 SG_ VCFRONT1_ovReferenceMonitor m1 : 24|12@1+ (0.005443676098,0) [0|0] "" Vector__XXX
 SG_ VCFRONT1_pcsShutdownArmStateChec m0 : 24|2@1+ (1,0) [0|0] "" Vector__XXX
 SG_ VCFRONT1_pcsShutdownSelfTestChec m0 : 22|2@1+ (1,0) [0|0] "" Vector__XXX
 SG_ VCFRONT1_pcsShutdownTripStateChe m0 : 20|2@1+ (1,0) [0|0] "" Vector__XXX
 SG_ VCFRONT1_uvTimingSelfTestEn m1 : 20|1@1+ (1,0) [0|0] "" Vector__XXX
 SG_ VCFRONT1_hardwareProtectionsArmS m0 : 18|2@1+ (1,0) [0|0] "" Vector__XXX
 SG_ VCFRONT1_ovClampMonitorVoltage3 m3 : 16|12@1+ (0.005443676098,0) [0|0] "" Vector__XXX
 SG_ VCFRONT1_overvoltageSelfTestChec m0 : 16|2@1+ (1,0) [0|0] "" Vector__XXX
 SG_ VCFRONT1_overvoltageTripStateChe m0 : 14|2@1+ (1,0) [0|0] "" Vector__XXX
 SG_ VCFRONT1_dcdcEnableVoltage m2 : 12|12@1+ (0.005443676098,0) [0|0] "" Vector__XXX
 SG_ VCFRONT1_undervoltageSelfTestChe m0 : 12|2@1+ (1,0) [0|0] "" Vector__XXX
 SG_ VCFRONT1_ovShutdownFaultInject m2 : 11|1@1+ (1,0) [0|0] "" Vector__XXX
 SG_ VCFRONT1_ovShutdownFaultActive m2 : 10|1@1+ (1,0) [0|0] "" Vector__XXX
 SG_ VCFRONT1_undervoltageTripStateCh m0 : 10|2@1+ (1,0) [0|0] "" Vector__XXX
 SG_ VCFRONT1_ovShutdownArmedFeedback m2 : 9|1@1+ (1,0) [0|0] "" Vector__XXX
 SG_ VCFRONT1_ovShutdownArmed m2 : 8|1@1+ (1,0) [0|0] "" Vector__XXX
 SG_ VCFRONT1_uvReferenceMonitor m1 : 8|12@1+ (0.005443676098,0) [0|0] "" Vector__XXX
 SG_ VCFRONT1_vcbattCommsCheckResult m0 : 8|2@1+ (1,0) [0|0] "" Vector__XXX
 SG_ VCFRONT1_bridgeEFuseSelfTestChec m0 : 6|2@1+ (1,0) [0|0] "" Vector__XXX
 SG_ VCFRONT1_uvLoadshedReset m1 : 6|1@1+ (1,0) [0|0] "" Vector__XXX
 SG_ VCFRONT1_uvLoadshedFaultInject m1 : 5|1@1+ (1,0) [0|0] "" Vector__XXX
 SG_ VCFRONT1_bridgeStateCheckResult m0 : 4|2@1+ (1,0) [0|0] "" Vector__XXX
 SG_ VCFRONT1_ovClampMonitorVoltage2 m3 : 4|12@1+ (0.005443676098,0) [0|0] "" Vector__XXX
 SG_ VCFRONT1_pcsOvShutdownState m2 : 4|4@1+ (1,0) [0|0] "" Vector__XXX
 SG_ VCFRONT1_uvLoadshedFaultActive m1 : 4|1@1+ (1,0) [0|0] "" Vector__XXX
 SG_ VCFRONT1_LVHealthDebugIndex M : 0|4@1+ (1,0) [0|0] "" Vector__XXX

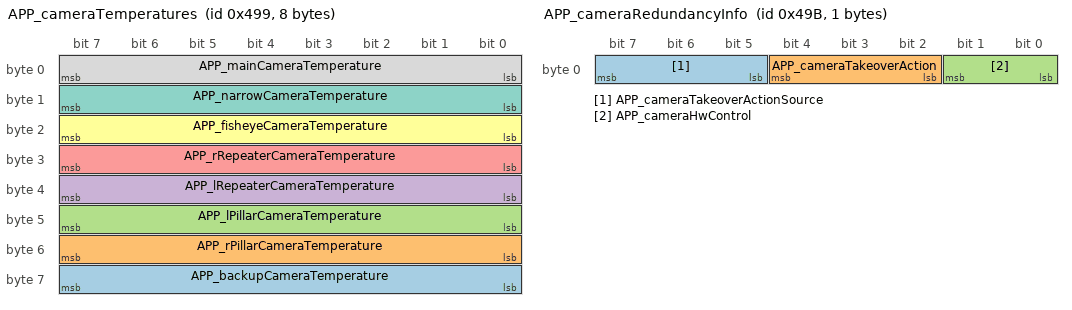
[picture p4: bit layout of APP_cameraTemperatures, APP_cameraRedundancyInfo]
BO_ 1177 APP_cameraTemperatures: 8 Vector__XXX
 SG_ APP_backupCameraTemperature : 56|8@1+ (1,-60) [0|0] "" Vector__XXX
 SG_ APP_rPillarCameraTemperature : 48|8@1+ (1,-60) [0|0] "" Vector__XXX
 SG_ APP_lPillarCameraTemperature : 40|8@1+ (1,-60) [0|0] "" Vector__XXX
 SG_ APP_lRepeaterCameraTemperature : 32|8@1+ (1,-60) [0|0] "" Vector__XXX
 SG_ APP_rRepeaterCameraTemperature : 24|8@1+ (1,-60) [0|0] "" Vector__XXX
 SG_ APP_fisheyeCameraTemperature : 16|8@1+ (1,-60) [0|0] "" Vector__XXX
 SG_ APP_narrowCameraTemperature : 8|8@1+ (1,-60) [0|0] "" Vector__XXX
 SG_ APP_mainCameraTemperature : 0|8@1+ (1,-60) [0|0] "" Vector__XXX

BO_ 1179 APP_cameraRedundancyInfo: 1 Vector__XXX
 SG_ APP_cameraTakeoverActionSource : 5|3@1+ (1,0) [0|0] "" Vector__XXX
 SG_ APP_cameraTakeoverAction : 2|3@1+ (1,0) [0|0] "" Vector__XXX
 SG_ APP_cameraHwControl : 0|2@1+ (1,0) [0|0] "" Vector__XXX

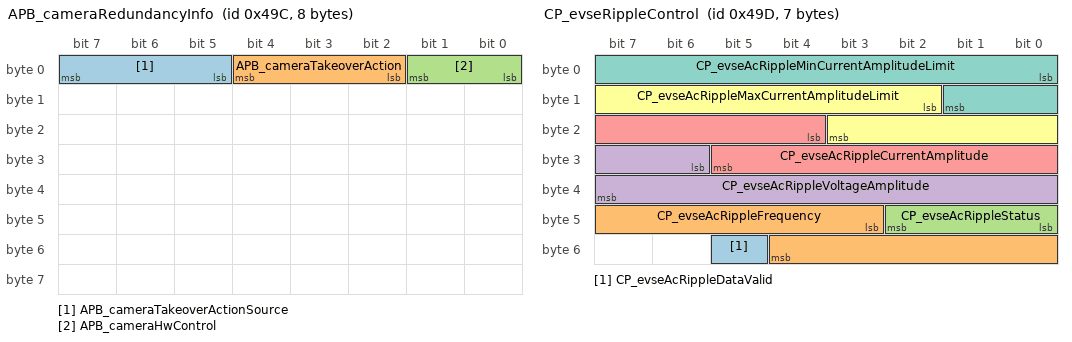
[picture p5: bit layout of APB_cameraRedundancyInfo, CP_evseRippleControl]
BO_ 1180 APB_cameraRedundancyInfo: 8 Vector__XXX
 SG_ APB_cameraTakeoverActionSource : 5|3@1+ (1,0) [0|0] "" Vector__XXX
 SG_ APB_cameraTakeoverAction : 2|3@1+ (1,0) [0|0] "" Vector__XXX
 SG_ APB_cameraHwControl : 0|2@1+ (1,0) [0|0] "" Vector__XXX

BO_ 1181 CP_evseRippleControl: 7 Vector__XXX
 SG_ CP_evseAcRippleDataValid : 53|1@1+ (1,0) [0|0] "" Vector__XXX
 SG_ CP_evseAcRippleFrequency : 43|10@1+ (1,0) [0|0] "" Vector__XXX
 SG_ CP_evseAcRippleStatus : 40|3@1+ (1,0) [0|0] "" Vector__XXX
 SG_ CP_evseAcRippleVoltageAmplitude : 30|10@1+ (1,0) [0|0] "" Vector__XXX
 SG_ CP_evseAcRippleCurrentAmplitude : 20|10@1+ (1,0) [0|0] "" Vector__XXX
 SG_ CP_evseAcRippleMaxCurrentAmplitudeLimit : 10|10@1+ (1,0) [0|0] "" Vector__XXX
 SG_ CP_evseAcRippleMinCurrentAmplitudeLimit : 0|10@1+ (1,0) [0|0] "" Vector__XXX

BO_ 1206 VCSEC_rawRSSI0: 8 Vector__XXX
 SG_ VCSEC_frontRightRSSI0Channel m5 : 48|6@1+ (1,0) [0|0] "" Vector__XXX
 SG_ VCSEC_nfcRSSI0Channel m3 : 48|6@1+ (1,0) [0|0] "" Vector__XXX
 SG_ VCSEC_rearRSSI0Channel m1 : 48|6@1+ (1,0) [0|0] "" Vector__XXX
 SG_ VCSEC_rearRightRSSI0Channel m2 : 48|6@1+ (1,0) [0|0] "" Vector__XXX
 SG_ VCSEC_rightRSSI0Channel m0 : 48|6@1+ (1,0) [0|0] "" Vector__XXX
 SG_ VCSEC_frontRightReverseRawRSSI0 m5 : 40|8@1- (1,0) [0|0] "" Vector__XXX
 SG_ VCSEC_nfcReverseRawRSSI0 m3 : 40|8@1- (1,0) [0|0] "" Vector__XXX
 SG_ VCSEC_rearReverseRawRSSI0 m1 : 40|8@1- (1,0) [0|0] "" Vector__XXX
 SG_ VCSEC_rearRightReverseRawRSSI0 m2 : 40|8@1- (1,0) [0|0] "" Vector__XXX
 SG_ VCSEC_rightReverseRawRSSI0 m0 : 40|8@1- (1,0) [0|0] "" Vector__XXX
 SG_ VCSEC_frontRightRawRSSI0 m5 : 32|8@1- (1,0) [0|0] "" Vector__XXX
 SG_ VCSEC_nfcRawRSSI0 m3 : 32|8@1- (1,0) [0|0] "" Vector__XXX
 SG_ VCSEC_rearRawRSSI0 m1 : 32|8@1- (1,0) [0|0] "" Vector__XXX
 SG_ VCSEC_rearRightRawRSSI0 m2 : 32|8@1- (1,0) [0|0] "" Vector__XXX
 SG_ VCSEC_rightRawRSSI0 m0 : 32|8@1- (1,0) [0|0] "" Vector__XXX
 SG_ VCSEC_centerRSSI0Channel m1 : 24|6@1+ (1,0) [0|0] "" Vector__XXX
 SG_ VCSEC_frontLeftRSSI0Channel m5 : 24|6@1+ (1,0) [0|0] "" Vector__XXX
 SG_ VCSEC_frontRSSI0Channel m4 : 24|6@1+ (1,0) [0|0] "" Vector__XXX
 SG_ VCSEC_leftRSSI0Channel m0 : 24|6@1+ (1,0) [0|0] "" Vector__XXX
 SG_ VCSEC_rearLeftRSSI0Channel m2 : 24|6@1+ (1,0) [0|0] "" Vector__XXX
 SG_ VCSEC_secondaryCenterRSSI0Channe m3 : 24|6@1+ (1,0) [0|0] "" Vector__XXX
 SG_ VCSEC_centerReverseRawRSSI0 m1 : 16|8@1- (1,0) [0|0] "" Vector__XXX
 SG_ VCSEC_frontLeftReverseRawRSSI0 m5 : 16|8@1- (1,0) [0|0] "" Vector__XXX
 SG_ VCSEC_frontReverseRawRSSI0 m4 : 16|8@1- (1,0) [0|0] "" Vector__XXX
 SG_ VCSEC_leftReverseRawRSSI0 m0 : 16|8@1- (1,0) [0|0] "" Vector__XXX
 SG_ VCSEC_rearLeftReverseRawRSSI0 m2 : 16|8@1- (1,0) [0|0] "" Vector__XXX
 SG_ VCSEC_secondaryReverseRawRSSI0 m3 : 16|8@1- (1,0) [0|0] "" Vector__XXX
 SG_ VCSEC_centerRawRSSI0 m1 : 8|8@1- (1,0) [0|0] "" Vector__XXX
 SG_ VCSEC_frontLeftRawRSSI0 m5 : 8|8@1- (1,0) [0|0] "" Vector__XXX
 SG_ VCSEC_frontRawRSSI0 m4 : 8|8@1- (1,0) [0|0] "" Vector__XXX
 SG_ VCSEC_leftRawRSSI0 m0 : 8|8@1- (1,0) [0|0] "" Vector__XXX
 SG_ VCSEC_rearLeftRawRSSI0 m2 : 8|8@1- (1,0) [0|0] "" Vector__XXX
 SG_ VCSEC_secondaryCenterRawRSSI0 m3 : 8|8@1- (1,0) [0|0] "" Vector__XXX
 SG_ VCSEC_rawRSSI0ChannelIndex M : 0|3@1+ (1,0) [0|0] "" Vector__XXX

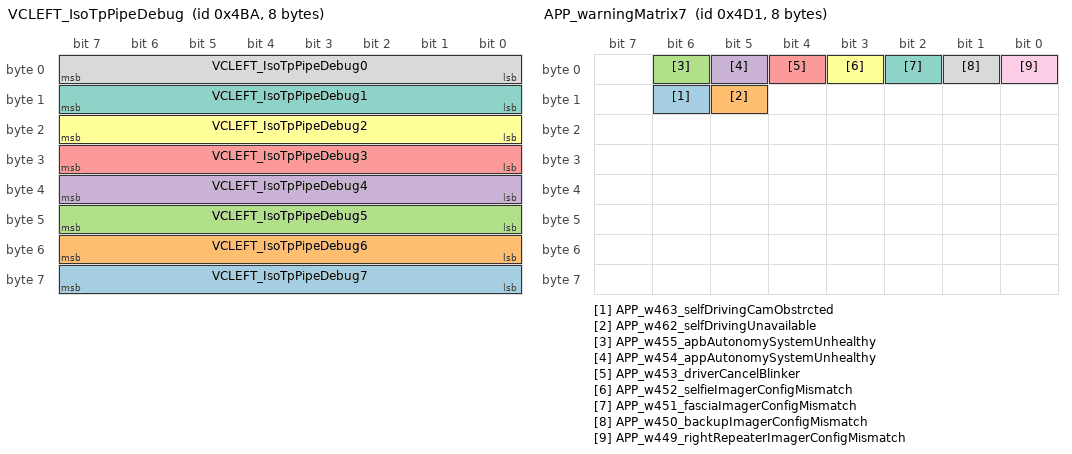
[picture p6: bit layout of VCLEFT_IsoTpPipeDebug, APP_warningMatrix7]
BO_ 1210 VCLEFT_IsoTpPipeDebug: 8 Vector__XXX
 SG_ VCLEFT_IsoTpPipeDebug7 : 56|8@1+ (1,0) [0|0] "" Vector__XXX
 SG_ VCLEFT_IsoTpPipeDebug6 : 48|8@1+ (1,0) [0|0] "" Vector__XXX
 SG_ VCLEFT_IsoTpPipeDebug5 : 40|8@1+ (1,0) [0|0] "" Vector__XXX
 SG_ VCLEFT_IsoTpPipeDebug4 : 32|8@1+ (1,0) [0|0] "" Vector__XXX
 SG_ VCLEFT_IsoTpPipeDebug3 : 24|8@1+ (1,0) [0|0] "" Vector__XXX
 SG_ VCLEFT_IsoTpPipeDebug2 : 16|8@1+ (1,0) [0|0] "" Vector__XXX
 SG_ VCLEFT_IsoTpPipeDebug1 : 8|8@1+ (1,0) [0|0] "" Vector__XXX
 SG_ VCLEFT_IsoTpPipeDebug0 : 0|8@1+ (1,0) [0|0] "" Vector__XXX

BO_ 1214 VCSEC_rawRSSI1: 8 Vector__XXX
 SG_ VCSEC_frontRightRSSI1Channel m5 : 48|6@1+ (1,0) [0|0] "" Vector__XXX
 SG_ VCSEC_nfcRSSI1Channel m3 : 48|6@1+ (1,0) [0|0] "" Vector__XXX
 SG_ VCSEC_rearRSSI1Channel m1 : 48|6@1+ (1,0) [0|0] "" Vector__XXX
 SG_ VCSEC_rearRightRSSI1Channel m2 : 48|6@1+ (1,0) [0|0] "" Vector__XXX
 SG_ VCSEC_rightRSSI1Channel m0 : 48|6@1+ (1,0) [0|0] "" Vector__XXX
 SG_ VCSEC_frontRightReverseRawRSSI1 m5 : 40|8@1- (1,0) [0|0] "" Vector__XXX
 SG_ VCSEC_nfcReverseRawRSSI1 m3 : 40|8@1- (1,0) [0|0] "" Vector__XXX
 SG_ VCSEC_rearReverseRawRSSI1 m1 : 40|8@1- (1,0) [0|0] "" Vector__XXX
 SG_ VCSEC_rearRightReverseRawRSSI1 m2 : 40|8@1- (1,0) [0|0] "" Vector__XXX
 SG_ VCSEC_rightReverseRawRSSI1 m0 : 40|8@1- (1,0) [0|0] "" Vector__XXX
 SG_ VCSEC_frontRightRawRSSI1 m5 : 32|8@1- (1,0) [0|0] "" Vector__XXX
 SG_ VCSEC_nfcRawRSSI1 m3 : 32|8@1- (1,0) [0|0] "" Vector__XXX
 SG_ VCSEC_rearRawRSSI1 m1 : 32|8@1- (1,0) [0|0] "" Vector__XXX
 SG_ VCSEC_rearRightRawRSSI1 m2 : 32|8@1- (1,0) [0|0] "" Vector__XXX
 SG_ VCSEC_rightRawRSSI1 m0 : 32|8@1- (1,0) [0|0] "" Vector__XXX
 SG_ VCSEC_centerRSSI1Channel m1 : 24|6@1+ (1,0) [0|0] "" Vector__XXX
 SG_ VCSEC_frontLeftRSSI1Channel m5 : 24|6@1+ (1,0) [0|0] "" Vector__XXX
 SG_ VCSEC_frontRSSI1Channel m4 : 24|6@1+ (1,0) [0|0] "" Vector__XXX
 SG_ VCSEC_leftRSSI1Channel m0 : 24|6@1+ (1,0) [0|0] "" Vector__XXX
 SG_ VCSEC_rearLeftRSSI1Channel m2 : 24|6@1+ (1,0) [0|0] "" Vector__XXX
 SG_ VCSEC_secondaryCenterRSSI1Channe m3 : 24|6@1+ (1,0) [0|0] "" Vector__XXX
 SG_ VCSEC_centerReverseRawRSSI1 m1 : 16|8@1- (1,0) [0|0] "" Vector__XXX
 SG_ VCSEC_frontLeftReverseRawRSSI1 m5 : 16|8@1- (1,0) [0|0] "" Vector__XXX
 SG_ VCSEC_frontReverseRawRSSI1 m4 : 16|8@1- (1,0) [0|0] "" Vector__XXX
 SG_ VCSEC_leftReverseRawRSSI1 m0 : 16|8@1- (1,0) [0|0] "" Vector__XXX
 SG_ VCSEC_rearLeftReverseRawRSSI1 m2 : 16|8@1- (1,0) [0|0] "" Vector__XXX
 SG_ VCSEC_secondaryReverseRawRSSI1 m3 : 16|8@1- (1,0) [0|0] "" Vector__XXX
 SG_ VCSEC_centerRawRSSI1 m1 : 8|8@1- (1,0) [0|0] "" Vector__XXX
 SG_ VCSEC_frontLeftRawRSSI1 m5 : 8|8@1- (1,0) [0|0] "" Vector__XXX
 SG_ VCSEC_frontRawRSSI1 m4 : 8|8@1- (1,0) [0|0] "" Vector__XXX
 SG_ VCSEC_leftRawRSSI1 m0 : 8|8@1- (1,0) [0|0] "" Vector__XXX
 SG_ VCSEC_rearLeftRawRSSI1 m2 : 8|8@1- (1,0) [0|0] "" Vector__XXX
 SG_ VCSEC_secondaryCenterRawRSSI1 m3 : 8|8@1- (1,0) [0|0] "" Vector__XXX
 SG_ VCSEC_rawRSSI1ChannelIndex M : 0|3@1+ (1,0) [0|0] "" Vector__XXX

BO_ 1215 VCSEC_rawRSSI2: 8 Vector__XXX
 SG_ VCSEC_frontRightRSSI2Channel m5 : 48|6@1+ (1,0) [0|0] "" Vector__XXX
 SG_ VCSEC_nfcRSSI2Channel m3 : 48|6@1+ (1,0) [0|0] "" Vector__XXX
 SG_ VCSEC_rearRSSI2Channel m1 : 48|6@1+ (1,0) [0|0] "" Vector__XXX
 SG_ VCSEC_rearRightRSSI2Channel m2 : 48|6@1+ (1,0) [0|0] "" Vector__XXX
 SG_ VCSEC_rightRSSI2Channel m0 : 48|6@1+ (1,0) [0|0] "" Vector__XXX
 SG_ VCSEC_frontRightReverseRawRSSI2 m5 : 40|8@1- (1,0) [0|0] "" Vector__XXX
 SG_ VCSEC_nfcReverseRawRSSI2 m3 : 40|8@1- (1,0) [0|0] "" Vector__XXX
 SG_ VCSEC_rearReverseRawRSSI2 m1 : 40|8@1- (1,0) [0|0] "" Vector__XXX
 SG_ VCSEC_rearRightReverseRawRSSI2 m2 : 40|8@1- (1,0) [0|0] "" Vector__XXX
 SG_ VCSEC_rightReverseRawRSSI2 m0 : 40|8@1- (1,0) [0|0] "" Vector__XXX
 SG_ VCSEC_frontRightRawRSSI2 m5 : 32|8@1- (1,0) [0|0] "" Vector__XXX
 SG_ VCSEC_nfcRawRSSI2 m3 : 32|8@1- (1,0) [0|0] "" Vector__XXX
 SG_ VCSEC_rearRawRSSI2 m1 : 32|8@1- (1,0) [0|0] "" Vector__XXX
 SG_ VCSEC_rearRightRawRSSI2 m2 : 32|8@1- (1,0) [0|0] "" Vector__XXX
 SG_ VCSEC_rightRawRSSI2 m0 : 32|8@1- (1,0) [0|0] "" Vector__XXX
 SG_ VCSEC_centerRSSI2Channel m1 : 24|6@1+ (1,0) [0|0] "" Vector__XXX
 SG_ VCSEC_frontLeftRSSI2Channel m5 : 24|6@1+ (1,0) [0|0] "" Vector__XXX
 SG_ VCSEC_frontRSSI2Channel m4 : 24|6@1+ (1,0) [0|0] "" Vector__XXX
 SG_ VCSEC_leftRSSI2Channel m0 : 24|6@1+ (1,0) [0|0] "" Vector__XXX
 SG_ VCSEC_rearLeftRSSI2Channel m2 : 24|6@1+ (1,0) [0|0] "" Vector__XXX
 SG_ VCSEC_secondaryCenterRSSI2Channe m3 : 24|6@1+ (1,0) [0|0] "" Vector__XXX
 SG_ VCSEC_centerReverseRawRSSI2 m1 : 16|8@1- (1,0) [0|0] "" Vector__XXX
 SG_ VCSEC_frontLeftReverseRawRSSI2 m5 : 16|8@1- (1,0) [0|0] "" Vector__XXX
 SG_ VCSEC_frontReverseRawRSSI2 m4 : 16|8@1- (1,0) [0|0] "" Vector__XXX
 SG_ VCSEC_leftReverseRawRSSI2 m0 : 16|8@1- (1,0) [0|0] "" Vector__XXX
 SG_ VCSEC_rearLeftReverseRawRSSI2 m2 : 16|8@1- (1,0) [0|0] "" Vector__XXX
 SG_ VCSEC_secondaryReverseRawRSSI2 m3 : 16|8@1- (1,0) [0|0] "" Vector__XXX
 SG_ VCSEC_centerRawRSSI2 m1 : 8|8@1- (1,0) [0|0] "" Vector__XXX
 SG_ VCSEC_frontLeftRawRSSI2 m5 : 8|8@1- (1,0) [0|0] "" Vector__XXX
 SG_ VCSEC_frontRawRSSI2 m4 : 8|8@1- (1,0) [0|0] "" Vector__XXX
 SG_ VCSEC_leftRawRSSI2 m0 : 8|8@1- (1,0) [0|0] "" Vector__XXX
 SG_ VCSEC_rearLeftRawRSSI2 m2 : 8|8@1- (1,0) [0|0] "" Vector__XXX
 SG_ VCSEC_secondaryCenterRawRSSI2 m3 : 8|8@1- (1,0) [0|0] "" Vector__XXX
 SG_ VCSEC_rawRSSI2ChannelIndex M : 0|3@1+ (1,0) [0|0] "" Vector__XXX

BO_ 1233 APP_warningMatrix7: 8 Vector__XXX
 SG_ APP_w463_selfDrivingCamObstrcted : 14|1@1+ (1,0) [0|0] "" Vector__XXX
 SG_ APP_w462_selfDrivingUnavailable : 13|1@1+ (1,0) [0|0] "" Vector__XXX
 SG_ APP_w455_apbAutonomySystemUnhealthy : 6|1@1+ (1,0) [0|0] "" Vector__XXX
 SG_ APP_w454_appAutonomySystemUnhealthy : 5|1@1+ (1,0) [0|0] "" Vector__XXX
 SG_ APP_w453_driverCancelBlinker : 4|1@1+ (1,0) [0|0] "" Vector__XXX
 SG_ APP_w452_selfieImagerConfigMismatch : 3|1@1+ (1,0) [0|0] "" Vector__XXX
 SG_ APP_w451_fasciaImagerConfigMismatch : 2|1@1+ (1,0) [0|0] "" Vector__XXX
 SG_ APP_w450_backupImagerConfigMismatch : 1|1@1+ (1,0) [0|0] "" Vector__XXX
 SG_ APP_w449_rightRepeaterImagerConfigMismatch : 0|1@1+ (1,0) [0|0] "" Vector__XXX

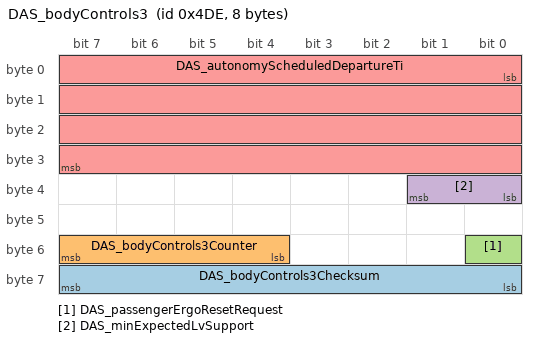
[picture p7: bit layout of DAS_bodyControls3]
BO_ 1246 DAS_bodyControls3: 8 Vector__XXX
 SG_ DAS_bodyControls3Checksum : 56|8@1+ (1,0) [0|0] "" Vector__XXX
 SG_ DAS_bodyControls3Counter : 52|4@1+ (1,0) [0|0] "" Vector__XXX
 SG_ DAS_passengerErgoResetRequest : 48|1@1+ (1,0) [0|0] "" Vector__XXX
 SG_ DAS_minExpectedLvSupport : 32|2@1+ (1,0) [0|0] "" Vector__XXX
 SG_ DAS_autonomyScheduledDepartureTi : 0|32@1+ (1,0) [0|0] "" Vector__XXX

BO_ 1249 RCM2_alertLog: 8 Vector__XXX
 SG_ RCM2_eventAccelPedalPos : 56|8@1+ (0.4,0) [0|0] "" Vector__XXX
 SG_ RCM2_eventDriverBrakeApply : 44|2@1+ (1,0) [0|0] "" Vector__XXX
 SG_ RCM2_eventVehicleSpeed : 32|12@1+ (0.08,-40) [0|0] "" Vector__XXX
 SG_ RCM2_eventFrontRightSeatbelt : 31|1@1+ (1,0) [0|0] "" Vector__XXX
 SG_ RCM2_eventFrontLeftSeatbelt : 30|1@1+ (1,0) [0|0] "" Vector__XXX
 SG_ RCM2_eventIDFsignal : 29|1@1+ (1,0) [0|0] "" Vector__XXX
 SG_ RCM2_eventDriveOrientation : 28|1@1+ (1,0) [0|0] "" Vector__XXX
 SG_ RCM2_a000_crashDetectedOffZone m0 : 27|1@1+ (1,0) [0|0] "" Vector__XXX
 SG_ RCM2_eventFactoryMode : 26|1@1+ (1,0) [0|0] "" Vector__XXX
 SG_ RCM2_eventArmStatus : 25|1@1+ (1,0) [0|0] "" Vector__XXX
 SG_ RCM2_a000_crashDetectedHVpyro m0 : 24|1@1+ (1,0) [0|0] "" Vector__XXX
 SG_ RCM2_a000_crashDetectedStage2 m0 : 23|1@1+ (1,0) [0|0] "" Vector__XXX
 SG_ RCM2_a004_crashAlgoWakeupOffZone m4 : 22|1@1+ (1,0) [0|0] "" Vector__XXX
 SG_ RCM2_a000_crashDetectedStage1 m0 : 22|1@1+ (1,0) [0|0] "" Vector__XXX
 SG_ RCM2_a004_crashAlgoWakeupPedPro m4 : 21|1@1+ (1,0) [0|0] "" Vector__XXX
 SG_ RCM2_a000_crashDetectedPreten m0 : 21|1@1+ (1,0) [0|0] "" Vector__XXX
 SG_ RCM2_a004_crashAlgoWakeupRoll m4 : 20|1@1+ (1,0) [0|0] "" Vector__XXX
 SG_ RCM2_a001_nearDeployRoll m1 : 20|1@1+ (1,0) [0|0] "" Vector__XXX
 SG_ RCM2_a000_crashDetectedRoll m0 : 20|1@1+ (1,0) [0|0] "" Vector__XXX
 SG_ RCM2_a004_crashAlgoWakeupRear m4 : 19|1@1+ (1,0) [0|0] "" Vector__XXX
 SG_ RCM2_a001_nearDeployRight m1 : 19|1@1+ (1,0) [0|0] "" Vector__XXX
 SG_ RCM2_a000_crashDetectedRight m0 : 19|1@1+ (1,0) [0|0] "" Vector__XXX
 SG_ RCM2_a004_crashAlgoWakeupSide m4 : 18|1@1+ (1,0) [0|0] "" Vector__XXX
 SG_ RCM2_a001_nearDeployLeft m1 : 18|1@1+ (1,0) [0|0] "" Vector__XXX
 SG_ RCM2_a000_crashDetectedLeft m0 : 18|1@1+ (1,0) [0|0] "" Vector__XXX
 SG_ RCM2_a017_ecuLogReason m17 : 17|6@1+ (1,0) [0|0] "" Vector__XXX
 SG_ RCM2_a004_crashAlgoWakeupFront m4 : 17|1@1+ (1,0) [0|0] "" Vector__XXX
 SG_ RCM2_a001_nearDeployRear m1 : 17|1@1+ (1,0) [0|0] "" Vector__XXX
 SG_ RCM2_a000_crashDetectedRear m0 : 17|1@1+ (1,0) [0|0] "" Vector__XXX
 SG_ RCM2_a881_comVCRIGHT3rRBuckle_s m881 : 16|1@1+ (1,0) [0|0] "" Vector__XXX
 SG_ RCM2_a880_comVCLEFT3rLBuckle_s m880 : 16|1@1+ (1,0) [0|0] "" Vector__XXX
 SG_ RCM2_a879_headAB3rdRowLConfig_s m879 : 16|1@1+ (1,0) [0|0] "" Vector__XXX
 SG_ RCM2_a878_headAB3rdRowLCrossC_s m878 : 16|1@1+ (1,0) [0|0] "" Vector__XXX
 SG_ RCM2_a877_headAB3rdRowLShort_s m877 : 16|1@1+ (1,0) [0|0] "" Vector__XXX
 SG_ RCM2_a876_headAB3rdRowLOpen_s m876 : 16|1@1+ (1,0) [0|0] "" Vector__XXX
 SG_ RCM2_a875_headAB3rdRowLSht2Bat_s m875 : 16|1@1+ (1,0) [0|0] "" Vector__XXX
 SG_ RCM2_a874_headAB3rdRowLSht2Gnd_s m874 : 16|1@1+ (1,0) [0|0] "" Vector__XXX
 SG_ RCM2_a873_headAB3rdRowRConfig_s m873 : 16|1@1+ (1,0) [0|0] "" Vector__XXX
 SG_ RCM2_a872_headAB3rdRowRCrossC_s m872 : 16|1@1+ (1,0) [0|0] "" Vector__XXX
 SG_ RCM2_a871_headAB3rdRowRShort_s m871 : 16|1@1+ (1,0) [0|0] "" Vector__XXX
 SG_ RCM2_a870_headAB3rdRowROpen_s m870 : 16|1@1+ (1,0) [0|0] "" Vector__XXX
 SG_ RCM2_a869_headAB3rdRowRSht2Bat_s m869 : 16|1@1+ (1,0) [0|0] "" Vector__XXX
 SG_ RCM2_a868_headAB3rdRowRSht2Gnd_s m868 : 16|1@1+ (1,0) [0|0] "" Vector__XXX
 SG_ RCM2_a866_comDASstatusMIA_s m866 : 16|1@1+ (1,0) [0|0] "" Vector__XXX
 SG_ RCM2_a865_comVCLVBMSstatusHighMIA_s m865 : 16|1@1+ (1,0) [0|0] "" Vector__XXX
 SG_ RCM2_a864_comGTWepochTimeMIA_s m864 : 16|1@1+ (1,0) [0|0] "" Vector__XXX
 SG_ RCM2_a863_comVCFRONTalertMatrixMIA_s m863 : 16|1@1+ (1,0) [0|0] "" Vector__XXX
 SG_ RCM2_a862_comPCSalertMatrixMIA_s m862 : 16|1@1+ (1,0) [0|0] "" Vector__XXX
 SG_ RCM2_a861_typeApprovalStringNotLearned_s m861 : 16|1@1+ (1,0) [0|0] "" Vector__XXX
 SG_ RCM2_a860_comVCxLVPowerStateCntr_s m860 : 16|1@1+ (1,0) [0|0] "" Vector__XXX
 SG_ RCM2_a859_comVCxLVPowerStateChkSm_s m859 : 16|1@1+ (1,0) [0|0] "" Vector__XXX
 SG_ RCM2_a858_comVCxLVPowerStateMIA_s m858 : 16|1@1+ (1,0) [0|0] "" Vector__XXX
 SG_ RCM2_a857_comVCLEFT2rCBuckle_s m857 : 16|1@1+ (1,0) [0|0] "" Vector__XXX
 SG_ RCM2_a854_ConfigParametersNotLearned_s m854 : 16|1@1+ (1,0) [0|0] "" Vector__XXX
 SG_ RCM2_a853_ConfigParametersInconsistent_s m853 : 16|1@1+ (1,0) [0|0] "" Vector__XXX
 SG_ RCM2_a852_autarkyEvent_s m852 : 16|1@1+ (1,0) [0|0] "" Vector__XXX
 SG_ RCM2_a851_internalFaultTemp_s m851 : 16|1@1+ (1,0) [0|0] "" Vector__XXX
 SG_ RCM2_a850_comVCFRONTlightingMIA_s m850 : 16|1@1+ (1,0) [0|0] "" Vector__XXX
 SG_ RCM2_a849_comIBSTparty1MIA_s m849 : 16|1@1+ (1,0) [0|0] "" Vector__XXX
 SG_ RCM2_a848_comDIlocStatMIA_s m848 : 16|1@1+ (1,0) [0|0] "" Vector__XXX
 SG_ RCM2_a847_comDASctrlMIA_s m847 : 16|1@1+ (1,0) [0|0] "" Vector__XXX
 SG_ RCM2_a846_comSCCMstrAnglSnsMIA_s m846 : 16|1@1+ (1,0) [0|0] "" Vector__XXX
 SG_ RCM2_a845_comUIchassisControlMIA_s m845 : 16|1@1+ (1,0) [0|0] "" Vector__XXX
 SG_ RCM2_a844_preten2ndRowCConfig_s m844 : 16|1@1+ (1,0) [0|0] "" Vector__XXX
 SG_ RCM2_a843_preten2ndRowCCrssCoup_s m843 : 16|1@1+ (1,0) [0|0] "" Vector__XXX
 SG_ RCM2_a842_preten2ndRowCShort_s m842 : 16|1@1+ (1,0) [0|0] "" Vector__XXX
 SG_ RCM2_a841_preten2ndRowCOpen_s m841 : 16|1@1+ (1,0) [0|0] "" Vector__XXX
 SG_ RCM2_a840_preten2ndRowCSht2Bat_s m840 : 16|1@1+ (1,0) [0|0] "" Vector__XXX
 SG_ RCM2_a839_preten2ndRowCSht2Gnd_s m839 : 16|1@1+ (1,0) [0|0] "" Vector__XXX
 SG_ RCM2_a838_pretenShldCConfig_s m838 : 16|1@1+ (1,0) [0|0] "" Vector__XXX
 SG_ RCM2_a837_pretenShldCCrossC_s m837 : 16|1@1+ (1,0) [0|0] "" Vector__XXX
 SG_ RCM2_a836_pretenShldCShort_s m836 : 16|1@1+ (1,0) [0|0] "" Vector__XXX
 SG_ RCM2_a835_pretenShldCOpen_s m835 : 16|1@1+ (1,0) [0|0] "" Vector__XXX
 SG_ RCM2_a834_pretenShldCSht2Bat_s m834 : 16|1@1+ (1,0) [0|0] "" Vector__XXX
 SG_ RCM2_a833_pretenShldCSht2Gnd_s m833 : 16|1@1+ (1,0) [0|0] "" Vector__XXX
 SG_ RCM2_a832_upFrntPedProMRSigMon_s m832 : 16|1@1+ (1,0) [0|0] "" Vector__XXX
 SG_ RCM2_a831_upFrntPedProMRDefect_s m831 : 16|1@1+ (1,0) [0|0] "" Vector__XXX
 SG_ RCM2_a830_upFrntPedProMRConfig_s m830 : 16|1@1+ (1,0) [0|0] "" Vector__XXX
 SG_ RCM2_a829_upFrntPedProMRIntTyp_s m829 : 16|1@1+ (1,0) [0|0] "" Vector__XXX
 SG_ RCM2_a828_upFrntPedProMRCommErr_s m828 : 16|1@1+ (1,0) [0|0] "" Vector__XXX
 SG_ RCM2_a827_upFrntPedProMRCrssCoup_s m827 : 16|1@1+ (1,0) [0|0] "" Vector__XXX
 SG_ RCM2_a826_upFrntPedProMROpen_s m826 : 16|1@1+ (1,0) [0|0] "" Vector__XXX
 SG_ RCM2_a825_upFrntPedProMRSht2Bat_s m825 : 16|1@1+ (1,0) [0|0] "" Vector__XXX
 SG_ RCM2_a824_upFrntPedProMRSht2Gnd_s m824 : 16|1@1+ (1,0) [0|0] "" Vector__XXX
 SG_ RCM2_a823_upFrntPedProMLSigMon_s m823 : 16|1@1+ (1,0) [0|0] "" Vector__XXX
 SG_ RCM2_a822_upFrntPedProMLDefect_s m822 : 16|1@1+ (1,0) [0|0] "" Vector__XXX
 SG_ RCM2_a821_upFrntPedProMLConfig_s m821 : 16|1@1+ (1,0) [0|0] "" Vector__XXX
 SG_ RCM2_a820_upFrntPedProMLIntTyp_s m820 : 16|1@1+ (1,0) [0|0] "" Vector__XXX
 SG_ RCM2_a819_upFrntPedProMLCommErr_s m819 : 16|1@1+ (1,0) [0|0] "" Vector__XXX
 SG_ RCM2_a818_upFrntPedProMLCrssCoup_s m818 : 16|1@1+ (1,0) [0|0] "" Vector__XXX
 SG_ RCM2_a817_upFrntPedProMLOpen_s m817 : 16|1@1+ (1,0) [0|0] "" Vector__XXX
 SG_ RCM2_a816_upFrntPedProMLSht2Bat_s m816 : 16|1@1+ (1,0) [0|0] "" Vector__XXX
 SG_ RCM2_a815_upFrntPedProMLSht2Gnd_s m815 : 16|1@1+ (1,0) [0|0] "" Vector__XXX
 SG_ RCM2_a814_idfEnviMonitoringEvent_s m814 : 16|1@1+ (1,0) [0|0] "" Vector__XXX
 SG_ RCM2_a813_idfEnviMonitoringError_s m813 : 16|1@1+ (1,0) [0|0] "" Vector__XXX
 SG_ RCM2_a812_idfMisuseMonitoringErr_s m812 : 16|1@1+ (1,0) [0|0] "" Vector__XXX
 SG_ RCM2_a811_comAxleSpeed_s m811 : 16|1@1+ (1,0) [0|0] "" Vector__XXX
 SG_ RCM2_a810_bootUpActionFailure_s m810 : 16|1@1+ (1,0) [0|0] "" Vector__XXX
 SG_ RCM2_a809_configDriveMismatch_s m809 : 16|1@1+ (1,0) [0|0] "" Vector__XXX
 SG_ RCM2_a808_configDriveNotLearned_s m808 : 16|1@1+ (1,0) [0|0] "" Vector__XXX
 SG_ RCM2_a807_configVINmismatch_s m807 : 16|1@1+ (1,0) [0|0] "" Vector__XXX
 SG_ RCM2_a806_configVINnotLearned_s m806 : 16|1@1+ (1,0) [0|0] "" Vector__XXX
 SG_ RCM2_a805_swVersionWrong_s m805 : 16|1@1+ (1,0) [0|0] "" Vector__XXX
 SG_ RCM2_a804_configDataInconsistent_s m804 : 16|1@1+ (1,0) [0|0] "" Vector__XXX
 SG_ RCM2_a803_algoVerifySensorID_s m803 : 16|1@1+ (1,0) [0|0] "" Vector__XXX
 SG_ RCM2_a802_parameterTransferID_s m802 : 16|1@1+ (1,0) [0|0] "" Vector__XXX
 SG_ RCM2_a801_parameterLayoutID_s m801 : 16|1@1+ (1,0) [0|0] "" Vector__XXX
 SG_ RCM2_a800_crcFault_s m800 : 16|1@1+ (1,0) [0|0] "" Vector__XXX
 SG_ RCM2_a799_internalFault_s m799 : 16|1@1+ (1,0) [0|0] "" Vector__XXX
 SG_ RCM2_a750_linInternalTimeout_s m750 : 16|1@1+ (1,0) [0|0] "" Vector__XXX
 SG_ RCM2_a701_comVCSECtpmsStatusMIA_s m701 : 16|1@1+ (1,0) [0|0] "" Vector__XXX
 SG_ RCM2_a700_comVCRIGHT1rRSTPS_s m700 : 16|1@1+ (1,0) [0|0] "" Vector__XXX
 SG_ RCM2_a699_comVCRIGHTocs_s m699 : 16|1@1+ (1,0) [0|0] "" Vector__XXX
 SG_ RCM2_a698_comVCRIGHT2rRBuckle_s m698 : 16|1@1+ (1,0) [0|0] "" Vector__XXX
 SG_ RCM2_a697_comVCRIGHT1rRBuckle_s m697 : 16|1@1+ (1,0) [0|0] "" Vector__XXX
 SG_ RCM2_a696_comVCRIGHTrestCntr_s m696 : 16|1@1+ (1,0) [0|0] "" Vector__XXX
 SG_ RCM2_a695_comVCRIGHTrestChkSm_s m695 : 16|1@1+ (1,0) [0|0] "" Vector__XXX
 SG_ RCM2_a694_comVCRIGHTrestMIA_s m694 : 16|1@1+ (1,0) [0|0] "" Vector__XXX
 SG_ RCM2_a693_comVCLEFT1rLSTPS_s m693 : 16|1@1+ (1,0) [0|0] "" Vector__XXX
 SG_ RCM2_a692_comVCLEFT2rLBuckle_s m692 : 16|1@1+ (1,0) [0|0] "" Vector__XXX
 SG_ RCM2_a691_comVCLEFT1rLBuckle_s m691 : 16|1@1+ (1,0) [0|0] "" Vector__XXX
 SG_ RCM2_a690_comVCLEFTrestCntr_s m690 : 16|1@1+ (1,0) [0|0] "" Vector__XXX
 SG_ RCM2_a689_comVCLEFTrestChkSm_s m689 : 16|1@1+ (1,0) [0|0] "" Vector__XXX
 SG_ RCM2_a688_comVCLEFTrestMIA_s m688 : 16|1@1+ (1,0) [0|0] "" Vector__XXX
 SG_ RCM2_a687_comDIchassControlCntr_s m687 : 16|1@1+ (1,0) [0|0] "" Vector__XXX
 SG_ RCM2_a686_comDIchassControlChkSm_s m686 : 16|1@1+ (1,0) [0|0] "" Vector__XXX
 SG_ RCM2_a685_comDIchassControlMIA_s m685 : 16|1@1+ (1,0) [0|0] "" Vector__XXX
 SG_ RCM2_a684_comDIspeedCntr_s m684 : 16|1@1+ (1,0) [0|0] "" Vector__XXX
 SG_ RCM2_a683_comDIspeedChkSm_s m683 : 16|1@1+ (1,0) [0|0] "" Vector__XXX
 SG_ RCM2_a682_comDIspeedMIA_s m682 : 16|1@1+ (1,0) [0|0] "" Vector__XXX
 SG_ RCM2_a681_comESPwheelSpeedsCntr_s m681 : 16|1@1+ (1,0) [0|0] "" Vector__XXX
 SG_ RCM2_a680_comESPwheelSpeedsChkSm_s m680 : 16|1@1+ (1,0) [0|0] "" Vector__XXX
 SG_ RCM2_a679_comESPwheelSpeedsMIA_s m679 : 16|1@1+ (1,0) [0|0] "" Vector__XXX
 SG_ RCM2_a678_comEPAS3PsysCntr_s m678 : 16|1@1+ (1,0) [0|0] "" Vector__XXX
 SG_ RCM2_a677_comEPAS3PsysChkSm_s m677 : 16|1@1+ (1,0) [0|0] "" Vector__XXX
 SG_ RCM2_a676_comEPAS3PsysMIA_s m676 : 16|1@1+ (1,0) [0|0] "" Vector__XXX
 SG_ RCM2_a675_comUIodoMIA_s m675 : 16|1@1+ (1,0) [0|0] "" Vector__XXX
 SG_ RCM2_a674_comEPBRstatusCntr_s m674 : 16|1@1+ (1,0) [0|0] "" Vector__XXX
 SG_ RCM2_a673_comEPBRstatusChkSm_s m673 : 16|1@1+ (1,0) [0|0] "" Vector__XXX
 SG_ RCM2_a672_comEPBRstatusMIA_s m672 : 16|1@1+ (1,0) [0|0] "" Vector__XXX
 SG_ RCM2_a671_comEPBLstatusCntr_s m671 : 16|1@1+ (1,0) [0|0] "" Vector__XXX
 SG_ RCM2_a670_comEPBLstatusChkSm_s m670 : 16|1@1+ (1,0) [0|0] "" Vector__XXX
 SG_ RCM2_a669_comEPBLstatusMIA_s m669 : 16|1@1+ (1,0) [0|0] "" Vector__XXX
 SG_ RCM2_a668_comVCSEATDstps_s m668 : 16|1@1+ (1,0) [0|0] "" Vector__XXX
 SG_ RCM2_a667_comVCSEATDOccpy_s m667 : 16|1@1+ (1,0) [0|0] "" Vector__XXX
 SG_ RCM2_a666_comVCSEATDbuckle_s m666 : 16|1@1+ (1,0) [0|0] "" Vector__XXX
 SG_ RCM2_a665_comVCSEATDrestCntr_s m665 : 16|1@1+ (1,0) [0|0] "" Vector__XXX
 SG_ RCM2_a664_comVCSEATDrestChkSm_s m664 : 16|1@1+ (1,0) [0|0] "" Vector__XXX
 SG_ RCM2_a663_comVCSEATDrestMIA_s m663 : 16|1@1+ (1,0) [0|0] "" Vector__XXX
 SG_ RCM2_a662_comVCSEATPstps_s m662 : 16|1@1+ (1,0) [0|0] "" Vector__XXX
 SG_ RCM2_a661_comVCSEATPocs_s m661 : 16|1@1+ (1,0) [0|0] "" Vector__XXX
 SG_ RCM2_a660_comVCSEATPOccpy_s m660 : 16|1@1+ (1,0) [0|0] "" Vector__XXX
 SG_ RCM2_a659_comVCSEATPbuckle_s m659 : 16|1@1+ (1,0) [0|0] "" Vector__XXX
 SG_ RCM2_a658_comVCSEATPrestCntr_s m658 : 16|1@1+ (1,0) [0|0] "" Vector__XXX
 SG_ RCM2_a657_comVCSEATPrestChkSm_s m657 : 16|1@1+ (1,0) [0|0] "" Vector__XXX
 SG_ RCM2_a656_comVCSEATPrestMIA_s m656 : 16|1@1+ (1,0) [0|0] "" Vector__XXX
 SG_ RCM2_a655_comGTWESP1Cntr_s m655 : 16|1@1+ (1,0) [0|0] "" Vector__XXX
 SG_ RCM2_a654_comGTWESP1ChkSm_s m654 : 16|1@1+ (1,0) [0|0] "" Vector__XXX
 SG_ RCM2_a653_comGTWESP1MIA_s m653 : 16|1@1+ (1,0) [0|0] "" Vector__XXX
 SG_ RCM2_a652_ambientTempFaulted_s m652 : 16|1@1+ (1,0) [0|0] "" Vector__XXX
 SG_ RCM2_a651_comDIstate2Cntr_s m651 : 16|1@1+ (1,0) [0|0] "" Vector__XXX
 SG_ RCM2_a650_comDIstate2ChkSm_s m650 : 16|1@1+ (1,0) [0|0] "" Vector__XXX
 SG_ RCM2_a649_comDIstate2MIA_s m649 : 16|1@1+ (1,0) [0|0] "" Vector__XXX
 SG_ RCM2_a648_comDIstateCntr_s m648 : 16|1@1+ (1,0) [0|0] "" Vector__XXX
 SG_ RCM2_a647_comDIstateChkSm_s m647 : 16|1@1+ (1,0) [0|0] "" Vector__XXX
 SG_ RCM2_a646_comDIstateMIA_s m646 : 16|1@1+ (1,0) [0|0] "" Vector__XXX
 SG_ RCM2_a645_comDASSafetyFrntCntr_s m645 : 16|1@1+ (1,0) [0|0] "" Vector__XXX
 SG_ RCM2_a644_comDASSafetyFrntChkSm_s m644 : 16|1@1+ (1,0) [0|0] "" Vector__XXX
 SG_ RCM2_a643_comDASSafetyFrntMIA_s m643 : 16|1@1+ (1,0) [0|0] "" Vector__XXX
 SG_ RCM2_a642_comVINmessageMIA_s m642 : 16|1@1+ (1,0) [0|0] "" Vector__XXX
 SG_ RCM2_a641_comGTWCarConfigMIA_s m641 : 16|1@1+ (1,0) [0|0] "" Vector__XXX
 SG_ RCM2_a640_comTPMSStatusCMIA_s m640 : 16|1@1+ (1,0) [0|0] "" Vector__XXX
 SG_ RCM2_a639_comGTWCarStateMIA_s m639 : 16|1@1+ (1,0) [0|0] "" Vector__XXX
 SG_ RCM2_a638_comGTWodoMIA_s m638 : 16|1@1+ (1,0) [0|0] "" Vector__XXX
 SG_ RCM2_a637_ocsUnknown_s m637 : 16|1@1+ (1,0) [0|0] "" Vector__XXX
 SG_ RCM2_a636_ocsFaulted_s m636 : 16|1@1+ (1,0) [0|0] "" Vector__XXX
 SG_ RCM2_a635_comOCS1PCntr_s m635 : 16|1@1+ (1,0) [0|0] "" Vector__XXX
 SG_ RCM2_a634_comOCS1PChkSm_s m634 : 16|1@1+ (1,0) [0|0] "" Vector__XXX
 SG_ RCM2_a633_comOCS1PMIA_s m633 : 16|1@1+ (1,0) [0|0] "" Vector__XXX
 SG_ RCM2_a632_comGTWACSCntr_s m632 : 16|1@1+ (1,0) [0|0] "" Vector__XXX
 SG_ RCM2_a631_comGTWACSChkSm_s m631 : 16|1@1+ (1,0) [0|0] "" Vector__XXX
 SG_ RCM2_a630_comGTWACSMIA_s m630 : 16|1@1+ (1,0) [0|0] "" Vector__XXX
 SG_ RCM2_a629_comEPBStatusCntr_s m629 : 16|1@1+ (1,0) [0|0] "" Vector__XXX
 SG_ RCM2_a628_comEPBStatusChkSm_s m628 : 16|1@1+ (1,0) [0|0] "" Vector__XXX
 SG_ RCM2_a627_comEPBStatusMIA_s m627 : 16|1@1+ (1,0) [0|0] "" Vector__XXX
 SG_ RCM2_a626_comESPCCntr_s m626 : 16|1@1+ (1,0) [0|0] "" Vector__XXX
 SG_ RCM2_a625_comESPCChkSm_s m625 : 16|1@1+ (1,0) [0|0] "" Vector__XXX
 SG_ RCM2_a624_comESPCMIA_s m624 : 16|1@1+ (1,0) [0|0] "" Vector__XXX
 SG_ RCM2_a623_comESPBCntr_s m623 : 16|1@1+ (1,0) [0|0] "" Vector__XXX
 SG_ RCM2_a622_comESPBChkSm_s m622 : 16|1@1+ (1,0) [0|0] "" Vector__XXX
 SG_ RCM2_a621_comESPBMIA_s m621 : 16|1@1+ (1,0) [0|0] "" Vector__XXX
 SG_ RCM2_a620_comInvalidVehicleSpeed_s m620 : 16|1@1+ (1,0) [0|0] "" Vector__XXX
 SG_ RCM2_a619_comESP145Cntr_s m619 : 16|1@1+ (1,0) [0|0] "" Vector__XXX
 SG_ RCM2_a618_comESP145ChkSm_s m618 : 16|1@1+ (1,0) [0|0] "" Vector__XXX
 SG_ RCM2_a617_comESP145MIA_s m617 : 16|1@1+ (1,0) [0|0] "" Vector__XXX
 SG_ RCM2_a616_comESP135Cntr_s m616 : 16|1@1+ (1,0) [0|0] "" Vector__XXX
 SG_ RCM2_a615_comESP135ChkSm_s m615 : 16|1@1+ (1,0) [0|0] "" Vector__XXX
 SG_ RCM2_a614_comESP135MIA_s m614 : 16|1@1+ (1,0) [0|0] "" Vector__XXX
 SG_ RCM2_a613_comDItorque2Cntr_s m613 : 16|1@1+ (1,0) [0|0] "" Vector__XXX
 SG_ RCM2_a612_comDItorque2ChkSm_s m612 : 16|1@1+ (1,0) [0|0] "" Vector__XXX
 SG_ RCM2_a611_comDItorque2MIA_s m611 : 16|1@1+ (1,0) [0|0] "" Vector__XXX
 SG_ RCM2_a610_comDItorque1Cntr_s m610 : 16|1@1+ (1,0) [0|0] "" Vector__XXX
 SG_ RCM2_a609_comDItorque1ChkSm_s m609 : 16|1@1+ (1,0) [0|0] "" Vector__XXX
 SG_ RCM2_a608_comDItorque1MIA_s m608 : 16|1@1+ (1,0) [0|0] "" Vector__XXX
 SG_ RCM2_a607_comStwAngStatCntr_s m607 : 16|1@1+ (1,0) [0|0] "" Vector__XXX
 SG_ RCM2_a606_comStwAngStatChkSm_s m606 : 16|1@1+ (1,0) [0|0] "" Vector__XXX
 SG_ RCM2_a605_comStwAngStatMIA_s m605 : 16|1@1+ (1,0) [0|0] "" Vector__XXX
 SG_ RCM2_a604_comPARTYCANBusOff_s m604 : 16|1@1+ (1,0) [0|0] "" Vector__XXX
 SG_ RCM2_a603_comPARTYCANSilent_s m603 : 16|1@1+ (1,0) [0|0] "" Vector__XXX
 SG_ RCM2_a602_comChassisCANBusOff_s m602 : 16|1@1+ (1,0) [0|0] "" Vector__XXX
 SG_ RCM2_a601_comChassisCANSilent_s m601 : 16|1@1+ (1,0) [0|0] "" Vector__XXX
 SG_ RCM2_a600_comCANinternalTimeout_s m600 : 16|1@1+ (1,0) [0|0] "" Vector__XXX
 SG_ RCM2_a598_driveOrientationConfig_s m598 : 16|1@1+ (1,0) [0|0] "" Vector__XXX
 SG_ RCM2_a597_driveOrientationCrssCoup_s m597 : 16|1@1+ (1,0) [0|0] "" Vector__XXX
 SG_ RCM2_a596_driveOrientationUndefined_s m596 : 16|1@1+ (1,0) [0|0] "" Vector__XXX
 SG_ RCM2_a595_driveOrientationOpen_s m595 : 16|1@1+ (1,0) [0|0] "" Vector__XXX
 SG_ RCM2_a594_driveOrientationSht2Bat_s m594 : 16|1@1+ (1,0) [0|0] "" Vector__XXX
 SG_ RCM2_a593_driveOrientationSht2Gnd_s m593 : 16|1@1+ (1,0) [0|0] "" Vector__XXX
 SG_ RCM2_a592_sbrRearNetworkConfig_s m592 : 16|1@1+ (1,0) [0|0] "" Vector__XXX
 SG_ RCM2_a591_sbrRearNetworkCrssCoup_s m591 : 16|1@1+ (1,0) [0|0] "" Vector__XXX
 SG_ RCM2_a590_sbrRearNetworkUndefined_s m590 : 16|1@1+ (1,0) [0|0] "" Vector__XXX
 SG_ RCM2_a589_sbrRearNetworkOpen_s m589 : 16|1@1+ (1,0) [0|0] "" Vector__XXX
 SG_ RCM2_a588_sbrRearNetworkSht2Bat_s m588 : 16|1@1+ (1,0) [0|0] "" Vector__XXX
 SG_ RCM2_a587_sbrRearNetworkSht2Gnd_s m587 : 16|1@1+ (1,0) [0|0] "" Vector__XXX
 SG_ RCM2_a573_occPROSConfig_s m573 : 16|1@1+ (1,0) [0|0] "" Vector__XXX
 SG_ RCM2_a572_occPROSCrssCoup_s m572 : 16|1@1+ (1,0) [0|0] "" Vector__XXX
 SG_ RCM2_a571_occPROSUndef_s m571 : 16|1@1+ (1,0) [0|0] "" Vector__XXX
 SG_ RCM2_a570_occPROSOpen_s m570 : 16|1@1+ (1,0) [0|0] "" Vector__XXX
 SG_ RCM2_a569_occPROSSht2Bat_s m569 : 16|1@1+ (1,0) [0|0] "" Vector__XXX
 SG_ RCM2_a568_occPROSSht2Gnd_s m568 : 16|1@1+ (1,0) [0|0] "" Vector__XXX
 SG_ RCM2_a567_seaTrkPosLeftConfig_s m567 : 16|1@1+ (1,0) [0|0] "" Vector__XXX
 SG_ RCM2_a566_seaTrkPosLeftCrssCoup_s m566 : 16|1@1+ (1,0) [0|0] "" Vector__XXX
 SG_ RCM2_a565_seaTrkPosLeftUndefined_s m565 : 16|1@1+ (1,0) [0|0] "" Vector__XXX
 SG_ RCM2_a564_seaTrkPosLeftOpen_s m564 : 16|1@1+ (1,0) [0|0] "" Vector__XXX
 SG_ RCM2_a563_seaTrkPosLeftShtBat_s m563 : 16|1@1+ (1,0) [0|0] "" Vector__XXX
 SG_ RCM2_a562_seaTrkPosLeftSht2Gnd_s m562 : 16|1@1+ (1,0) [0|0] "" Vector__XXX
 SG_ RCM2_a561_bucklHallRightConfig_s m561 : 16|1@1+ (1,0) [0|0] "" Vector__XXX
 SG_ RCM2_a560_bucklHallRightCrssCoup_s m560 : 16|1@1+ (1,0) [0|0] "" Vector__XXX
 SG_ RCM2_a559_bucklHallRightUndef_s m559 : 16|1@1+ (1,0) [0|0] "" Vector__XXX
 SG_ RCM2_a558_bucklHallRightOpen_s m558 : 16|1@1+ (1,0) [0|0] "" Vector__XXX
 SG_ RCM2_a557_bucklHallRightSht2Bat_s m557 : 16|1@1+ (1,0) [0|0] "" Vector__XXX
 SG_ RCM2_a556_bucklHallRightSht2Gnd_s m556 : 16|1@1+ (1,0) [0|0] "" Vector__XXX
 SG_ RCM2_a555_bucklHallLeftConfig_s m555 : 16|1@1+ (1,0) [0|0] "" Vector__XXX
 SG_ RCM2_a554_bucklHallLeftCrssCoup_s m554 : 16|1@1+ (1,0) [0|0] "" Vector__XXX
 SG_ RCM2_a553_bucklHallLeftUndef_s m553 : 16|1@1+ (1,0) [0|0] "" Vector__XXX
 SG_ RCM2_a552_bucklHallLeftOpen_s m552 : 16|1@1+ (1,0) [0|0] "" Vector__XXX
 SG_ RCM2_a551_bucklHallLeftSht2Bat_s m551 : 16|1@1+ (1,0) [0|0] "" Vector__XXX
 SG_ RCM2_a550_bucklHallLeftSht2Gnd_s m550 : 16|1@1+ (1,0) [0|0] "" Vector__XXX
 SG_ RCM2_a535_upFrntSnsrCSigMon_s m535 : 16|1@1+ (1,0) [0|0] "" Vector__XXX
 SG_ RCM2_a534_upFrntSnsrCDefect_s m534 : 16|1@1+ (1,0) [0|0] "" Vector__XXX
 SG_ RCM2_a533_upFrntSnsrCConfig_s m533 : 16|1@1+ (1,0) [0|0] "" Vector__XXX
 SG_ RCM2_a532_upFrntSnsrCInitTyp_s m532 : 16|1@1+ (1,0) [0|0] "" Vector__XXX
 SG_ RCM2_a531_upFrntSnsrCCommErr_s m531 : 16|1@1+ (1,0) [0|0] "" Vector__XXX
 SG_ RCM2_a530_upFrntSnsrCCrssCoup_s m530 : 16|1@1+ (1,0) [0|0] "" Vector__XXX
 SG_ RCM2_a529_upFrntSnsrCOpen_s m529 : 16|1@1+ (1,0) [0|0] "" Vector__XXX
 SG_ RCM2_a528_upFrntSnsrCSht2Bat_s m528 : 16|1@1+ (1,0) [0|0] "" Vector__XXX
 SG_ RCM2_a527_upFrntSnsrCSht2Gnd_s m527 : 16|1@1+ (1,0) [0|0] "" Vector__XXX
 SG_ RCM2_a526_sideAccelDPilRSigMon_s m526 : 16|1@1+ (1,0) [0|0] "" Vector__XXX
 SG_ RCM2_a525_sideAccelDPilRDefect_s m525 : 16|1@1+ (1,0) [0|0] "" Vector__XXX
 SG_ RCM2_a524_sideAccelDPilRConfig_s m524 : 16|1@1+ (1,0) [0|0] "" Vector__XXX
 SG_ RCM2_a523_sideAccelDPilRInitTyp_s m523 : 16|1@1+ (1,0) [0|0] "" Vector__XXX
 SG_ RCM2_a522_sideAccelDPilRCommErr_s m522 : 16|1@1+ (1,0) [0|0] "" Vector__XXX
 SG_ RCM2_a521_sideAccelDPilRCrssCoup_s m521 : 16|1@1+ (1,0) [0|0] "" Vector__XXX
 SG_ RCM2_a520_sideAccelDPilROpen_s m520 : 16|1@1+ (1,0) [0|0] "" Vector__XXX
 SG_ RCM2_a519_sideAccelDPilRSht2Bat_s m519 : 16|1@1+ (1,0) [0|0] "" Vector__XXX
 SG_ RCM2_a518_sideAccelDPilRSht2Gnd_s m518 : 16|1@1+ (1,0) [0|0] "" Vector__XXX
 SG_ RCM2_a517_sideAccelDPilLSigMon_s m517 : 16|1@1+ (1,0) [0|0] "" Vector__XXX
 SG_ RCM2_a516_sideAccelDPilLDefect_s m516 : 16|1@1+ (1,0) [0|0] "" Vector__XXX
 SG_ RCM2_a515_sideAccelDPilLConfig_s m515 : 16|1@1+ (1,0) [0|0] "" Vector__XXX
 SG_ RCM2_a514_sideAccelDPilLInitTyp_s m514 : 16|1@1+ (1,0) [0|0] "" Vector__XXX
 SG_ RCM2_a513_sideAccelDPilLCommErr_s m513 : 16|1@1+ (1,0) [0|0] "" Vector__XXX
 SG_ RCM2_a512_sideAccelDPilLCrssCoup_s m512 : 16|1@1+ (1,0) [0|0] "" Vector__XXX
 SG_ RCM2_a511_sideAccelDPilLOpen_s m511 : 16|1@1+ (1,0) [0|0] "" Vector__XXX
 SG_ RCM2_a510_sideAccelDPilLSht2Bat_s m510 : 16|1@1+ (1,0) [0|0] "" Vector__XXX
 SG_ RCM2_a509_sideAccelDPilLSht2Gnd_s m509 : 16|1@1+ (1,0) [0|0] "" Vector__XXX
 SG_ RCM2_a508_presRearRDoorSigMon_s m508 : 16|1@1+ (1,0) [0|0] "" Vector__XXX
 SG_ RCM2_a507_presRearRDoorDefect_s m507 : 16|1@1+ (1,0) [0|0] "" Vector__XXX
 SG_ RCM2_a506_presRearRDoorConfig_s m506 : 16|1@1+ (1,0) [0|0] "" Vector__XXX
 SG_ RCM2_a505_presRearRDoorInitTyp_s m505 : 16|1@1+ (1,0) [0|0] "" Vector__XXX
 SG_ RCM2_a504_presRearRDoorCommErr_s m504 : 16|1@1+ (1,0) [0|0] "" Vector__XXX
 SG_ RCM2_a503_presRearRDoorCrssCoup_s m503 : 16|1@1+ (1,0) [0|0] "" Vector__XXX
 SG_ RCM2_a502_presRearRDoorOpen_s m502 : 16|1@1+ (1,0) [0|0] "" Vector__XXX
 SG_ RCM2_a501_presRearRDoorSht2Bat_s m501 : 16|1@1+ (1,0) [0|0] "" Vector__XXX
 SG_ RCM2_a500_presRearRDoorSht2Gnd_s m500 : 16|1@1+ (1,0) [0|0] "" Vector__XXX
 SG_ RCM2_a498_presRearLDoorSigMon_s m498 : 16|1@1+ (1,0) [0|0] "" Vector__XXX
 SG_ RCM2_a497_presRearLDoorDefect_s m497 : 16|1@1+ (1,0) [0|0] "" Vector__XXX
 SG_ RCM2_a496_presRearLDoorConfig_s m496 : 16|1@1+ (1,0) [0|0] "" Vector__XXX
 SG_ RCM2_a495_presRearLDoorInitTyp_s m495 : 16|1@1+ (1,0) [0|0] "" Vector__XXX
 SG_ RCM2_a494_presRearLDoorCommErr_s m494 : 16|1@1+ (1,0) [0|0] "" Vector__XXX
 SG_ RCM2_a493_presRearLDoorCrssCoup_s m493 : 16|1@1+ (1,0) [0|0] "" Vector__XXX
 SG_ RCM2_a492_presRearLDoorOpen_s m492 : 16|1@1+ (1,0) [0|0] "" Vector__XXX
 SG_ RCM2_a491_presRearLDoorSht2Bat_s m491 : 16|1@1+ (1,0) [0|0] "" Vector__XXX
 SG_ RCM2_a490_presRearLDoorSht2Gnd_s m490 : 16|1@1+ (1,0) [0|0] "" Vector__XXX
 SG_ RCM2_a488_upFrntPedProRSigMon_s m488 : 16|1@1+ (1,0) [0|0] "" Vector__XXX
 SG_ RCM2_a487_upFrntPedProRDefect_s m487 : 16|1@1+ (1,0) [0|0] "" Vector__XXX
 SG_ RCM2_a486_upFrntPedProRConfig_s m486 : 16|1@1+ (1,0) [0|0] "" Vector__XXX
 SG_ RCM2_a485_upFrntPedProRIntTyp_s m485 : 16|1@1+ (1,0) [0|0] "" Vector__XXX
 SG_ RCM2_a484_upFrntPedProRCommErr_s m484 : 16|1@1+ (1,0) [0|0] "" Vector__XXX
 SG_ RCM2_a483_upFrntPedProRCrssCoup_s m483 : 16|1@1+ (1,0) [0|0] "" Vector__XXX
 SG_ RCM2_a482_upFrntPedProROpen_s m482 : 16|1@1+ (1,0) [0|0] "" Vector__XXX
 SG_ RCM2_a481_upFrntPedProRSht2Bat_s m481 : 16|1@1+ (1,0) [0|0] "" Vector__XXX
 SG_ RCM2_a480_upFrntPedProRSht2Gnd_s m480 : 16|1@1+ (1,0) [0|0] "" Vector__XXX
 SG_ RCM2_a478_upFrntPedProLSigMon_s m478 : 16|1@1+ (1,0) [0|0] "" Vector__XXX
 SG_ RCM2_a477_upFrntPedProLDefect_s m477 : 16|1@1+ (1,0) [0|0] "" Vector__XXX
 SG_ RCM2_a476_upFrntPedProLConfig_s m476 : 16|1@1+ (1,0) [0|0] "" Vector__XXX
 SG_ RCM2_a475_upFrntPedProLIntTyp_s m475 : 16|1@1+ (1,0) [0|0] "" Vector__XXX
 SG_ RCM2_a474_upFrntPedProLCommErr_s m474 : 16|1@1+ (1,0) [0|0] "" Vector__XXX
 SG_ RCM2_a473_upFrntPedProLCrssCoup_s m473 : 16|1@1+ (1,0) [0|0] "" Vector__XXX
 SG_ RCM2_a472_upFrntPedProLOpen_s m472 : 16|1@1+ (1,0) [0|0] "" Vector__XXX
 SG_ RCM2_a471_upFrntPedProLSht2Bat_s m471 : 16|1@1+ (1,0) [0|0] "" Vector__XXX
 SG_ RCM2_a470_upFrntPedProLSht2Gnd_s m470 : 16|1@1+ (1,0) [0|0] "" Vector__XXX
 SG_ RCM2_a469_presPedProAbsolute_s m469 : 16|1@1+ (1,0) [0|0] "" Vector__XXX
 SG_ RCM2_a468_presPedProRSigMon_s m468 : 16|1@1+ (1,0) [0|0] "" Vector__XXX
 SG_ RCM2_a467_presPedProRDefect_s m467 : 16|1@1+ (1,0) [0|0] "" Vector__XXX
 SG_ RCM2_a466_presPedProRConfig_s m466 : 16|1@1+ (1,0) [0|0] "" Vector__XXX
 SG_ RCM2_a465_presPedProRInitTyp_s m465 : 16|1@1+ (1,0) [0|0] "" Vector__XXX
 SG_ RCM2_a464_presPedProRCommErr_s m464 : 16|1@1+ (1,0) [0|0] "" Vector__XXX
 SG_ RCM2_a463_presPedProRCrssCoup_s m463 : 16|1@1+ (1,0) [0|0] "" Vector__XXX
 SG_ RCM2_a462_presPedProROpen_s m462 : 16|1@1+ (1,0) [0|0] "" Vector__XXX
 SG_ RCM2_a461_presPedProRSht2Bat_s m461 : 16|1@1+ (1,0) [0|0] "" Vector__XXX
 SG_ RCM2_a460_presPedProRSht2Gnd_s m460 : 16|1@1+ (1,0) [0|0] "" Vector__XXX
 SG_ RCM2_a458_presPedProLSigMon_s m458 : 16|1@1+ (1,0) [0|0] "" Vector__XXX
 SG_ RCM2_a457_presPedProLDefect_s m457 : 16|1@1+ (1,0) [0|0] "" Vector__XXX
 SG_ RCM2_a456_presPedProLConfig_s m456 : 16|1@1+ (1,0) [0|0] "" Vector__XXX
 SG_ RCM2_a455_presPedProLInitTyp_s m455 : 16|1@1+ (1,0) [0|0] "" Vector__XXX
 SG_ RCM2_a454_presPedProLCommErr_s m454 : 16|1@1+ (1,0) [0|0] "" Vector__XXX
 SG_ RCM2_a453_presPedProLCrssCoup_s m453 : 16|1@1+ (1,0) [0|0] "" Vector__XXX
 SG_ RCM2_a452_presPedProLOpen_s m452 : 16|1@1+ (1,0) [0|0] "" Vector__XXX
 SG_ RCM2_a451_presPedProLSht2Bat_s m451 : 16|1@1+ (1,0) [0|0] "" Vector__XXX
 SG_ RCM2_a450_presPedProLSht2Gnd_s m450 : 16|1@1+ (1,0) [0|0] "" Vector__XXX
 SG_ RCM2_a449_presDoorAbsolute2_s m449 : 16|1@1+ (1,0) [0|0] "" Vector__XXX
 SG_ RCM2_a448_presFrntRDoorSigMon_s m448 : 16|1@1+ (1,0) [0|0] "" Vector__XXX
 SG_ RCM2_a447_presFrntRDoorDefect_s m447 : 16|1@1+ (1,0) [0|0] "" Vector__XXX
 SG_ RCM2_a446_presFrntRDoorConfig_s m446 : 16|1@1+ (1,0) [0|0] "" Vector__XXX
 SG_ RCM2_a445_presFrntRDoorInitTyp_s m445 : 16|1@1+ (1,0) [0|0] "" Vector__XXX
 SG_ RCM2_a444_presFrntRDoorCommErr_s m444 : 16|1@1+ (1,0) [0|0] "" Vector__XXX
 SG_ RCM2_a443_presFrntRDoorCrssCoup_s m443 : 16|1@1+ (1,0) [0|0] "" Vector__XXX
 SG_ RCM2_a442_presFrntRDoorOpen_s m442 : 16|1@1+ (1,0) [0|0] "" Vector__XXX
 SG_ RCM2_a441_presFrntRDoorSht2Bat_s m441 : 16|1@1+ (1,0) [0|0] "" Vector__XXX
 SG_ RCM2_a440_presFrntRDoorSht2Gnd_s m440 : 16|1@1+ (1,0) [0|0] "" Vector__XXX
 SG_ RCM2_a439_presDoorAbsolute1_s m439 : 16|1@1+ (1,0) [0|0] "" Vector__XXX
 SG_ RCM2_a438_presFrntLDoorSigMon_s m438 : 16|1@1+ (1,0) [0|0] "" Vector__XXX
 SG_ RCM2_a437_presFrntLDoorDefect_s m437 : 16|1@1+ (1,0) [0|0] "" Vector__XXX
 SG_ RCM2_a436_presFrntLDoorConfig_s m436 : 16|1@1+ (1,0) [0|0] "" Vector__XXX
 SG_ RCM2_a435_presFrntLDoorInitTyp_s m435 : 16|1@1+ (1,0) [0|0] "" Vector__XXX
 SG_ RCM2_a434_presFrntLDoorCommErr_s m434 : 16|1@1+ (1,0) [0|0] "" Vector__XXX
 SG_ RCM2_a433_presFrntLDoorCrssCoup_s m433 : 16|1@1+ (1,0) [0|0] "" Vector__XXX
 SG_ RCM2_a432_presFrntLDoorOpen_s m432 : 16|1@1+ (1,0) [0|0] "" Vector__XXX
 SG_ RCM2_a431_presFrntLDoorSht2Bat_s m431 : 16|1@1+ (1,0) [0|0] "" Vector__XXX
 SG_ RCM2_a430_presFrntLDoorSht2Gnd_s m430 : 16|1@1+ (1,0) [0|0] "" Vector__XXX
 SG_ RCM2_a428_sideAccelCPilRSigMon_s m428 : 16|1@1+ (1,0) [0|0] "" Vector__XXX
 SG_ RCM2_a427_sideAccelCPilRDefect_s m427 : 16|1@1+ (1,0) [0|0] "" Vector__XXX
 SG_ RCM2_a426_sideAccelCPilRConfig_s m426 : 16|1@1+ (1,0) [0|0] "" Vector__XXX
 SG_ RCM2_a425_sideAccelCPilRInitTyp_s m425 : 16|1@1+ (1,0) [0|0] "" Vector__XXX
 SG_ RCM2_a424_sideAccelCPilRCommErr_s m424 : 16|1@1+ (1,0) [0|0] "" Vector__XXX
 SG_ RCM2_a423_sideAccelCPilRCrssCoup_s m423 : 16|1@1+ (1,0) [0|0] "" Vector__XXX
 SG_ RCM2_a422_sideAccelCPilROpen_s m422 : 16|1@1+ (1,0) [0|0] "" Vector__XXX
 SG_ RCM2_a421_sideAccelCPilRSht2Bat_s m421 : 16|1@1+ (1,0) [0|0] "" Vector__XXX
 SG_ RCM2_a420_sideAccelCPilRSht2Gnd_s m420 : 16|1@1+ (1,0) [0|0] "" Vector__XXX
 SG_ RCM2_a418_sideAccelCPilLSigMon_s m418 : 16|1@1+ (1,0) [0|0] "" Vector__XXX
 SG_ RCM2_a417_sideAccelCPilLDefect_s m417 : 16|1@1+ (1,0) [0|0] "" Vector__XXX
 SG_ RCM2_a416_sideAccelCPilLConfig_s m416 : 16|1@1+ (1,0) [0|0] "" Vector__XXX
 SG_ RCM2_a415_sideAccelCPilLInitTyp_s m415 : 16|1@1+ (1,0) [0|0] "" Vector__XXX
 SG_ RCM2_a414_sideAccelCPilLCommErr_s m414 : 16|1@1+ (1,0) [0|0] "" Vector__XXX
 SG_ RCM2_a413_sideAccelCPilLCrssCoup_s m413 : 16|1@1+ (1,0) [0|0] "" Vector__XXX
 SG_ RCM2_a412_sideAccelCPilLOpen_s m412 : 16|1@1+ (1,0) [0|0] "" Vector__XXX
 SG_ RCM2_a411_sideAccelCPilLSht2Bat_s m411 : 16|1@1+ (1,0) [0|0] "" Vector__XXX
 SG_ RCM2_a410_sideAccelCPilLSht2Gnd_s m410 : 16|1@1+ (1,0) [0|0] "" Vector__XXX
 SG_ RCM2_a408_sideAccelBPilRSigMon_s m408 : 16|1@1+ (1,0) [0|0] "" Vector__XXX
 SG_ RCM2_a407_sideAccelBPilRDefect_s m407 : 16|1@1+ (1,0) [0|0] "" Vector__XXX
 SG_ RCM2_a406_sideAccelBPilRConfig_s m406 : 16|1@1+ (1,0) [0|0] "" Vector__XXX
 SG_ RCM2_a405_sideAccelBPilRInitTyp_s m405 : 16|1@1+ (1,0) [0|0] "" Vector__XXX
 SG_ RCM2_a404_sideAccelBPilRCommErr_s m404 : 16|1@1+ (1,0) [0|0] "" Vector__XXX
 SG_ RCM2_a403_sideAccelBPilRCrssCoup_s m403 : 16|1@1+ (1,0) [0|0] "" Vector__XXX
 SG_ RCM2_a402_sideAccelBPilROpen_s m402 : 16|1@1+ (1,0) [0|0] "" Vector__XXX
 SG_ RCM2_a401_sideAccelBPilRSht2Bat_s m401 : 16|1@1+ (1,0) [0|0] "" Vector__XXX
 SG_ RCM2_a400_sideAccelBPilRSht2Gnd_s m400 : 16|1@1+ (1,0) [0|0] "" Vector__XXX
 SG_ RCM2_a398_sideAccelBPilLSigMon_s m398 : 16|1@1+ (1,0) [0|0] "" Vector__XXX
 SG_ RCM2_a397_sideAccelBPilLDefect_s m397 : 16|1@1+ (1,0) [0|0] "" Vector__XXX
 SG_ RCM2_a396_sideAccelBPilLConfig_s m396 : 16|1@1+ (1,0) [0|0] "" Vector__XXX
 SG_ RCM2_a395_sideAccelBPilLInitTyp_s m395 : 16|1@1+ (1,0) [0|0] "" Vector__XXX
 SG_ RCM2_a394_sideAccelBPilLCommErr_s m394 : 16|1@1+ (1,0) [0|0] "" Vector__XXX
 SG_ RCM2_a393_sideAccelBPilLCLosCoup_s m393 : 16|1@1+ (1,0) [0|0] "" Vector__XXX
 SG_ RCM2_a392_sideAccelBPilLOpen_s m392 : 16|1@1+ (1,0) [0|0] "" Vector__XXX
 SG_ RCM2_a391_sideAccelBPilLSht2Bat_s m391 : 16|1@1+ (1,0) [0|0] "" Vector__XXX
 SG_ RCM2_a390_sideAccelBPilLSht2Gnd_s m390 : 16|1@1+ (1,0) [0|0] "" Vector__XXX
 SG_ RCM2_a388_upFrntSnsrMidRSigMon_s m388 : 16|1@1+ (1,0) [0|0] "" Vector__XXX
 SG_ RCM2_a387_upFrntSnsrMidRDefect_s m387 : 16|1@1+ (1,0) [0|0] "" Vector__XXX
 SG_ RCM2_a386_upFrntSnsrMidRConfig_s m386 : 16|1@1+ (1,0) [0|0] "" Vector__XXX
 SG_ RCM2_a385_upFrntSnsrMidRInitTyp_s m385 : 16|1@1+ (1,0) [0|0] "" Vector__XXX
 SG_ RCM2_a384_upFrntSnsrMidRCommErr_s m384 : 16|1@1+ (1,0) [0|0] "" Vector__XXX
 SG_ RCM2_a383_upFrntSnsrMidRCrssCoup_s m383 : 16|1@1+ (1,0) [0|0] "" Vector__XXX
 SG_ RCM2_a382_upFrntSnsrMidROpen_s m382 : 16|1@1+ (1,0) [0|0] "" Vector__XXX
 SG_ RCM2_a381_upFrntSnsrMidRSht2Bat_s m381 : 16|1@1+ (1,0) [0|0] "" Vector__XXX
 SG_ RCM2_a380_upFrntSnsrMidRSht2Gnd_s m380 : 16|1@1+ (1,0) [0|0] "" Vector__XXX
 SG_ RCM2_a378_upFrntSnsrMidLSigMon_s m378 : 16|1@1+ (1,0) [0|0] "" Vector__XXX
 SG_ RCM2_a377_upFrntSnsrMidLDefect_s m377 : 16|1@1+ (1,0) [0|0] "" Vector__XXX
 SG_ RCM2_a376_upFrntSnsrMidLConfig_s m376 : 16|1@1+ (1,0) [0|0] "" Vector__XXX
 SG_ RCM2_a375_upFrntSnsrMidLInitTyp_s m375 : 16|1@1+ (1,0) [0|0] "" Vector__XXX
 SG_ RCM2_a374_upFrntSnsrMidLCommErr_s m374 : 16|1@1+ (1,0) [0|0] "" Vector__XXX
 SG_ RCM2_a373_upFrntSnsrMidLCrssCoup_s m373 : 16|1@1+ (1,0) [0|0] "" Vector__XXX
 SG_ RCM2_a372_upFrntSnsrMidLOpen_s m372 : 16|1@1+ (1,0) [0|0] "" Vector__XXX
 SG_ RCM2_a371_upFrntSnsrMidLSht2Bat_s m371 : 16|1@1+ (1,0) [0|0] "" Vector__XXX
 SG_ RCM2_a370_upFrntSnsrMidLSht2Gnd_s m370 : 16|1@1+ (1,0) [0|0] "" Vector__XXX
 SG_ RCM2_a368_upFrntSnsrRSigMon_s m368 : 16|1@1+ (1,0) [0|0] "" Vector__XXX
 SG_ RCM2_a367_upFrntSnsrRDefect_s m367 : 16|1@1+ (1,0) [0|0] "" Vector__XXX
 SG_ RCM2_a366_upFrntSnsrRConfig_s m366 : 16|1@1+ (1,0) [0|0] "" Vector__XXX
 SG_ RCM2_a365_upFrntSnsrRInitTyp_s m365 : 16|1@1+ (1,0) [0|0] "" Vector__XXX
 SG_ RCM2_a364_upFrntSnsrRCommErr_s m364 : 16|1@1+ (1,0) [0|0] "" Vector__XXX
 SG_ RCM2_a363_upFrntSnsrRCrssCoup_s m363 : 16|1@1+ (1,0) [0|0] "" Vector__XXX
 SG_ RCM2_a362_upFrntSnsrROpen_s m362 : 16|1@1+ (1,0) [0|0] "" Vector__XXX
 SG_ RCM2_a361_upFrntSnsrRSht2Bat_s m361 : 16|1@1+ (1,0) [0|0] "" Vector__XXX
 SG_ RCM2_a360_upFrntSnsrRSht2Gnd_s m360 : 16|1@1+ (1,0) [0|0] "" Vector__XXX
 SG_ RCM2_a358_upFrntSnsrLSigMon_s m358 : 16|1@1+ (1,0) [0|0] "" Vector__XXX
 SG_ RCM2_a357_upFrntSnsrLDefect_s m357 : 16|1@1+ (1,0) [0|0] "" Vector__XXX
 SG_ RCM2_a356_upFrntSnsrLConfig_s m356 : 16|1@1+ (1,0) [0|0] "" Vector__XXX
 SG_ RCM2_a355_upFrntSnsrLInitTyp_s m355 : 16|1@1+ (1,0) [0|0] "" Vector__XXX
 SG_ RCM2_a354_upFrntSnsrLCommErr_s m354 : 16|1@1+ (1,0) [0|0] "" Vector__XXX
 SG_ RCM2_a353_upFrntSnsrLCrssCoup_s m353 : 16|1@1+ (1,0) [0|0] "" Vector__XXX
 SG_ RCM2_a352_upFrntSnsrLOpen_s m352 : 16|1@1+ (1,0) [0|0] "" Vector__XXX
 SG_ RCM2_a351_upFrntSnsrLSht2Bat_s m351 : 16|1@1+ (1,0) [0|0] "" Vector__XXX
 SG_ RCM2_a350_upFrntSnsrLSht2Gnd_s m350 : 16|1@1+ (1,0) [0|0] "" Vector__XXX
 SG_ RCM2_a323_imuCalibrationNotDone_s m323 : 16|1@1+ (1,0) [0|0] "" Vector__XXX
 SG_ RCM2_a322_imuCalibrationFailed_s m322 : 16|1@1+ (1,0) [0|0] "" Vector__XXX
 SG_ RCM2_a321_imuAccZLgMonChlTemp_s m321 : 16|1@1+ (1,0) [0|0] "" Vector__XXX
 SG_ RCM2_a320_imuAccZLgMonChlPerm_s m320 : 16|1@1+ (1,0) [0|0] "" Vector__XXX
 SG_ RCM2_a319_imuAccYLgMonChlTemp_s m319 : 16|1@1+ (1,0) [0|0] "" Vector__XXX
 SG_ RCM2_a318_imuAccYLgMonChlPerm_s m318 : 16|1@1+ (1,0) [0|0] "" Vector__XXX
 SG_ RCM2_a317_imuAccXLgMonChlTemp_s m317 : 16|1@1+ (1,0) [0|0] "" Vector__XXX
 SG_ RCM2_a316_imuAccXLgMonChlPerm_s m316 : 16|1@1+ (1,0) [0|0] "" Vector__XXX
 SG_ RCM2_a315_imuRollR8ChnlMonTmpLF_s m315 : 16|1@1+ (1,0) [0|0] "" Vector__XXX
 SG_ RCM2_a314_imuRollR8SnsrPermLF_s m314 : 16|1@1+ (1,0) [0|0] "" Vector__XXX
 SG_ RCM2_a313_imuRollR8SnsrPermInit_s m313 : 16|1@1+ (1,0) [0|0] "" Vector__XXX
 SG_ RCM2_a312_imuRollR8SnsrPermBG_s m312 : 16|1@1+ (1,0) [0|0] "" Vector__XXX
 SG_ RCM2_a311_imuPitchR8ChnlMonTmpLF_s m311 : 16|1@1+ (1,0) [0|0] "" Vector__XXX
 SG_ RCM2_a310_imuPitchR8SnsrPermLF_s m310 : 16|1@1+ (1,0) [0|0] "" Vector__XXX
 SG_ RCM2_a309_imuPitchR8SnsrPermInit_s m309 : 16|1@1+ (1,0) [0|0] "" Vector__XXX
 SG_ RCM2_a308_imuPitchR8SnsrPermBG_s m308 : 16|1@1+ (1,0) [0|0] "" Vector__XXX
 SG_ RCM2_a307_imuYawR8ChnlMonTmpLF_s m307 : 16|1@1+ (1,0) [0|0] "" Vector__XXX
 SG_ RCM2_a306_imuYawR8SnsrPermLF_s m306 : 16|1@1+ (1,0) [0|0] "" Vector__XXX
 SG_ RCM2_a305_imuYawR8SnsrPermInit_s m305 : 16|1@1+ (1,0) [0|0] "" Vector__XXX
 SG_ RCM2_a304_imuYawR8SnsrPermBG_s m304 : 16|1@1+ (1,0) [0|0] "" Vector__XXX
 SG_ RCM2_a303_imuAccYHgMonChlTemp_s m303 : 16|1@1+ (1,0) [0|0] "" Vector__XXX
 SG_ RCM2_a302_imuAccYHgMonChlPerm_s m302 : 16|1@1+ (1,0) [0|0] "" Vector__XXX
 SG_ RCM2_a301_imuAccXHgMonChlTemp_s m301 : 16|1@1+ (1,0) [0|0] "" Vector__XXX
 SG_ RCM2_a300_imuAccXHgMonChlPerm_s m300 : 16|1@1+ (1,0) [0|0] "" Vector__XXX
 SG_ RCM2_a299_imuVertAOffCompNegSLDC_s m299 : 16|1@1+ (1,0) [0|0] "" Vector__XXX
 SG_ RCM2_a298_imuVertAOffCompPosSLDC_s m298 : 16|1@1+ (1,0) [0|0] "" Vector__XXX
 SG_ RCM2_a297_imuVertAOffCompNegFLDC_s m297 : 16|1@1+ (1,0) [0|0] "" Vector__XXX
 SG_ RCM2_a296_imuVertAOffCompPosFLDC_s m296 : 16|1@1+ (1,0) [0|0] "" Vector__XXX
 SG_ RCM2_a295_imuVertAOffCompNegLife_s m295 : 16|1@1+ (1,0) [0|0] "" Vector__XXX
 SG_ RCM2_a294_imuVertAOffCompPosLife_s m294 : 16|1@1+ (1,0) [0|0] "" Vector__XXX
 SG_ RCM2_a293_imuLatAcOffCompNegSLDC_s m293 : 16|1@1+ (1,0) [0|0] "" Vector__XXX
 SG_ RCM2_a292_imuLatAcOffCompPosSLDC_s m292 : 16|1@1+ (1,0) [0|0] "" Vector__XXX
 SG_ RCM2_a291_imuLatAcOffCompNegFLDC_s m291 : 16|1@1+ (1,0) [0|0] "" Vector__XXX
 SG_ RCM2_a290_imuLatAcOffCompPosFLDC_s m290 : 16|1@1+ (1,0) [0|0] "" Vector__XXX
 SG_ RCM2_a289_imuLatAcOffCompNegLife_s m289 : 16|1@1+ (1,0) [0|0] "" Vector__XXX
 SG_ RCM2_a288_imuLatAcOffCompPosLife_s m288 : 16|1@1+ (1,0) [0|0] "" Vector__XXX
 SG_ RCM2_a287_imuLongAOffCompNegSLDC_s m287 : 16|1@1+ (1,0) [0|0] "" Vector__XXX
 SG_ RCM2_a286_imuLongAOffCompPosSLDC_s m286 : 16|1@1+ (1,0) [0|0] "" Vector__XXX
 SG_ RCM2_a285_imuLongAOffCompNegFLDC_s m285 : 16|1@1+ (1,0) [0|0] "" Vector__XXX
 SG_ RCM2_a284_imuLongAOffCompPosFLDC_s m284 : 16|1@1+ (1,0) [0|0] "" Vector__XXX
 SG_ RCM2_a283_imuLongAOffCompNegLife_s m283 : 16|1@1+ (1,0) [0|0] "" Vector__XXX
 SG_ RCM2_a282_imuLongAOffCompPosLife_s m282 : 16|1@1+ (1,0) [0|0] "" Vector__XXX
 SG_ RCM2_a281_imuRollR8OffCompNegSLDC_s m281 : 16|1@1+ (1,0) [0|0] "" Vector__XXX
 SG_ RCM2_a280_imuRollR8OffCompPosSLDC_s m280 : 16|1@1+ (1,0) [0|0] "" Vector__XXX
 SG_ RCM2_a279_imuRollR8OffCompNegFLDC_s m279 : 16|1@1+ (1,0) [0|0] "" Vector__XXX
 SG_ RCM2_a278_imuRollR8OffCompPosFLDC_s m278 : 16|1@1+ (1,0) [0|0] "" Vector__XXX
 SG_ RCM2_a277_imuRollR8OffCompNegLife_s m277 : 16|1@1+ (1,0) [0|0] "" Vector__XXX
 SG_ RCM2_a276_imuRollR8OffCompPosLife_s m276 : 16|1@1+ (1,0) [0|0] "" Vector__XXX
 SG_ RCM2_a275_imuPtchR8OffCompNegSLDC_s m275 : 16|1@1+ (1,0) [0|0] "" Vector__XXX
 SG_ RCM2_a274_imuPtchR8OffCompPosSLDC_s m274 : 16|1@1+ (1,0) [0|0] "" Vector__XXX
 SG_ RCM2_a273_imuPtchR8OffCompNegFLDC_s m273 : 16|1@1+ (1,0) [0|0] "" Vector__XXX
 SG_ RCM2_a272_imuPtchR8OffCompPosFLDC_s m272 : 16|1@1+ (1,0) [0|0] "" Vector__XXX
 SG_ RCM2_a271_imuPtchR8OffCompNegLife_s m271 : 16|1@1+ (1,0) [0|0] "" Vector__XXX
 SG_ RCM2_a270_imuPtchR8OffCompPosLife_s m270 : 16|1@1+ (1,0) [0|0] "" Vector__XXX
 SG_ RCM2_a269_imuYawR8OffCompNegSLDC_s m269 : 16|1@1+ (1,0) [0|0] "" Vector__XXX
 SG_ RCM2_a268_imuYawR8OffCompPosSLDC_s m268 : 16|1@1+ (1,0) [0|0] "" Vector__XXX
 SG_ RCM2_a267_imuYawR8OffCompNegFLDC_s m267 : 16|1@1+ (1,0) [0|0] "" Vector__XXX
 SG_ RCM2_a266_imuYawR8OffCompPosFLDC_s m266 : 16|1@1+ (1,0) [0|0] "" Vector__XXX
 SG_ RCM2_a265_imuYawR8OffCompNegLife_s m265 : 16|1@1+ (1,0) [0|0] "" Vector__XXX
 SG_ RCM2_a264_imuYawR8OffCompPosLife_s m264 : 16|1@1+ (1,0) [0|0] "" Vector__XXX
 SG_ RCM2_a261_ens4Config_s m261 : 16|1@1+ (1,0) [0|0] "" Vector__XXX
 SG_ RCM2_a260_ens4Sht2Gnd_s m260 : 16|1@1+ (1,0) [0|0] "" Vector__XXX
 SG_ RCM2_a259_ens4Sht2Bat_s m259 : 16|1@1+ (1,0) [0|0] "" Vector__XXX
 SG_ RCM2_a258_ens3Config_s m258 : 16|1@1+ (1,0) [0|0] "" Vector__XXX
 SG_ RCM2_a257_ens3Sht2Gnd_s m257 : 16|1@1+ (1,0) [0|0] "" Vector__XXX
 SG_ RCM2_a256_ens3Sht2Bat_s m256 : 16|1@1+ (1,0) [0|0] "" Vector__XXX
 SG_ RCM2_a255_ens2Config_s m255 : 16|1@1+ (1,0) [0|0] "" Vector__XXX
 SG_ RCM2_a254_ens2Sht2Gnd_s m254 : 16|1@1+ (1,0) [0|0] "" Vector__XXX
 SG_ RCM2_a253_ens2Sht2Bat_s m253 : 16|1@1+ (1,0) [0|0] "" Vector__XXX
 SG_ RCM2_a252_ens1Config_s m252 : 16|1@1+ (1,0) [0|0] "" Vector__XXX
 SG_ RCM2_a251_ens1Sht2Gnd_s m251 : 16|1@1+ (1,0) [0|0] "" Vector__XXX
 SG_ RCM2_a250_ens1Sht2Bat_s m250 : 16|1@1+ (1,0) [0|0] "" Vector__XXX
 SG_ RCM2_a217_sideAB2ndRowRConfig_s m217 : 16|1@1+ (1,0) [0|0] "" Vector__XXX
 SG_ RCM2_a216_sideAB2ndRowRCrssCoup_s m216 : 16|1@1+ (1,0) [0|0] "" Vector__XXX
 SG_ RCM2_a215_sideAB2ndRowRShort_s m215 : 16|1@1+ (1,0) [0|0] "" Vector__XXX
 SG_ RCM2_a214_sideAB2ndRowROpen_s m214 : 16|1@1+ (1,0) [0|0] "" Vector__XXX
 SG_ RCM2_a213_sideAB2ndRowRSht2Bat_s m213 : 16|1@1+ (1,0) [0|0] "" Vector__XXX
 SG_ RCM2_a212_sideAB2ndRowRSht2Gnd_s m212 : 16|1@1+ (1,0) [0|0] "" Vector__XXX
 SG_ RCM2_a211_sideAB2ndRowLConfig_s m211 : 16|1@1+ (1,0) [0|0] "" Vector__XXX
 SG_ RCM2_a210_sideAB2ndRowLCrssCoup_s m210 : 16|1@1+ (1,0) [0|0] "" Vector__XXX
 SG_ RCM2_a209_sideAB2ndRowLShort_s m209 : 16|1@1+ (1,0) [0|0] "" Vector__XXX
 SG_ RCM2_a208_sideAB2ndRowLOpen_s m208 : 16|1@1+ (1,0) [0|0] "" Vector__XXX
 SG_ RCM2_a207_sideAB2ndRowLSht2Bat_s m207 : 16|1@1+ (1,0) [0|0] "" Vector__XXX
 SG_ RCM2_a206_sideAB2ndRowLSht2Gnd_s m206 : 16|1@1+ (1,0) [0|0] "" Vector__XXX
 SG_ RCM2_a205_driverFSABConfig_s m205 : 16|1@1+ (1,0) [0|0] "" Vector__XXX
 SG_ RCM2_a204_driverFSABCrossCoup_s m204 : 16|1@1+ (1,0) [0|0] "" Vector__XXX
 SG_ RCM2_a203_driverFSABShort_s m203 : 16|1@1+ (1,0) [0|0] "" Vector__XXX
 SG_ RCM2_a202_driverFSABOpen_s m202 : 16|1@1+ (1,0) [0|0] "" Vector__XXX
 SG_ RCM2_a201_driverFSABSht2Bat_s m201 : 16|1@1+ (1,0) [0|0] "" Vector__XXX
 SG_ RCM2_a200_driverFSABSht2Gnd_s m200 : 16|1@1+ (1,0) [0|0] "" Vector__XXX
 SG_ RCM2_a199_driverABAVConfig_s m199 : 16|1@1+ (1,0) [0|0] "" Vector__XXX
 SG_ RCM2_a198_driverABAVCrossCoup_s m198 : 16|1@1+ (1,0) [0|0] "" Vector__XXX
 SG_ RCM2_a197_driverABAVShort_s m197 : 16|1@1+ (1,0) [0|0] "" Vector__XXX
 SG_ RCM2_a196_driverABAVOpen_s m196 : 16|1@1+ (1,0) [0|0] "" Vector__XXX
 SG_ RCM2_a195_driverABAVSht2Bat_s m195 : 16|1@1+ (1,0) [0|0] "" Vector__XXX
 SG_ RCM2_a194_driverABAVSht2Gnd_s m194 : 16|1@1+ (1,0) [0|0] "" Vector__XXX
 SG_ RCM2_a193_hoodActuatorLConfig_s m193 : 16|1@1+ (1,0) [0|0] "" Vector__XXX
 SG_ RCM2_a192_hoodActuatorLCrssCoup_s m192 : 16|1@1+ (1,0) [0|0] "" Vector__XXX
 SG_ RCM2_a191_hoodActuatorLShort_s m191 : 16|1@1+ (1,0) [0|0] "" Vector__XXX
 SG_ RCM2_a190_hoodActuatorLOpen_s m190 : 16|1@1+ (1,0) [0|0] "" Vector__XXX
 SG_ RCM2_a189_hoodActuatorLSht2Bat_s m189 : 16|1@1+ (1,0) [0|0] "" Vector__XXX
 SG_ RCM2_a188_hoodActuatorLSht2Gnd_s m188 : 16|1@1+ (1,0) [0|0] "" Vector__XXX
 SG_ RCM2_a187_hoodActuatorRConfig_s m187 : 16|1@1+ (1,0) [0|0] "" Vector__XXX
 SG_ RCM2_a186_hoodActuatorRCrssCoup_s m186 : 16|1@1+ (1,0) [0|0] "" Vector__XXX
 SG_ RCM2_a185_hoodActuatorRShort_s m185 : 16|1@1+ (1,0) [0|0] "" Vector__XXX
 SG_ RCM2_a184_hoodActuatorROpen_s m184 : 16|1@1+ (1,0) [0|0] "" Vector__XXX
 SG_ RCM2_a183_hoodActuatorRSht2Bat_s m183 : 16|1@1+ (1,0) [0|0] "" Vector__XXX
 SG_ RCM2_a182_hoodActuatorRSht2Gnd_s m182 : 16|1@1+ (1,0) [0|0] "" Vector__XXX
 SG_ RCM2_a181_curAB2ndRowRConfig_s m181 : 16|1@1+ (1,0) [0|0] "" Vector__XXX
 SG_ RCM2_a180_curAB2ndRowRCrssCoup_s m180 : 16|1@1+ (1,0) [0|0] "" Vector__XXX
 SG_ RCM2_a179_curAB2ndRowRShort_s m179 : 16|1@1+ (1,0) [0|0] "" Vector__XXX
 SG_ RCM2_a178_curAB2ndRowROpen_s m178 : 16|1@1+ (1,0) [0|0] "" Vector__XXX
 SG_ RCM2_a177_curAB2ndRowRSht2Bat_s m177 : 16|1@1+ (1,0) [0|0] "" Vector__XXX
 SG_ RCM2_a176_curAB2ndRowRSht2Gnd_s m176 : 16|1@1+ (1,0) [0|0] "" Vector__XXX
 SG_ RCM2_a175_curAB2ndRowLConfig_s m175 : 16|1@1+ (1,0) [0|0] "" Vector__XXX
 SG_ RCM2_a174_curAB2ndRowLCrssCoup_s m174 : 16|1@1+ (1,0) [0|0] "" Vector__XXX
 SG_ RCM2_a173_curAB2ndRowLShort_s m173 : 16|1@1+ (1,0) [0|0] "" Vector__XXX
 SG_ RCM2_a172_curAB2ndRowLOpen_s m172 : 16|1@1+ (1,0) [0|0] "" Vector__XXX
 SG_ RCM2_a171_curAB2ndRowLSht2Bat_s m171 : 16|1@1+ (1,0) [0|0] "" Vector__XXX
 SG_ RCM2_a170_curAB2ndRowLSht2Gnd_s m170 : 16|1@1+ (1,0) [0|0] "" Vector__XXX
 SG_ RCM2_a169_preten2ndRowRCgf_s m169 : 16|1@1+ (1,0) [0|0] "" Vector__XXX
 SG_ RCM2_a168_preten2ndRowRCrssCoup_s m168 : 16|1@1+ (1,0) [0|0] "" Vector__XXX
 SG_ RCM2_a167_preten2ndRowRShort_s m167 : 16|1@1+ (1,0) [0|0] "" Vector__XXX
 SG_ RCM2_a166_preten2ndRowROpen_s m166 : 16|1@1+ (1,0) [0|0] "" Vector__XXX
 SG_ RCM2_a165_preten2ndRowRSht2Bat_s m165 : 16|1@1+ (1,0) [0|0] "" Vector__XXX
 SG_ RCM2_a164_preten2ndRowRSht2Gnd_s m164 : 16|1@1+ (1,0) [0|0] "" Vector__XXX
 SG_ RCM2_a163_preten2ndRowLCgf_s m163 : 16|1@1+ (1,0) [0|0] "" Vector__XXX
 SG_ RCM2_a162_preten2ndRowLCrssCoup_s m162 : 16|1@1+ (1,0) [0|0] "" Vector__XXX
 SG_ RCM2_a161_preten2ndRowLShort_s m161 : 16|1@1+ (1,0) [0|0] "" Vector__XXX
 SG_ RCM2_a160_preten2ndRowLOpen_s m160 : 16|1@1+ (1,0) [0|0] "" Vector__XXX
 SG_ RCM2_a159_preten2ndRowLSht2Bat_s m159 : 16|1@1+ (1,0) [0|0] "" Vector__XXX
 SG_ RCM2_a158_preten2ndRowLSht2Gnd_s m158 : 16|1@1+ (1,0) [0|0] "" Vector__XXX
 SG_ RCM2_a157_curABRightConfig_s m157 : 16|1@1+ (1,0) [0|0] "" Vector__XXX
 SG_ RCM2_a156_curABRightCrssCoup_s m156 : 16|1@1+ (1,0) [0|0] "" Vector__XXX
 SG_ RCM2_a155_curABRightShort_s m155 : 16|1@1+ (1,0) [0|0] "" Vector__XXX
 SG_ RCM2_a154_curABRightOpen_s m154 : 16|1@1+ (1,0) [0|0] "" Vector__XXX
 SG_ RCM2_a153_curABRightSht2Bat_s m153 : 16|1@1+ (1,0) [0|0] "" Vector__XXX
 SG_ RCM2_a152_curABRightSht2Gnd_s m152 : 16|1@1+ (1,0) [0|0] "" Vector__XXX
 SG_ RCM2_a151_curABLeftConfig_s m151 : 16|1@1+ (1,0) [0|0] "" Vector__XXX
 SG_ RCM2_a150_curABLeftCrssCoup_s m150 : 16|1@1+ (1,0) [0|0] "" Vector__XXX
 SG_ RCM2_a149_curABLeftShort_s m149 : 16|1@1+ (1,0) [0|0] "" Vector__XXX
 SG_ RCM2_a148_curABLeftOpen_s m148 : 16|1@1+ (1,0) [0|0] "" Vector__XXX
 SG_ RCM2_a147_curABLeftSht2Bat_s m147 : 16|1@1+ (1,0) [0|0] "" Vector__XXX
 SG_ RCM2_a146_curABLeftSht2Gnd_s m146 : 16|1@1+ (1,0) [0|0] "" Vector__XXX
 SG_ RCM2_a145_hvdPyroConfig_s m145 : 16|1@1+ (1,0) [0|0] "" Vector__XXX
 SG_ RCM2_a144_hvdPyroCrssCoup_s m144 : 16|1@1+ (1,0) [0|0] "" Vector__XXX
 SG_ RCM2_a143_hvdPyroShort_s m143 : 16|1@1+ (1,0) [0|0] "" Vector__XXX
 SG_ RCM2_a142_hvdPyroOpen_s m142 : 16|1@1+ (1,0) [0|0] "" Vector__XXX
 SG_ RCM2_a141_hvdPyroSht2Bat_s m141 : 16|1@1+ (1,0) [0|0] "" Vector__XXX
 SG_ RCM2_a140_hvdPyroSht2Gnd_s m140 : 16|1@1+ (1,0) [0|0] "" Vector__XXX
 SG_ RCM2_a139_sideAB1stRowRConfig_s m139 : 16|1@1+ (1,0) [0|0] "" Vector__XXX
 SG_ RCM2_a138_sideAB1stRowRCrssCoup_s m138 : 16|1@1+ (1,0) [0|0] "" Vector__XXX
 SG_ RCM2_a137_sideAB1stRowRShort_s m137 : 16|1@1+ (1,0) [0|0] "" Vector__XXX
 SG_ RCM2_a136_sideAB1stRowROpen_s m136 : 16|1@1+ (1,0) [0|0] "" Vector__XXX
 SG_ RCM2_a135_sideAB1stRowRSht2Bat_s m135 : 16|1@1+ (1,0) [0|0] "" Vector__XXX
 SG_ RCM2_a134_sideAB1stRowRSht2Gnd_s m134 : 16|1@1+ (1,0) [0|0] "" Vector__XXX
 SG_ RCM2_a133_sideAB1stRowLConfig_s m133 : 16|1@1+ (1,0) [0|0] "" Vector__XXX
 SG_ RCM2_a132_sideAB1stRowLCrssCoup_s m132 : 16|1@1+ (1,0) [0|0] "" Vector__XXX
 SG_ RCM2_a131_sideAB1stRowLShort_s m131 : 16|1@1+ (1,0) [0|0] "" Vector__XXX
 SG_ RCM2_a130_sideAB1stRowLOpen_s m130 : 16|1@1+ (1,0) [0|0] "" Vector__XXX
 SG_ RCM2_a129_sideAB1stRowLSht2Bat_s m129 : 16|1@1+ (1,0) [0|0] "" Vector__XXX
 SG_ RCM2_a128_sideAB1stRowLSht2Gnd_s m128 : 16|1@1+ (1,0) [0|0] "" Vector__XXX
 SG_ RCM2_a127_kneeABPassConfig_s m127 : 16|1@1+ (1,0) [0|0] "" Vector__XXX
 SG_ RCM2_a126_kneeABPassCrssCoup_s m126 : 16|1@1+ (1,0) [0|0] "" Vector__XXX
 SG_ RCM2_a125_kneeABPassShort_s m125 : 16|1@1+ (1,0) [0|0] "" Vector__XXX
 SG_ RCM2_a124_kneeABPassOpen_s m124 : 16|1@1+ (1,0) [0|0] "" Vector__XXX
 SG_ RCM2_a123_kneeABPassSht2Bat_s m123 : 16|1@1+ (1,0) [0|0] "" Vector__XXX
 SG_ RCM2_a122_kneeABPassSht2Gnd_s m122 : 16|1@1+ (1,0) [0|0] "" Vector__XXX
 SG_ RCM2_a121_kneeABDrvrConfig_s m121 : 16|1@1+ (1,0) [0|0] "" Vector__XXX
 SG_ RCM2_a120_kneeABDrvrCrssCoup_s m120 : 16|1@1+ (1,0) [0|0] "" Vector__XXX
 SG_ RCM2_a119_kneeABDrvrShort_s m119 : 16|1@1+ (1,0) [0|0] "" Vector__XXX
 SG_ RCM2_a118_kneeABDrvrOpen_s m118 : 16|1@1+ (1,0) [0|0] "" Vector__XXX
 SG_ RCM2_a117_kneeABDrvrSht2Bat_s m117 : 16|1@1+ (1,0) [0|0] "" Vector__XXX
 SG_ RCM2_a116_kneeABDrvrSht2Gnd_s m116 : 16|1@1+ (1,0) [0|0] "" Vector__XXX
 SG_ RCM2_a115_loadLimRightConfig_s m115 : 16|1@1+ (1,0) [0|0] "" Vector__XXX
 SG_ RCM2_a114_loadLimRightCrssCoup_s m114 : 16|1@1+ (1,0) [0|0] "" Vector__XXX
 SG_ RCM2_a113_loadLimRightShort_s m113 : 16|1@1+ (1,0) [0|0] "" Vector__XXX
 SG_ RCM2_a112_loadLimRightOpen_s m112 : 16|1@1+ (1,0) [0|0] "" Vector__XXX
 SG_ RCM2_a111_loadLimRightSht2Bat_s m111 : 16|1@1+ (1,0) [0|0] "" Vector__XXX
 SG_ RCM2_a110_loadLimRightSht2Gnd_s m110 : 16|1@1+ (1,0) [0|0] "" Vector__XXX
 SG_ RCM2_a109_loadLimLeftConfig_s m109 : 16|1@1+ (1,0) [0|0] "" Vector__XXX
 SG_ RCM2_a108_loadLimLeftCrssCoup_s m108 : 16|1@1+ (1,0) [0|0] "" Vector__XXX
 SG_ RCM2_a107_loadLimLeftShort_s m107 : 16|1@1+ (1,0) [0|0] "" Vector__XXX
 SG_ RCM2_a106_loadLimLeftOpen_s m106 : 16|1@1+ (1,0) [0|0] "" Vector__XXX
 SG_ RCM2_a105_loadLimLeftSht2Bat_s m105 : 16|1@1+ (1,0) [0|0] "" Vector__XXX
 SG_ RCM2_a104_loadLimLeftSht2Gnd_s m104 : 16|1@1+ (1,0) [0|0] "" Vector__XXX
 SG_ RCM2_a103_pretenLapRightConfig_s m103 : 16|1@1+ (1,0) [0|0] "" Vector__XXX
 SG_ RCM2_a102_pretenLapRightCrssCoup_s m102 : 16|1@1+ (1,0) [0|0] "" Vector__XXX
 SG_ RCM2_a101_pretenLapRightShort_s m101 : 16|1@1+ (1,0) [0|0] "" Vector__XXX
 SG_ RCM2_a100_pretenLapRightOpen_s m100 : 16|1@1+ (1,0) [0|0] "" Vector__XXX
 SG_ RCM2_a099_pretenLapRightSht2Bat_s m99 : 16|1@1+ (1,0) [0|0] "" Vector__XXX
 SG_ RCM2_a098_pretenLapRightSht2Gnd_s m98 : 16|1@1+ (1,0) [0|0] "" Vector__XXX
 SG_ RCM2_a097_pretenLapLeftConfig_s m97 : 16|1@1+ (1,0) [0|0] "" Vector__XXX
 SG_ RCM2_a096_pretenLapLeftCrssCoup_s m96 : 16|1@1+ (1,0) [0|0] "" Vector__XXX
 SG_ RCM2_a095_pretenLapLeftShort_s m95 : 16|1@1+ (1,0) [0|0] "" Vector__XXX
 SG_ RCM2_a094_pretenLapLeftOpen_s m94 : 16|1@1+ (1,0) [0|0] "" Vector__XXX
 SG_ RCM2_a093_pretenLapLeftSht2Bat_s m93 : 16|1@1+ (1,0) [0|0] "" Vector__XXX
 SG_ RCM2_a092_pretenLapLeftSht2Gnd_s m92 : 16|1@1+ (1,0) [0|0] "" Vector__XXX
 SG_ RCM2_a091_pretenShldRightConfig_s m91 : 16|1@1+ (1,0) [0|0] "" Vector__XXX
 SG_ RCM2_a090_pretenShldRightCrssCou_s m90 : 16|1@1+ (1,0) [0|0] "" Vector__XXX
 SG_ RCM2_a089_pretenShldRightShort_s m89 : 16|1@1+ (1,0) [0|0] "" Vector__XXX
 SG_ RCM2_a088_pretenShldRightOpen_s m88 : 16|1@1+ (1,0) [0|0] "" Vector__XXX
 SG_ RCM2_a087_pretenShldRightSht2Bat_s m87 : 16|1@1+ (1,0) [0|0] "" Vector__XXX
 SG_ RCM2_a086_pretenShldRightSht2Gnd_s m86 : 16|1@1+ (1,0) [0|0] "" Vector__XXX
 SG_ RCM2_a085_pretenShldLeftConfig_s m85 : 16|1@1+ (1,0) [0|0] "" Vector__XXX
 SG_ RCM2_a084_pretenShldLeftCrossC_s m84 : 16|1@1+ (1,0) [0|0] "" Vector__XXX
 SG_ RCM2_a083_pretenShldLeftShort_s m83 : 16|1@1+ (1,0) [0|0] "" Vector__XXX
 SG_ RCM2_a082_pretenShldLeftOpen_s m82 : 16|1@1+ (1,0) [0|0] "" Vector__XXX
 SG_ RCM2_a081_pretenShldLeftSht2Bat_s m81 : 16|1@1+ (1,0) [0|0] "" Vector__XXX
 SG_ RCM2_a080_pretenShldLeftSht2Gnd_s m80 : 16|1@1+ (1,0) [0|0] "" Vector__XXX
 SG_ RCM2_a079_passActiveVentConfig_s m79 : 16|1@1+ (1,0) [0|0] "" Vector__XXX
 SG_ RCM2_a078_passActiveVentCrssCoup_s m78 : 16|1@1+ (1,0) [0|0] "" Vector__XXX
 SG_ RCM2_a077_passActiveVentShort_s m77 : 16|1@1+ (1,0) [0|0] "" Vector__XXX
 SG_ RCM2_a076_passActiveVentOpen_s m76 : 16|1@1+ (1,0) [0|0] "" Vector__XXX
 SG_ RCM2_a075_passActiveVentSht2Bat_s m75 : 16|1@1+ (1,0) [0|0] "" Vector__XXX
 SG_ RCM2_a074_passActiveVentSht2Gnd_s m74 : 16|1@1+ (1,0) [0|0] "" Vector__XXX
 SG_ RCM2_a073_passABStg2Config_s m73 : 16|1@1+ (1,0) [0|0] "" Vector__XXX
 SG_ RCM2_a072_passABStg2CrssCoup_s m72 : 16|1@1+ (1,0) [0|0] "" Vector__XXX
 SG_ RCM2_a071_passABStg2Short_s m71 : 16|1@1+ (1,0) [0|0] "" Vector__XXX
 SG_ RCM2_a070_passABStg2Open_s m70 : 16|1@1+ (1,0) [0|0] "" Vector__XXX
 SG_ RCM2_a069_passABStg2Sht2Bat_s m69 : 16|1@1+ (1,0) [0|0] "" Vector__XXX
 SG_ RCM2_a068_passABStg2Sht2Gnd_s m68 : 16|1@1+ (1,0) [0|0] "" Vector__XXX
 SG_ RCM2_a067_passABStg1Config_s m67 : 16|1@1+ (1,0) [0|0] "" Vector__XXX
 SG_ RCM2_a066_passABStg1CrssCoup_s m66 : 16|1@1+ (1,0) [0|0] "" Vector__XXX
 SG_ RCM2_a065_passABStg1Short_s m65 : 16|1@1+ (1,0) [0|0] "" Vector__XXX
 SG_ RCM2_a064_passABStg1Open_s m64 : 16|1@1+ (1,0) [0|0] "" Vector__XXX
 SG_ RCM2_a063_passABStg1Sht2Bat_s m63 : 16|1@1+ (1,0) [0|0] "" Vector__XXX
 SG_ RCM2_a062_passABStg1Sht2Gnd_s m62 : 16|1@1+ (1,0) [0|0] "" Vector__XXX
 SG_ RCM2_a061_driverABStg2Config_s m61 : 16|1@1+ (1,0) [0|0] "" Vector__XXX
 SG_ RCM2_a060_driverABStg2CrssCoup_s m60 : 16|1@1+ (1,0) [0|0] "" Vector__XXX
 SG_ RCM2_a059_driverABStg2Short_s m59 : 16|1@1+ (1,0) [0|0] "" Vector__XXX
 SG_ RCM2_a058_driverABStg2Open_s m58 : 16|1@1+ (1,0) [0|0] "" Vector__XXX
 SG_ RCM2_a057_driverABStg2Sht2Bat_s m57 : 16|1@1+ (1,0) [0|0] "" Vector__XXX
 SG_ RCM2_a056_driverABStg2Sht2Gnd_s m56 : 16|1@1+ (1,0) [0|0] "" Vector__XXX
 SG_ RCM2_a055_driverABStg1Config_s m55 : 16|1@1+ (1,0) [0|0] "" Vector__XXX
 SG_ RCM2_a054_driverABStg1CrssCoup_s m54 : 16|1@1+ (1,0) [0|0] "" Vector__XXX
 SG_ RCM2_a053_driverABStg1Short_s m53 : 16|1@1+ (1,0) [0|0] "" Vector__XXX
 SG_ RCM2_a052_driverABStg1Open_s m52 : 16|1@1+ (1,0) [0|0] "" Vector__XXX
 SG_ RCM2_a051_driverABStg1Sht2Bat_s m51 : 16|1@1+ (1,0) [0|0] "" Vector__XXX
 SG_ RCM2_a050_driverABStg1Sht2Gnd_s m50 : 16|1@1+ (1,0) [0|0] "" Vector__XXX
 SG_ RCM2_a049_batteryVoltageTooLow_s m49 : 16|1@1+ (1,0) [0|0] "" Vector__XXX
 SG_ RCM2_a048_batteryVoltageTooHigh_s m48 : 16|1@1+ (1,0) [0|0] "" Vector__XXX
 SG_ RCM2_a047_batteryESRhigh_s m47 : 16|1@1+ (1,0) [0|0] "" Vector__XXX
 SG_ RCM2_a017_ecuLogAvailable_s m17 : 16|1@1+ (1,0) [0|0] "" Vector__XXX
 SG_ RCM2_a016_noDeployPedProCal_s m16 : 16|1@1+ (1,0) [0|0] "" Vector__XXX
 SG_ RCM2_a015_noDeployCrashCal_s m15 : 16|1@1+ (1,0) [0|0] "" Vector__XXX
 SG_ RCM2_a014_pedProNearDeploy_s m14 : 16|1@1+ (1,0) [0|0] "" Vector__XXX
 SG_ RCM2_a013_placeholder2_s m13 : 16|1@1+ (1,0) [0|0] "" Vector__XXX
 SG_ RCM2_a012_placeholder1_s m12 : 16|1@1+ (1,0) [0|0] "" Vector__XXX
 SG_ RCM2_a011_placeholder0_s m11 : 16|1@1+ (1,0) [0|0] "" Vector__XXX
 SG_ RCM2_a010_pedProEDRDataLocked_s m10 : 16|1@1+ (1,0) [0|0] "" Vector__XXX
 SG_ RCM2_a009_edrDataAreaLocked_s m9 : 16|1@1+ (1,0) [0|0] "" Vector__XXX
 SG_ RCM2_a008_factoryMode_s m8 : 16|1@1+ (1,0) [0|0] "" Vector__XXX
 SG_ RCM2_a007_pedProCrashDetected_s m7 : 16|1@1+ (1,0) [0|0] "" Vector__XXX
 SG_ RCM2_a006_supplierDiagEnabled_s m6 : 16|1@1+ (1,0) [0|0] "" Vector__XXX
 SG_ RCM2_a005_abuseImmunityThrshold_s m5 : 16|1@1+ (1,0) [0|0] "" Vector__XXX
 SG_ RCM2_a004_crashAlgoWakeup_s m4 : 16|1@1+ (1,0) [0|0] "" Vector__XXX
 SG_ RCM2_a003_warningIndicator_s m3 : 16|1@1+ (1,0) [0|0] "" Vector__XXX
 SG_ RCM2_a002_airbagsUnArmed_s m2 : 16|1@1+ (1,0) [0|0] "" Vector__XXX
 SG_ RCM2_a001_nearDeployFront m1 : 16|1@1+ (1,0) [0|0] "" Vector__XXX
 SG_ RCM2_a000_crashDetectedFront m0 : 16|1@1+ (1,0) [0|0] "" Vector__XXX
 SG_ RCM2_alertState : 15|1@1+ (1,0) [0|0] "" Vector__XXX
 SG_ RCM2_a000_crashDetectedPitch m0 : 14|1@1+ (1,0) [0|0] "" Vector__XXX
 SG_ RCM2_a000_crashDetectedStaticRoll m0 : 13|1@1+ (1,0) [0|0] "" Vector__XXX
 SG_ RCM2_alertID M : 0|10@1+ (1,0) [0|0] "" Vector__XXX

BO_ 1252 RCM3_alertLog: 8 Vector__XXX
 SG_ RCM3_a001_lastPCSAlertID m1 : 57|7@1+ (1,0) [0|0] "" Vector__XXX
 SG_ RCM3_a001_timeEpochms m1 : 16|41@1+ (1,0) [0|0] "" Vector__XXX
 SG_ RCM3_alertState : 15|1@1+ (1,0) [0|0] "" Vector__XXX
 SG_ RCM3_a001_lastVCFRONTAlertID m1 : 5|10@1+ (1,0) [0|0] "" Vector__XXX
 SG_ RCM3_a001_LVPowerLossEventIndex m1 : 1|4@1+ (1,0) [0|0] "" Vector__XXX
 SG_ RCM3_alertID M : 0|1@1+ (1,0) [0|0] "" Vector__XXX

BO_ 1267 UI_frontSeatRequests: 4 Vector__XXX
 SG_ UI_seatAdjustmentSource : 24|3@1+ (1,0) [0|0] "" Vector__XXX
 SG_ UI_frontRightSeatLumbarOut : 23|1@1+ (1,0) [0|0] "" Vector__XXX
 SG_ UI_frontRightSeatLumbarIn : 22|1@1+ (1,0) [0|0] "" Vector__XXX
 SG_ UI_frontLeftSeatLumbarOut : 21|1@1+ (1,0) [0|0] "" Vector__XXX
 SG_ UI_frontLeftSeatLumbarIn : 20|1@1+ (1,0) [0|0] "" Vector__XXX
 SG_ UI_frontRightSeatLumbarDown : 19|1@1+ (1,0) [0|0] "" Vector__XXX
 SG_ UI_frontRightSeatLumbarUp : 18|1@1+ (1,0) [0|0] "" Vector__XXX
 SG_ UI_frontLeftSeatLumbarDown : 17|1@1+ (1,0) [0|0] "" Vector__XXX
 SG_ UI_frontLeftSeatLumbarUp : 16|1@1+ (1,0) [0|0] "" Vector__XXX
 SG_ UI_frontLeftSeatLiftDown : 15|1@1+ (1,0) [0|0] "" Vector__XXX
 SG_ UI_frontLeftSeatLiftUp : 14|1@1+ (1,0) [0|0] "" Vector__XXX
 SG_ UI_frontRightSeatLiftDown : 13|1@1+ (1,0) [0|0] "" Vector__XXX
 SG_ UI_frontRightSeatLiftUp : 12|1@1+ (1,0) [0|0] "" Vector__XXX
 SG_ UI_frontLeftSeatTiltDown : 11|1@1+ (1,0) [0|0] "" Vector__XXX
 SG_ UI_frontLeftSeatTiltUp : 10|1@1+ (1,0) [0|0] "" Vector__XXX
 SG_ UI_frontRightSeatTiltDown : 9|1@1+ (1,0) [0|0] "" Vector__XXX
 SG_ UI_frontRightSeatTiltUp : 8|1@1+ (1,0) [0|0] "" Vector__XXX
 SG_ UI_frontLeftSeatBackrestForward : 7|1@1+ (1,0) [0|0] "" Vector__XXX
 SG_ UI_frontLeftSeatBackrestBack : 6|1@1+ (1,0) [0|0] "" Vector__XXX
 SG_ UI_frontRightSeatBackrestForward : 5|1@1+ (1,0) [0|0] "" Vector__XXX
 SG_ UI_frontRightSeatBackrestBack : 4|1@1+ (1,0) [0|0] "" Vector__XXX
 SG_ UI_frontLeftSeatTrackBack : 3|1@1+ (1,0) [0|0] "" Vector__XXX
 SG_ UI_frontLeftSeatTrackForward : 2|1@1+ (1,0) [0|0] "" Vector__XXX
 SG_ UI_frontRightSeatTrackBack : 1|1@1+ (1,0) [0|0] "" Vector__XXX
 SG_ UI_frontRightSeatTrackForward : 0|1@1+ (1,0) [0|0] "" Vector__XXX

CM_ BO_ 1083 "ESP32-DualCAN Model3_VEH. Seen on this car: 8-byte frames; fit good (bits covered 100%, mux 100%, ranges 100%).";
CM_ BO_ 1085 "ESP32-DualCAN Model3_VEH. Not seen on this car in the logs.";
VAL_ 1085 CP_acHvInletExposed_log 0 "NO_CHARGER_PRESENT" 1 "DC_CHARGER_PRESENT" 2 "AC_CHARGER_PRESENT" ;
VAL_ 1085 CP_dcHvInletExposed_log 0 "NO_CHARGER_PRESENT" 1 "DC_CHARGER_PRESENT" 2 "AC_CHARGER_PRESENT" ;
VAL_ 1085 CP_chgLimitMode_log 0 "NO_CHARGER_PRESENT" 1 "DC_CHARGER_PRESENT" 2 "AC_CHARGER_PRESENT" ;
VAL_ 1085 CP_evseChargeType_log 0 "NO_CHARGER_PRESENT" 1 "DC_CHARGER_PRESENT" 2 "AC_CHARGER_PRESENT" ;
VAL_ 1085 CP_internalMaxAcCurrentLimit_log 0 "NO_CHARGER_PRESENT" 1 "DC_CHARGER_PRESENT" 2 "AC_CHARGER_PRESENT" ;
VAL_ 1085 CP_vehiclePrechargeRequired_log 0 "NO_CHARGER_PRESENT" 1 "DC_CHARGER_PRESENT" 2 "AC_CHARGER_PRESENT" ;
VAL_ 1085 CP_vehicleIsoCheckRequired_log 0 "NO_CHARGER_PRESENT" 1 "DC_CHARGER_PRESENT" 2 "AC_CHARGER_PRESENT" ;
VAL_ 1085 CP_internalMaxDcCurrentLimit_log 0 "NO_CHARGER_PRESENT" 1 "DC_CHARGER_PRESENT" 2 "AC_CHARGER_PRESENT" ;
VAL_ 1085 CP_evseAcCurrentLimit_log 0 "NO_CHARGER_PRESENT" 1 "DC_CHARGER_PRESENT" 2 "AC_CHARGER_PRESENT" ;
VAL_ 1085 CP_v2xCapable_log 0 "NO_CHARGER_PRESENT" 1 "DC_CHARGER_PRESENT" 2 "AC_CHARGER_PRESENT" ;
VAL_ 1085 CP_evseAcControlMode_log 0 "NO_CHARGER_PRESENT" 1 "DC_CHARGER_PRESENT" 2 "AC_CHARGER_PRESENT" ;
VAL_ 1085 CP_powerTransferShutdownRequest_ 0 "NO_CHARGER_PRESENT" 1 "DC_CHARGER_PRESENT" 2 "AC_CHARGER_PRESENT" ;
VAL_ 1085 CP_powerTransferStatus_log 0 "NO_CHARGER_PRESENT" 1 "DC_CHARGER_PRESENT" 2 "AC_CHARGER_PRESENT" ;
CM_ BO_ 1086 "ESP32-DualCAN Model3_VEH. Not seen on this car in the logs.";
VAL_ 1086 TAS_dominantControl_RR_R 31 "SNA" ;
VAL_ 1086 TAS_dominantControl_RR_C 31 "SNA" ;
VAL_ 1086 TAS_dominantControl_RL_R 31 "SNA" ;
VAL_ 1086 TAS_dominantControl_RL_C 31 "SNA" ;
VAL_ 1086 TAS_dominantControl_FR_R 31 "SNA" ;
VAL_ 1086 TAS_dominantControl_FR_C 31 "SNA" ;
VAL_ 1086 TAS_dominantControl_FL_R 31 "SNA" ;
VAL_ 1086 TAS_dominantControl_FL_C 31 "SNA" ;
CM_ BO_ 1089 "ESP32-DualCAN Model3_VEH. Seen on this car: 8-byte frames; fit ok (bits covered 100%, mux 100%, ranges 100%, checksum 0%).";
VAL_ 1089 VC_pcsInterfaceMuxIndex 0 "0" 1 "1" ;
CM_ BO_ 1090 "ESP32-DualCAN Model3_VEH. Not seen on this car in the logs.";
VAL_ 1090 VCBATT_pcsInterfaceMuxIndex 0 "0" 1 "1" ;
CM_ BO_ 1091 "ESP32-DualCAN Model3_VEH. Seen on this car: 6-byte frames; fit weak (bits covered 100%, mux 100%, ranges 100%, checksum 0%).";
CM_ BO_ 1092 "ESP32-DualCAN Model3_VEH. Not seen on this car in the logs.";
VAL_ 1092 PCS2_a088_gridConfig 0 "SNA" 1 "SINGLE_PHASE" 2 "THREE_PHASE" 3 "THREE_PHASE_DELTA" ;
VAL_ 1092 PCS2_a132_currentLimit 8191 "SNA" ;
VAL_ 1092 PCS2_a125_lnbn_state 0 "STANDBY" 1 "DRIVE" 2 "SUPPORT" 3 "CHARGE" 4 "FEIM" 5 "CLEAR_FAULT" 6 "FAULT" 7 "WELD" 8 "TEST" 9 "SNA" 10 "DIAG" ;
VAL_ 1092 PCS2_a125_lntn_state 0 "STANDBY" 1 "DRIVE" 2 "SUPPORT" 3 "CHARGE" 4 "FEIM" 5 "CLEAR_FAULT" 6 "FAULT" 7 "WELD" 8 "TEST" 9 "SNA" 10 "DIAG" ;
VAL_ 1092 PCS2_a052_CP_status 0 "DISABLED" 1 "ENABLED" 2 "TEMPORARY_FAILURE" 3 "SNA" ;
VAL_ 1092 PCS2_a125_lnbp_state 0 "STANDBY" 1 "DRIVE" 2 "SUPPORT" 3 "CHARGE" 4 "FEIM" 5 "CLEAR_FAULT" 6 "FAULT" 7 "WELD" 8 "TEST" 9 "SNA" 10 "DIAG" ;
VAL_ 1092 PCS2_a125_lntp_state 0 "STANDBY" 1 "DRIVE" 2 "SUPPORT" 3 "CHARGE" 4 "FEIM" 5 "CLEAR_FAULT" 6 "FAULT" 7 "WELD" 8 "TEST" 9 "SNA" 10 "DIAG" ;
VAL_ 1092 PCS2_alertID 0 "ALERT_DO_NOT_USE_ZERO" 1 "a001_DriverDoorOpen" 2 "a002_DoorOpen" 3 "a003_TrunkOpen" 4 "a004_FrunkOpen" 5 "a005_HeadlightsOnDoorOpen" 6 "a006_RemoteServiceAlert" 7 "a007_SoftPackConfigMismatch" 8 "a008_TouchScreenError" 9 "a009_SquashfsError" 10 "a010_MapsMissing" 11 "a011_IncorrectMap" 12 "a012_NotOnPrivateProperty" 13 "a013_TPMSHardWarning" 14 "a014_TPMSSoftWarning" 15 "a015_TPMSOverPressureWarning" 16 "a016_TPMSTemperatureWarning" 17 "a017_TPMSSystemFault" 18 "a018_SlipStartOn" 19 "a019_ParkBrakeFault" 20 "a020_SteeringReduced" 21 "a021_RearSeatbeltUnbuckled" 22 "a022_ApeFusesEtc" 23 "a023_CellInternetCheckFailed" 24 "a024_WifiInternetCheckFailed" 25 "a025_WifiOnlineCheckFailed" 26 "a026_ModemResetLoopDetected" 27 "a027_AutoSteerMIA" 28 "a028_FrontTrunkPopupClosed" 29 "a029_ModemMIA" 30 "a030_ModemVMCrash" 31 "a031_BrakeFluidLow" 32 "a032_CellModemRecoveryResets" 33 "a033_ApTrialExpired" 34 "a034_WakeupProblem" 35 "a035_AudioWatchdogKernelError" 36 "a036_AudioWatchdogHfpError" 37 "a037_AudioWatchdogXrunStormError" 38 "a038_AudioWatchdogA2bI2cLockupError" 39 "a039_AudioA2bNeedRediscovery" 40 "a040_HomelinkTransmit" 41 "a041_AudioDmesgXrun" 42 "a042_AudioDmesgRtThrottling" 43 "a043_InvalidMapDataOverride" 44 "a044_AudioDmesgDspException" 45 "a045_ECallNeedsService" 46 "a046_BackupCameraStreamError" 47 "a047_CellRoamingDisallowed" 48 "a048_AudioPremiumAmpCheckFailed" 49 "a049_BrakeShiftRequired" 50 "a050_BackupCameraIPUTimeout" 51 "a051_BackupCameraFrameTimeout" 52 "a052_KernelPanicReported" 53 "a053_QtCarExitError" 54 "a054_AudioBoostPowerBad" 55 "a055_ManualECallDisabled" 56 "a056_ManualECallButtonDisconnected" 57 "a057_CellAntennaDisconnected" 58 "a058_GPSAntennaDisconnected" 59 "a059_ECallSpeakerDisconnected" 60 "a060_ECallMicDisconnected" 61 "a061_SIMTestFailed" 62 "a062_ENSTestFailed" 63 "a063_CellularTestFailed" 64 "a064_ModemFirmwareTestFailed" 65 "a065_WiFiRecoveryReset" 66 "a066_GpuHangDetected" 67 "a067_WarnOnI915" 68 "a068_VideoUnexpectedExit" 69 "a069_VideoUDPTimeout" 70 "a070_VideoPipelineWarning" 71 "a071_VideoPipelineError" 72 "a072_ECallAnalogMicFailed" 73 "a073_ECallDigitalMicFailed" 74 "a074_EMMCHangDetected" 75 "a075_BackupCameraInitError" 76 "a076_NumFalseManualECalls" 77 "a077_AudioA2bMicChannelSwap" 78 "a078_DashcamUsbDriveUnmountable" 79 "a079_DashcamUsbDriveFull" 80 "a080_DashcamUsbDriveSlow" 81 "a081_CellModemSearchExpired" 82 "a082_NumModemRebootStuckInECall" 83 "a083_ECallProxyWatchdogTriggered" 84 "a084_SerializerError" 85 "a085_DeserializerError" 86 "a086_TouchEnumerationError" 87 "a087_BmpReset" 88 "a088_CellRemovableSimMissing" 89 "a089_RadioSoftResetError" 90 "a090_RadioPingFailError" 91 "a091_VehicleLinkStall" 92 "a092_updateStarted" 93 "a093_updateEnded" 94 "a094_ModemPowerOnFailure" 95 "a095_CidStorageRunningLow" 96 "a096_VideodPipelineIssueDetected" 97 "a097_AudiodRestarted" 98 "a098_DiskCheckFailure" 99 "a099_eMMCStatusError" 100 "a100_eMMCFTLError" 101 "a101_wifiStackProblem" 102 "a102_A2bDiscoveryFailed" 103 "a103_UsbHubNotEnumerating" 104 "a104_DashcamUsbDriveMissing" 105 "a105_firmwareReinstallRequested" 106 "a106_rebootBackstopTriggered" 107 "a107_DashcamUsbDriveTooBigForVfatFsck" 108 "a108_DashcamUsbDriveGettingFull" 109 "a109_DashcamUsbDriveTooSmall" 110 "a110_DashcamUsbDriveCorrupt" 111 "a111_DashcamUsbDriveWrongPort" 112 "a112_badUSBDevice" 113 "a113_DashcamHasOnboardSentryClips" ;
CM_ BO_ 1106 "ESP32-DualCAN Model3_VEH. Seen on this car: 3-byte frames; fit ok (bits covered 100%, mux 100%, ranges 100%).";
CM_ BO_ 1107 "ESP32-DualCAN Model3_VEH. Seen on this car: 4-byte frames; fit ok (bits covered 100%, mux 100%, ranges 100%).";
CM_ BO_ 1114 "ESP32-DualCAN Model3_VEH. Seen on this car: 8-byte frames; fit good (bits covered 100%, mux 100%, ranges 100%).";
VAL_ 1114 VCRIGHT_AP_tempDuctDefrost 255 "SNA" ;
VAL_ 1114 VCRIGHT_AP_hvacAirDistributionMode 0 "NONE" 1 "FLOOR" 2 "PANEL" 3 "PANEL_FLOOR" 4 "DEFROST" 5 "DEFROST_FLOOR" 6 "DEFROST_PANEL" 7 "DEFROST_PANEL_FLOOR" ;
VAL_ 1114 VCRIGHT_AP_cabinTempSideGlassLeft 255 "SNA" ;
VAL_ 1114 VCRIGHT_AP_cabinTempSideGlassRight 255 "SNA" ;
VAL_ 1114 VCRIGHT_AP_cabinTempWindshield 255 "SNA" ;
VAL_ 1114 VCRIGHT_AP_hvacModelInitStatus 0 "NOT_INIT_WAIT_FOR_SENSORS" 1 "NOT_INIT_WAIT_FOR_GTW" 2 "INIT_FROM_SENSORS" 3 "INIT_FROM_SENSORS_PREDICTION_ERROR" 4 "INIT_FORWARD_CALC" 5 "INIT_WAITING_FOR_SENSORS" ;
CM_ BO_ 1115 "ESP32-DualCAN Model3_VEH. Seen on this car: 2-byte frames; fit poor (bits covered 0%, mux 100%, ranges 100%).";
CM_ BO_ 1116 "ESP32-DualCAN Model3_VEH. Not seen on this car in the logs.";
VAL_ 1116 CC_a010_line3Voltage 511 "SNA" ;
VAL_ 1116 CC_a036_line3Voltage 511 "SNA" ;
VAL_ 1116 CC_a010_line2Voltage 511 "SNA" ;
VAL_ 1116 CC_a036_line2Voltage 511 "SNA" ;
VAL_ 1116 CC_a010_line1Voltage 511 "SNA" ;
VAL_ 1116 CC_a036_line1Voltage 511 "SNA" ;
VAL_ 1116 CC_alertID 0 "ALERT_DO_NOT_USE_ZERO" 1 "a001_DriverDoorOpen" 2 "a002_DoorOpen" 3 "a003_TrunkOpen" 4 "a004_FrunkOpen" 5 "a005_HeadlightsOnDoorOpen" 6 "a006_RemoteServiceAlert" 7 "a007_SoftPackConfigMismatch" 8 "a008_TouchScreenError" 9 "a009_SquashfsError" 10 "a010_MapsMissing" 11 "a011_IncorrectMap" 12 "a012_NotOnPrivateProperty" 13 "a013_TPMSHardWarning" 14 "a014_TPMSSoftWarning" 15 "a015_TPMSOverPressureWarning" 16 "a016_TPMSTemperatureWarning" 17 "a017_TPMSSystemFault" 18 "a018_SlipStartOn" 19 "a019_ParkBrakeFault" 20 "a020_SteeringReduced" 21 "a021_RearSeatbeltUnbuckled" 22 "a022_ApeFusesEtc" 23 "a023_CellInternetCheckFailed" 24 "a024_WifiInternetCheckFailed" 25 "a025_WifiOnlineCheckFailed" 26 "a026_ModemResetLoopDetected" 27 "a027_AutoSteerMIA" 28 "a028_FrontTrunkPopupClosed" 29 "a029_ModemMIA" 30 "a030_ModemVMCrash" 31 "a031_BrakeFluidLow" 32 "a032_CellModemRecoveryResets" 33 "a033_ApTrialExpired" 34 "a034_WakeupProblem" 35 "a035_AudioWatchdogKernelError" 36 "a036_AudioWatchdogHfpError" 37 "a037_AudioWatchdogXrunStormError" 38 "a038_AudioWatchdogA2bI2cLockupError" 39 "a039_AudioA2bNeedRediscovery" 40 "a040_HomelinkTransmit" 41 "a041_AudioDmesgXrun" 42 "a042_AudioDmesgRtThrottling" 43 "a043_InvalidMapDataOverride" 44 "a044_AudioDmesgDspException" 45 "a045_ECallNeedsService" 46 "a046_BackupCameraStreamError" 47 "a047_CellRoamingDisallowed" 48 "a048_AudioPremiumAmpCheckFailed" 49 "a049_BrakeShiftRequired" 50 "a050_BackupCameraIPUTimeout" 51 "a051_BackupCameraFrameTimeout" 52 "a052_KernelPanicReported" 53 "a053_QtCarExitError" 54 "a054_AudioBoostPowerBad" 55 "a055_ManualECallDisabled" 56 "a056_ManualECallButtonDisconnected" 57 "a057_CellAntennaDisconnected" 58 "a058_GPSAntennaDisconnected" 59 "a059_ECallSpeakerDisconnected" 60 "a060_ECallMicDisconnected" 61 "a061_SIMTestFailed" 62 "a062_ENSTestFailed" 63 "a063_CellularTestFailed" 64 "a064_ModemFirmwareTestFailed" 65 "a065_WiFiRecoveryReset" 66 "a066_GpuHangDetected" 67 "a067_WarnOnI915" 68 "a068_VideoUnexpectedExit" 69 "a069_VideoUDPTimeout" 70 "a070_VideoPipelineWarning" 71 "a071_VideoPipelineError" 72 "a072_ECallAnalogMicFailed" 73 "a073_ECallDigitalMicFailed" 74 "a074_EMMCHangDetected" 75 "a075_BackupCameraInitError" 76 "a076_NumFalseManualECalls" 77 "a077_AudioA2bMicChannelSwap" 78 "a078_DashcamUsbDriveUnmountable" 79 "a079_DashcamUsbDriveFull" 80 "a080_DashcamUsbDriveSlow" 81 "a081_CellModemSearchExpired" 82 "a082_NumModemRebootStuckInECall" 83 "a083_ECallProxyWatchdogTriggered" 84 "a084_SerializerError" 85 "a085_DeserializerError" 86 "a086_TouchEnumerationError" 87 "a087_BmpReset" 88 "a088_CellRemovableSimMissing" 89 "a089_RadioSoftResetError" 90 "a090_RadioPingFailError" 91 "a091_VehicleLinkStall" 92 "a092_updateStarted" 93 "a093_updateEnded" 94 "a094_ModemPowerOnFailure" 95 "a095_CidStorageRunningLow" 96 "a096_VideodPipelineIssueDetected" 97 "a097_AudiodRestarted" 98 "a098_DiskCheckFailure" 99 "a099_eMMCStatusError" 100 "a100_eMMCFTLError" 101 "a101_wifiStackProblem" 102 "a102_A2bDiscoveryFailed" 103 "a103_UsbHubNotEnumerating" 104 "a104_DashcamUsbDriveMissing" 105 "a105_firmwareReinstallRequested" 106 "a106_rebootBackstopTriggered" 107 "a107_DashcamUsbDriveTooBigForVfatFsck" 108 "a108_DashcamUsbDriveGettingFull" 109 "a109_DashcamUsbDriveTooSmall" 110 "a110_DashcamUsbDriveCorrupt" 111 "a111_DashcamUsbDriveWrongPort" 112 "a112_badUSBDevice" 113 "a113_DashcamHasOnboardSentryClips" ;
CM_ BO_ 1117 "ESP32-DualCAN Model3_VEH. Not seen on this car in the logs.";
VAL_ 1117 FC_evseBillingDataSelect 0 "0" 1 "1" ;
CM_ BO_ 1118 "ESP32-DualCAN Model3_VEH. Not seen on this car in the logs.";
CM_ BO_ 1119 "ESP32-DualCAN Model3_VEH. Not seen on this car in the logs.";
CM_ BO_ 1121 "ESP32-DualCAN Model3_VEH. Not seen on this car in the logs.";
CM_ BO_ 1122 "ESP32-DualCAN Model3_VEH. Not seen on this car in the logs.";
CM_ BO_ 1138 "ESP32-DualCAN Model3_VEH. Seen on this car: 8-byte frames; fit good (bits covered 100%, mux 100%, ranges 100%).";
CM_ BO_ 1140 "ESP32-DualCAN Model3_VEH. Not seen on this car in the logs.";
CM_ BO_ 1145 "ESP32-DualCAN Model3_VEH. Not seen on this car in the logs.";
CM_ BO_ 1149 "ESP32-DualCAN Model3_CH. Seen on this car: 8-byte frames; fit good (bits covered 100%, mux 100%, ranges 100%).";
CM_ BO_ 1151 "ESP32-DualCAN Model3_CH. Seen on this car: 8-byte frames; fit weak (bits covered 0%, mux 100%, ranges 100%).";
CM_ BO_ 1154 "ESP32-DualCAN Model3_VEH. Seen on this car: 8-byte frames; fit ok (bits covered 100%, mux 100%, ranges 100%).";
CM_ BO_ 1160 "ESP32-DualCAN Model3_CH. Seen on this car: 4-byte frames; fit ok (bits covered 100%, mux 100%, ranges 100%).";
CM_ BO_ 1161 "ESP32-DualCAN Model3_CH. Seen on this car: 8-byte frames; fit good (bits covered 100%, mux 100%, ranges 100%, checksum 100%).";
CM_ BO_ 1170 "ESP32-DualCAN Model3_VEH. Seen on this car: 7-byte frames; fit ok (bits covered 100%, mux 100%, ranges 100%).";
CM_ BO_ 1173 "ESP32-DualCAN Model3_VEH. Not seen on this car in the logs.";
CM_ BO_ 1175 "ESP32-DualCAN Model3_VEH. Not seen on this car in the logs.";
CM_ BO_ 1176 "ESP32-DualCAN Model3_VEH. Not seen on this car in the logs.";
CM_ BO_ 1177 "ESP32-DualCAN Model3_CH. Seen on this car: 8-byte frames; fit good (bits covered 100%, mux 100%, ranges 100%).";
CM_ BO_ 1179 "ESP32-DualCAN Model3_CH. Seen on this car: 1-byte frames; fit poor (bits covered 0%, mux 100%, ranges 100%).";
CM_ BO_ 1180 "ESP32-DualCAN Model3_CH. Not seen on this car in the logs.";
CM_ BO_ 1181 "ESP32-DualCAN Model3_VEH. Seen on this car: 7-byte frames; fit ok (bits covered 100%, mux 100%, ranges 100%).";
CM_ BO_ 1206 "ESP32-DualCAN Model3_VEH. Not seen on this car in the logs.";
CM_ BO_ 1210 "ESP32-DualCAN Model3_VEH. Not seen on this car in the logs.";
CM_ BO_ 1214 "ESP32-DualCAN Model3_VEH. Not seen on this car in the logs.";
CM_ BO_ 1215 "ESP32-DualCAN Model3_VEH. Not seen on this car in the logs.";
CM_ BO_ 1233 "ESP32-DualCAN Model3_CH. Seen on this car: 8-byte frames; fit weak (bits covered 0%, mux 100%, ranges 100%).";
CM_ BO_ 1246 "ESP32-DualCAN Model3_VEH. Not seen on this car in the logs.";
CM_ BO_ 1249 "ESP32-DualCAN Model3_CH. Seen on this car: 8-byte frames; fit good (bits covered 100%, mux 100%, ranges 100%).";
VAL_ 1249 RCM2_a001_nearDeployRight 0 "INACTIVE" 1 "ACTIVE" 3 "SNA" ;
VAL_ 1249 RCM2_a001_nearDeployLeft 0 "INACTIVE" 1 "ACTIVE" 3 "SNA" ;
VAL_ 1249 RCM2_a001_nearDeployRear 0 "INACTIVE" 1 "ACTIVE" 3 "SNA" ;
VAL_ 1249 RCM2_a001_nearDeployFront 0 "INACTIVE" 1 "ACTIVE" 3 "SNA" ;
VAL_ 1249 RCM2_alertState 0 "CLEARED" 1 "SET" ;
VAL_ 1249 RCM2_alertID 0 "ALERT_DO_NOT_USE_ZERO" 1 "a001_DriverDoorOpen" 2 "a002_DoorOpen" 3 "a003_TrunkOpen" 4 "a004_FrunkOpen" 5 "a005_HeadlightsOnDoorOpen" 6 "a006_RemoteServiceAlert" 7 "a007_SoftPackConfigMismatch" 8 "a008_TouchScreenError" 9 "a009_SquashfsError" 10 "a010_MapsMissing" 11 "a011_IncorrectMap" 12 "a012_NotOnPrivateProperty" 13 "a013_TPMSHardWarning" 14 "a014_TPMSSoftWarning" 15 "a015_TPMSOverPressureWarning" 16 "a016_TPMSTemperatureWarning" 17 "a017_TPMSSystemFault" 18 "a018_SlipStartOn" 19 "a019_ParkBrakeFault" 20 "a020_SteeringReduced" 21 "a021_RearSeatbeltUnbuckled" 22 "a022_ApeFusesEtc" 23 "a023_CellInternetCheckFailed" 24 "a024_WifiInternetCheckFailed" 25 "a025_WifiOnlineCheckFailed" 26 "a026_ModemResetLoopDetected" 27 "a027_AutoSteerMIA" 28 "a028_FrontTrunkPopupClosed" 29 "a029_ModemMIA" 30 "a030_ModemVMCrash" 31 "a031_BrakeFluidLow" 32 "a032_CellModemRecoveryResets" 33 "a033_ApTrialExpired" 34 "a034_WakeupProblem" 35 "a035_AudioWatchdogKernelError" 36 "a036_AudioWatchdogHfpError" 37 "a037_AudioWatchdogXrunStormError" 38 "a038_AudioWatchdogA2bI2cLockupError" 39 "a039_AudioA2bNeedRediscovery" 40 "a040_HomelinkTransmit" 41 "a041_AudioDmesgXrun" 42 "a042_AudioDmesgRtThrottling" 43 "a043_InvalidMapDataOverride" 44 "a044_AudioDmesgDspException" 45 "a045_ECallNeedsService" 46 "a046_BackupCameraStreamError" 47 "a047_CellRoamingDisallowed" 48 "a048_AudioPremiumAmpCheckFailed" 49 "a049_BrakeShiftRequired" 50 "a050_BackupCameraIPUTimeout" 51 "a051_BackupCameraFrameTimeout" 52 "a052_KernelPanicReported" 53 "a053_QtCarExitError" 54 "a054_AudioBoostPowerBad" 55 "a055_ManualECallDisabled" 56 "a056_ManualECallButtonDisconnected" 57 "a057_CellAntennaDisconnected" 58 "a058_GPSAntennaDisconnected" 59 "a059_ECallSpeakerDisconnected" 60 "a060_ECallMicDisconnected" 61 "a061_SIMTestFailed" 62 "a062_ENSTestFailed" 63 "a063_CellularTestFailed" 64 "a064_ModemFirmwareTestFailed" 65 "a065_WiFiRecoveryReset" 66 "a066_GpuHangDetected" 67 "a067_WarnOnI915" 68 "a068_VideoUnexpectedExit" 69 "a069_VideoUDPTimeout" 70 "a070_VideoPipelineWarning" 71 "a071_VideoPipelineError" 72 "a072_ECallAnalogMicFailed" 73 "a073_ECallDigitalMicFailed" 74 "a074_EMMCHangDetected" 75 "a075_BackupCameraInitError" 76 "a076_NumFalseManualECalls" 77 "a077_AudioA2bMicChannelSwap" 78 "a078_DashcamUsbDriveUnmountable" 79 "a079_DashcamUsbDriveFull" 80 "a080_DashcamUsbDriveSlow" 81 "a081_CellModemSearchExpired" 82 "a082_NumModemRebootStuckInECall" 83 "a083_ECallProxyWatchdogTriggered" 84 "a084_SerializerError" 85 "a085_DeserializerError" 86 "a086_TouchEnumerationError" 87 "a087_BmpReset" 88 "a088_CellRemovableSimMissing" 89 "a089_RadioSoftResetError" 90 "a090_RadioPingFailError" 91 "a091_VehicleLinkStall" 92 "a092_updateStarted" 93 "a093_updateEnded" 94 "a094_ModemPowerOnFailure" 95 "a095_CidStorageRunningLow" 96 "a096_VideodPipelineIssueDetected" 97 "a097_AudiodRestarted" 98 "a098_DiskCheckFailure" 99 "a099_eMMCStatusError" 100 "a100_eMMCFTLError" 101 "a101_wifiStackProblem" 102 "a102_A2bDiscoveryFailed" 103 "a103_UsbHubNotEnumerating" 104 "a104_DashcamUsbDriveMissing" 105 "a105_firmwareReinstallRequested" 106 "a106_rebootBackstopTriggered" 107 "a107_DashcamUsbDriveTooBigForVfatFsck" 108 "a108_DashcamUsbDriveGettingFull" 109 "a109_DashcamUsbDriveTooSmall" 110 "a110_DashcamUsbDriveCorrupt" 111 "a111_DashcamUsbDriveWrongPort" 112 "a112_badUSBDevice" 113 "a113_DashcamHasOnboardSentryClips" ;
CM_ BO_ 1252 "ESP32-DualCAN Model3_CH. Not seen on this car in the logs.";
VAL_ 1252 RCM3_alertState 0 "CLEARED" 1 "SET" ;
VAL_ 1252 RCM3_alertID 0 "ALERT_DO_NOT_USE_ZERO" 1 "a001_DriverDoorOpen" 2 "a002_DoorOpen" 3 "a003_TrunkOpen" 4 "a004_FrunkOpen" 5 "a005_HeadlightsOnDoorOpen" 6 "a006_RemoteServiceAlert" 7 "a007_SoftPackConfigMismatch" 8 "a008_TouchScreenError" 9 "a009_SquashfsError" 10 "a010_MapsMissing" 11 "a011_IncorrectMap" 12 "a012_NotOnPrivateProperty" 13 "a013_TPMSHardWarning" 14 "a014_TPMSSoftWarning" 15 "a015_TPMSOverPressureWarning" 16 "a016_TPMSTemperatureWarning" 17 "a017_TPMSSystemFault" 18 "a018_SlipStartOn" 19 "a019_ParkBrakeFault" 20 "a020_SteeringReduced" 21 "a021_RearSeatbeltUnbuckled" 22 "a022_ApeFusesEtc" 23 "a023_CellInternetCheckFailed" 24 "a024_WifiInternetCheckFailed" 25 "a025_WifiOnlineCheckFailed" 26 "a026_ModemResetLoopDetected" 27 "a027_AutoSteerMIA" 28 "a028_FrontTrunkPopupClosed" 29 "a029_ModemMIA" 30 "a030_ModemVMCrash" 31 "a031_BrakeFluidLow" 32 "a032_CellModemRecoveryResets" 33 "a033_ApTrialExpired" 34 "a034_WakeupProblem" 35 "a035_AudioWatchdogKernelError" 36 "a036_AudioWatchdogHfpError" 37 "a037_AudioWatchdogXrunStormError" 38 "a038_AudioWatchdogA2bI2cLockupError" 39 "a039_AudioA2bNeedRediscovery" 40 "a040_HomelinkTransmit" 41 "a041_AudioDmesgXrun" 42 "a042_AudioDmesgRtThrottling" 43 "a043_InvalidMapDataOverride" 44 "a044_AudioDmesgDspException" 45 "a045_ECallNeedsService" 46 "a046_BackupCameraStreamError" 47 "a047_CellRoamingDisallowed" 48 "a048_AudioPremiumAmpCheckFailed" 49 "a049_BrakeShiftRequired" 50 "a050_BackupCameraIPUTimeout" 51 "a051_BackupCameraFrameTimeout" 52 "a052_KernelPanicReported" 53 "a053_QtCarExitError" 54 "a054_AudioBoostPowerBad" 55 "a055_ManualECallDisabled" 56 "a056_ManualECallButtonDisconnected" 57 "a057_CellAntennaDisconnected" 58 "a058_GPSAntennaDisconnected" 59 "a059_ECallSpeakerDisconnected" 60 "a060_ECallMicDisconnected" 61 "a061_SIMTestFailed" 62 "a062_ENSTestFailed" 63 "a063_CellularTestFailed" 64 "a064_ModemFirmwareTestFailed" 65 "a065_WiFiRecoveryReset" 66 "a066_GpuHangDetected" 67 "a067_WarnOnI915" 68 "a068_VideoUnexpectedExit" 69 "a069_VideoUDPTimeout" 70 "a070_VideoPipelineWarning" 71 "a071_VideoPipelineError" 72 "a072_ECallAnalogMicFailed" 73 "a073_ECallDigitalMicFailed" 74 "a074_EMMCHangDetected" 75 "a075_BackupCameraInitError" 76 "a076_NumFalseManualECalls" 77 "a077_AudioA2bMicChannelSwap" 78 "a078_DashcamUsbDriveUnmountable" 79 "a079_DashcamUsbDriveFull" 80 "a080_DashcamUsbDriveSlow" 81 "a081_CellModemSearchExpired" 82 "a082_NumModemRebootStuckInECall" 83 "a083_ECallProxyWatchdogTriggered" 84 "a084_SerializerError" 85 "a085_DeserializerError" 86 "a086_TouchEnumerationError" 87 "a087_BmpReset" 88 "a088_CellRemovableSimMissing" 89 "a089_RadioSoftResetError" 90 "a090_RadioPingFailError" 91 "a091_VehicleLinkStall" 92 "a092_updateStarted" 93 "a093_updateEnded" 94 "a094_ModemPowerOnFailure" 95 "a095_CidStorageRunningLow" 96 "a096_VideodPipelineIssueDetected" 97 "a097_AudiodRestarted" 98 "a098_DiskCheckFailure" 99 "a099_eMMCStatusError" 100 "a100_eMMCFTLError" 101 "a101_wifiStackProblem" 102 "a102_A2bDiscoveryFailed" 103 "a103_UsbHubNotEnumerating" 104 "a104_DashcamUsbDriveMissing" 105 "a105_firmwareReinstallRequested" 106 "a106_rebootBackstopTriggered" 107 "a107_DashcamUsbDriveTooBigForVfatFsck" 108 "a108_DashcamUsbDriveGettingFull" 109 "a109_DashcamUsbDriveTooSmall" 110 "a110_DashcamUsbDriveCorrupt" 111 "a111_DashcamUsbDriveWrongPort" 112 "a112_badUSBDevice" 113 "a113_DashcamHasOnboardSentryClips" ;
CM_ BO_ 1267 "ESP32-DualCAN Model3_VEH. Seen on this car: 4-byte frames; fit poor (bits covered 0%, mux 100%, ranges 100%).";
